VERSION ""

NS_ :

BS_:

BU_: EBOOST_CE TRCM_CE CGM_CE EPS_JR_CE MSB1_CE MSB2_CE ARS_CE SDM_CE EBCM_OBD_CE HCP_T_CE LCMS_CE APA_CE HCP_CE EOCM_F_CE MCP_C_CE MCP_B_CE MCP_A_CE FCM_CE ICCM_CE Dummy_CE TestTool_CE ACC_CE RDCM_CE EBCM_CE SADS_CE IMU_CE SAS_CE EPS_CE
VAL_TABLE_ vt_BooleanValues 1 "true" 0 "false" ;
VAL_TABLE_ RCMDSB_DTCStat 7 "Unused and Reserved3" 6 "Unused and Reserved2" 5 "Unused and Reserved1" 4 "Diagnostic Failed" 3 "Diagnostic Passed" 2 "No Status to Report" 1 "Critically Disabled" 0 "Not Supported " ;
VAL_TABLE_ RCMDSA_DTCStat 7 "Unused and Reserved3" 6 "Unused and Reserved2" 5 "Unused and Reserved1" 4 "Diagnostic Failed" 3 "Diagnostic Passed" 2 "No Status to Report" 1 "Critically Disabled" 0 "Not Supported " ;
VAL_TABLE_ RCMCII_DataIndx 31 "Unused and Reserved12" 30 "Unused and Reserved11" 29 "Unused and Reserved10" 28 "Unused and Reserved9" 27 "Unused and Reserved8" 26 "Unused and Reserved7" 25 "Unused and Reserved6" 24 "Unused and Reserved5" 23 "Unused and Reserved4" 22 "Unused and Reserved3" 21 "Unused and Reserved2" 20 "Unused and Reserved1" 19 "CVN Digit 4" 18 "CVN Digit 3" 17 "CVN Digit 2" 16 "CVN Digit 1" 15 "Calibration Identification Digit 16" 14 "Calibration Identification Digit 15" 13 "Calibration Identification Digit 14" 12 "Calibration Identification Digit 13" 11 "Calibration Identification Digit 12" 10 "Calibration Identification Digit 11" 9 "Calibration Identification Digit 10" 8 "Calibration Identification Digit 9" 7 "Calibration Identification Digit 8" 6 "Calibration Identification Digit 7" 5 "Calibration Identification Digit 6" 4 "Calibration Identification Digit 5" 3 "Calibration Identification Digit 4" 2 "Calibration Identification Digit 3" 1 "Calibration Identification Digit 2" 0 "Calibration Identification Digit 1" ;
VAL_TABLE_ RCMCII_DataStat 1 "Data Available" 0 "Data Not Available" ;
VAL_TABLE_ RMPS_RngMtrDfltStat 3 "Default Functionality" 2 "Degraded Functionality" 1 "Full Functionality" 0 "Status Unknown " ;
VAL_TABLE_ RMPS_RngMtrPstnM 1 "Use data" 0 "Do not use data" ;
VAL_TABLE_ RMPS_RngMtrPstn 15 "Unused and Reserved4" 14 "Unused and Reserved3" 13 "Unused and Reserved2" 12 "Unused and Reserved1" 11 "Beyond Drive Reset" 10 "Drive Reset" 9 "Between Drive and Drive Reset" 8 "Drive" 7 "Between Neutral and Drive" 6 "Neutral" 5 "Between Reverse and Neutral" 4 "Reverse" 3 "Between Park and Reverse" 2 "Park" 1 "Beyond Park" 0 "Motor Position Unavailable " ;
VAL_TABLE_ ElcShftActnRngCmd 7 "Unused and Reserved2" 6 "Unused and Reserved1" 5 "Drive Reset" 4 "Drive " 3 "Neutral" 2 "Reverse" 1 "Park" 0 "No Action " ;
VAL_TABLE_ EBrkAstToBrkSysDiagMd 3 "Diagnostic Mode 3" 2 "Diagnostic Mode 2" 1 "Diagnostic Mode 1" 0 "No Diagnostic Mode" ;
VAL_TABLE_ EBrkAstOtptRdPosStat 2 "Faulted" 1 "Not Initialized" 0 "Normal" ;
VAL_TABLE_ BrkSysToEBOOSTDiagMd 3 "Diagnostic Mode 3" 2 "Diagnostic Mode 2" 1 "Diagnostic Mode 1" 0 "No Diagnostic Mode" ;
VAL_TABLE_ APABR_AutBrkRmpRt 2 "Full" 1 "Light" 0 "None" ;
VAL_TABLE_ APABR_AutBrkRqTyp 8 "Object Detected/Confirmation" 7 "Reserved" 6 "Reserved" 5 "Hold" 4 "Apply Park Brake" 3 "Brake Per Requested Decel" 2 "Reserved" 1 "Prefill" 0 "None" ;
VAL_TABLE_ APABR_APA2Pstat 4 "Active" 3 "Enabled" 2 "Standby enabled" 1 "Disabled" 0 "Off" ;
VAL_TABLE_ BrkSyFrcBdgTgtRqActSt 2 "Active" 1 "Hold" 0 "Inactive" ;
VAL_TABLE_ SeatBltPerfMdRq 7 "Performance Mode 7" 6 "Performance Mode 6" 5 "Performance Mode 5" 4 "Performance Mode 4" 3 "Performance Mode 3" 2 "Performance Mode 2" 1 "Performance Mode 1" 0 "No Action" ;
VAL_TABLE_ ARSAnglCmdAct 3 "Active" 2 "Unused" 1 "Inactive with Energy Saving" 0 "Inactive" ;
VAL_TABLE_ EBrkAstStat 7 "Faulted" 6 "Temporarily Failed" 5 "Not Used" 4 "Not Used" 3 "Not Used" 2 "Normal" 1 "Initializing" 0 "Not Initialized" ;
VAL_TABLE_ StgSysPerfMdRq 7 "Performance Mode 7" 6 "Performance Mode 6" 5 "Performance Mode 5" 4 "Performance Mode 4" 3 "Performance Mode 3" 2 "Performance Mode 2" 1 "Performance Mode 1" 0 "No Action" ;
VAL_TABLE_ ChsSysTrnsShfBhvRq 7 "Upshift" 6 "Downshift" 5 "Minimum Inertia" 4 "Immediate Mode" 3 "Inhibit Shift" 2 "Inhibit Upshift" 1 "Inhibit Downshift" 0 "No Action" ;
VAL_TABLE_ RatDiagnAutoBrkReq 0 "True" 1 "False" ;
VAL_TABLE_ RatDiagnAutoBrkReqTyp 5 "Hold" 0 "None" 1 "Light" 2 "Virtual Bumper" 3 "Full" 4 "Integrated Brake Assist" ;
VAL_TABLE_ RrAxlSta 3 "Permanently Failed" 2 "Temporary Limited" 1 "Temporary Inhibit" 0 "Normal" ;
VAL_TABLE_ SecAxlStat 3 "Permanently Failed" 2 "Temporary Limited" 1 "Temporary Inhibit" 0 "Normal" ;
VAL_TABLE_ SecAxlCtrlMod 1 "External" 0 "Internal" ;
VAL_TABLE_ RrAxlOpeMod 3 "Unknown" 2 "Locked" 1 "Active" 0 "Open" ;
VAL_TABLE_ RrAxlCtrlMod 1 "External" 0 "Internal" ;
VAL_TABLE_ TransTUDMdStat 2 "Electronic Range Select Active" 1 "Driver Shift Control Active" 0 "No Activation" ;
VAL_TABLE_ TrnShftPtrnActStat 6 "PT Protection Pattern Active" 5 "PT Non-Protection Pattern Active" 4 "Shift Pattern 4 Active" 3 "Shift Pattern 3 Active" 2 "Shift Pattern 2 Active" 1 "Shift Pattern 1 Active" 0 "Default Shift Pattern Active" ;
VAL_TABLE_ NotEventSta 2 "Pretensioner Deployment Event" 1 "Near Deployment Event" 0 "No Event" 3 "Airbag Deployment Event" ;
VAL_TABLE_ SASCalRq 1 "Calibrate Sensor" 0 "No Action" ;
VAL_TABLE_ VDAvailability 1 "VirtualDeviceAvailable" 0 "VirtualDeviceUnavailable" ;
VAL_TABLE_ DistRollCntAvgDrvnM 1 "Use Data" 0 "Don't Use Data" ;
VAL_TABLE_ VhDynRRWhlSt 2 "Exiting Active" 1 "Active" 0 "Inactive" ;
VAL_TABLE_ VhDynRLWhlSt 2 "Exiting Active" 1 "Active" 0 "Inactive" ;
VAL_TABLE_ VhDynFRWhlSt 2 "Exiting Active" 1 "Active" 0 "Inactive" ;
VAL_TABLE_ VhDynFLWhlSt 2 "Exiting Active" 1 "Active" 0 "Inactive" ;
VAL_TABLE_ VehStabEnhmntMd 2 "Competitive" 1 "Normal" 0 "Off" ;
VAL_TABLE_ VehStabEnhmntStat 4 "Not Ready" 3 "Warming Up" 2 "Fault" 1 "Active" 0 "Inactive" ;
VAL_TABLE_ DTCI_DTCFaultType 3 "Type C" 2 "Type B" 1 "Type A" 0 "Not Supported" ;
VAL_TABLE_ DistRollCntAvgDrvnSrc 1 "Wheel Speed" 0 "Transmission Output Speed" ;
VAL_TABLE_ VehSpdAvgDrvnSrc 1 "Wheel Speed" 0 "Transmission Output Speed" ;
VAL_TABLE_ TrnsSftMdStat 3 "Automatic Grade Braking Mode" 2 "Lift-Foot Cornering Mode" 1 "Performance Mode" 0 "No Override Mode" ;
VAL_TABLE_ StrWhlAngSenCalStat 2 "Calibrated" 1 "Estimated" 0 "Unknown" ;
VAL_TABLE_ EngSpdStat 3 "Invalid" 1 "Degraded Operation" 0 "Normal Operation" ;
VAL_TABLE_ TrnsShftLvrPos 15 "Lever Position Unknown" 11 "Forward Range H" 10 "Forward Range G" 9 "Forward Range F" 8 "Forward Range E" 7 "Forward Range D" 6 "Forward Range C" 5 "Forward Range B" 4 "Forward Range A" 3 "Neutral Range" 2 "Reverse Range" 1 "Park Range" 0 "Between Ranges" ;
VAL_TABLE_ TransEstGear 15 "Park Gear" 14 "Reverse Gear" 13 "Neutral Gear" 12 "CVT Forward Gear" 11 "EVT Mode 2" 10 "EVT Mode 1" 8 "Eighth Gear" 7 "Seventh Gear" 6 "Sixth Gear" 5 "Fifth Gear" 4 "Fourth Gear" 3 "Third Gear" 2 "Second Gear" 1 "First Gear" 0 "Not Supported" ;
VAL_TABLE_ SysBkUpPwrMd 3 "Crank Request" 2 "Run" 1 "Accessory" 0 "Off" ;
VAL_TABLE_ SysPwrMd 3 "Crank Request" 2 "Run" 1 "Accessory" 0 "Off" ;
VAL_TABLE_ SprTireSt 2 "Spare Detected" 1 "No Spare Detected" 0 "Undetermined" ;
VAL_TABLE_ VhDynCntlSysSt 7 "Driver Disabled" 6 "Enhanced Operation" 5 "Calibrating" 4 "Warming Up" 3 "Permanently Failed" 2 "Temporarily Inhibited" 1 "Reduced Function" 0 "Normal Operation" ;
VAL_TABLE_ ValidityStates 1 "Invalid" 0 "Valid" ;

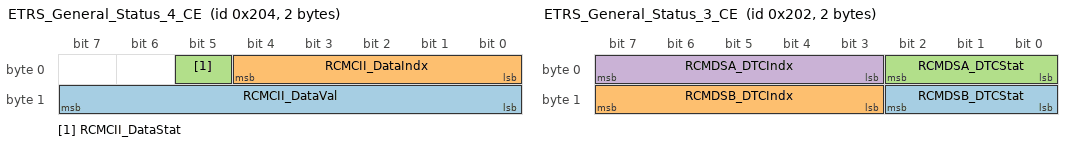
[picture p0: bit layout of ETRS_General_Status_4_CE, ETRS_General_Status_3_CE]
BO_ 516 ETRS_General_Status_4_CE: 2 TRCM_CE
 SG_ RCMCII_DataVal : 15|8@0+ (1,0) [0|255] ""  ICCM_CE
 SG_ RCMCII_DataIndx : 4|5@0+ (1,0) [0|31] ""  ICCM_CE
 SG_ RCMCII_DataStat : 5|1@0+ (1,0) [0|1] ""  ICCM_CE

BO_ 514 ETRS_General_Status_3_CE: 2 TRCM_CE
 SG_ RCMDSB_DTCStat : 10|3@0+ (1,0) [0|7] ""  ICCM_CE
 SG_ RCMDSB_DTCIndx : 15|5@0+ (1,0) [0|31] "N/A"  ICCM_CE
 SG_ RCMDSA_DTCStat : 2|3@0+ (1,0) [0|7] ""  ICCM_CE
 SG_ RCMDSA_DTCIndx : 7|5@0+ (1,0) [0|31] "N/A"  ICCM_CE

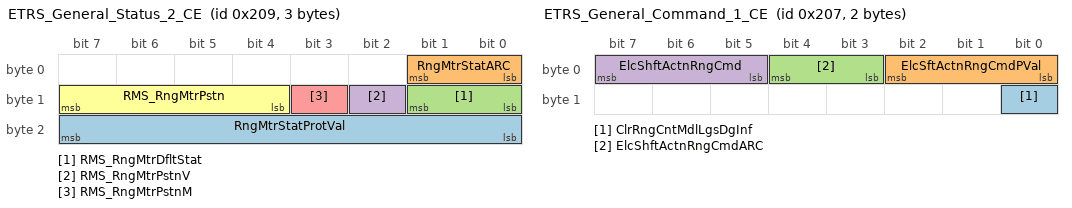
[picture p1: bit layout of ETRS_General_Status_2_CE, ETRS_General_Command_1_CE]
BO_ 521 ETRS_General_Status_2_CE: 3 TRCM_CE
 SG_ RngMtrStatProtVal : 23|8@0+ (1,0) [0|255] ""  ICCM_CE
 SG_ RngMtrStatARC : 1|2@0+ (1,0) [0|3] ""  ICCM_CE
 SG_ RMS_RngMtrDfltStat : 9|2@0+ (1,0) [0|3] ""  ICCM_CE
 SG_ RMS_RngMtrPstnV : 10|1@0+ (1,0) [0|1] ""  ICCM_CE
 SG_ RMS_RngMtrPstnM : 11|1@0+ (1,0) [0|1] ""  ICCM_CE
 SG_ RMS_RngMtrPstn : 15|4@0+ (1,0) [0|15] ""  ICCM_CE

BO_ 519 ETRS_General_Command_1_CE: 2 ICCM_CE
 SG_ ClrRngCntMdlLgsDgInf : 8|1@0+ (1,0) [0|1] ""  TRCM_CE
 SG_ ElcSftActnRngCmdPVal : 2|3@0+ (1,0) [0|7] ""  TRCM_CE
 SG_ ElcShftActnRngCmdARC : 4|2@0+ (1,0) [0|3] ""  TRCM_CE
 SG_ ElcShftActnRngCmd : 7|3@0+ (1,0) [0|7] ""  TRCM_CE

BO_ 543 Electric_Brake_System_Info_3_CE: 6 EBOOST_CE

BO_ 1931 DTC_Triggered_78B_CE: 7 SAS_CE
 SG_ DTCI_CodeSupported_78B : 40|1@0+ (1,0) [0|1] ""  TestTool_CE
 SG_ DTCI_CurrentStatus_78B : 41|1@0+ (1,0) [0|1] ""  TestTool_CE
 SG_ DTCI_DTCFailType_78B : 39|8@0+ (1,0) [0|255] ""  TestTool_CE
 SG_ DTCI_DTCFaultType_78B : 55|8@0+ (1,0) [0|255] ""  TestTool_CE
 SG_ DTCI_DTCNumber_78B : 23|16@0+ (1,0) [0|65535] ""  TestTool_CE
 SG_ DTCI_DTCSource_78B : 15|8@0+ (1,0) [0|255] ""  TestTool_CE
 SG_ DTCI_DTCTriggered_78B : 0|1@0+ (1,0) [0|1] ""  TestTool_CE
 SG_ DTCI_HistStat_78B : 44|1@0+ (1,0) [0|1] ""  TestTool_CE
 SG_ DTCI_TstFldCdClrdStat_78B : 43|1@0+ (1,0) [0|1] ""  TestTool_CE
 SG_ DTCI_TstFldPwrUpSt_78B : 46|1@0+ (1,0) [0|1] ""  TestTool_CE
 SG_ DTCI_TstNPsdCdClrdSt_78B : 42|1@0+ (1,0) [0|1] ""  TestTool_CE
 SG_ DTCI_TstNPsdPwrUpSt_78B : 45|1@0+ (1,0) [0|1] ""  TestTool_CE
 SG_ DTCIUnused1_78B : 7|1@0+ (1,0) [0|1] ""  TestTool_CE
 SG_ DTCIUnused2_78B : 6|1@0+ (1,0) [0|1] ""  TestTool_CE
 SG_ DTCIUnused3_78B : 5|1@0+ (1,0) [0|1] ""  TestTool_CE
 SG_ DTCIUnused4_78B : 4|1@0+ (1,0) [0|1] ""  TestTool_CE
 SG_ DTCIUnused5_78B : 3|1@0+ (1,0) [0|1] ""  TestTool_CE
 SG_ DTCIUnused6_78B : 2|1@0+ (1,0) [0|1] ""  TestTool_CE
 SG_ DTCIUnused7_78B : 1|1@0+ (1,0) [0|1] ""  TestTool_CE
 SG_ DTCI_WrnIndRqdSt_78B : 47|1@0+ (1,0) [0|1] ""  TestTool_CE

BO_ 1923 DTC_Triggered_783_CE: 7 MSB2_CE
 SG_ DTCI_WrnIndRqdSt_783 : 47|1@0+ (1,0) [0|1] ""  TestTool_CE
 SG_ DTCI_TstNPsdPwrUpSt_783 : 45|1@0+ (1,0) [0|1] ""  TestTool_CE
 SG_ DTCI_TstNPsdCdClrdSt_783 : 42|1@0+ (1,0) [0|1] ""  TestTool_CE
 SG_ DTCI_TstFldPwrUpSt_783 : 46|1@0+ (1,0) [0|1] ""  TestTool_CE
 SG_ DTCI_TstFldCdClrdStat_783 : 43|1@0+ (1,0) [0|1] ""  TestTool_CE
 SG_ DTCI_HistStat_783 : 44|1@0+ (1,0) [0|1] ""  TestTool_CE
 SG_ DTCI_DTCTriggered_783 : 0|1@0+ (1,0) [0|1] ""  TestTool_CE
 SG_ DTCI_DTCSource_783 : 15|8@0+ (1,0) [0|255] ""  TestTool_CE
 SG_ DTCI_DTCNumber_783 : 23|16@0+ (1,0) [0|65535] ""  TestTool_CE
 SG_ DTCI_DTCFaultType_783 : 55|8@0+ (1,0) [0|255] ""  TestTool_CE
 SG_ DTCI_DTCFailType_783 : 39|8@0+ (1,0) [0|255] ""  TestTool_CE
 SG_ DTCI_CurrentStatus_783 : 41|1@0+ (1,0) [0|1] ""  TestTool_CE
 SG_ DTCI_CodeSupported_783 : 40|1@0+ (1,0) [0|1] ""  TestTool_CE
 SG_ DTCIUnused7_783 : 1|1@0+ (1,0) [0|1] ""  TestTool_CE
 SG_ DTCIUnused6_783 : 2|1@0+ (1,0) [0|1] ""  TestTool_CE
 SG_ DTCIUnused5_783 : 3|1@0+ (1,0) [0|1] ""  TestTool_CE
 SG_ DTCIUnused4_783 : 4|1@0+ (1,0) [0|1] ""  TestTool_CE
 SG_ DTCIUnused3_783 : 5|1@0+ (1,0) [0|1] ""  TestTool_CE
 SG_ DTCIUnused2_783 : 6|1@0+ (1,0) [0|1] ""  TestTool_CE
 SG_ DTCIUnused1_783 : 7|1@0+ (1,0) [0|1] ""  TestTool_CE

BO_ 1922 DTC_Triggered_782_CE: 7 MSB1_CE
 SG_ DTCI_WrnIndRqdSt_782 : 47|1@0+ (1,0) [0|1] ""  TestTool_CE
 SG_ DTCIUnused7_782 : 1|1@0+ (1,0) [0|1] ""  TestTool_CE
 SG_ DTCIUnused6_782 : 2|1@0+ (1,0) [0|1] ""  TestTool_CE
 SG_ DTCIUnused5_782 : 3|1@0+ (1,0) [0|1] ""  TestTool_CE
 SG_ DTCIUnused4_782 : 4|1@0+ (1,0) [0|1] ""  TestTool_CE
 SG_ DTCIUnused3_782 : 5|1@0+ (1,0) [0|1] ""  TestTool_CE
 SG_ DTCIUnused2_782 : 6|1@0+ (1,0) [0|1] ""  TestTool_CE
 SG_ DTCIUnused1_782 : 7|1@0+ (1,0) [0|1] ""  TestTool_CE
 SG_ DTCI_TstNPsdPwrUpSt_782 : 45|1@0+ (1,0) [0|1] ""  TestTool_CE
 SG_ DTCI_TstNPsdCdClrdSt_782 : 42|1@0+ (1,0) [0|1] ""  TestTool_CE
 SG_ DTCI_TstFldPwrUpSt_782 : 46|1@0+ (1,0) [0|1] ""  TestTool_CE
 SG_ DTCI_TstFldCdClrdStat_782 : 43|1@0+ (1,0) [0|1] ""  TestTool_CE
 SG_ DTCI_HistStat_782 : 44|1@0+ (1,0) [0|1] ""  TestTool_CE
 SG_ DTCI_DTCTriggered_782 : 0|1@0+ (1,0) [0|1] ""  TestTool_CE
 SG_ DTCI_DTCSource_782 : 15|8@0+ (1,0) [0|255] ""  TestTool_CE
 SG_ DTCI_DTCNumber_782 : 23|16@0+ (1,0) [0|65535] ""  TestTool_CE
 SG_ DTCI_DTCFaultType_782 : 55|8@0+ (1,0) [0|255] ""  TestTool_CE
 SG_ DTCI_DTCFailType_782 : 39|8@0+ (1,0) [0|255] ""  TestTool_CE
 SG_ DTCI_CurrentStatus_782 : 41|1@0+ (1,0) [0|1] ""  TestTool_CE
 SG_ DTCI_CodeSupported_782 : 40|1@0+ (1,0) [0|1] ""  TestTool_CE

BO_ 1921 DTC_Triggered_781_CE: 7 IMU_CE
 SG_ DTCI_CurrentStatus_781 : 41|1@0+ (1,0) [0|1] ""  TestTool_CE
 SG_ DTCI_WrnIndRqdSt_781 : 47|1@0+ (1,0) [0|1] ""  TestTool_CE
 SG_ DTCIUnused7_781 : 1|1@0+ (1,0) [0|1] ""  TestTool_CE
 SG_ DTCIUnused6_781 : 2|1@0+ (1,0) [0|1] ""  TestTool_CE
 SG_ DTCIUnused5_781 : 3|1@0+ (1,0) [0|1] ""  TestTool_CE
 SG_ DTCIUnused4_781 : 4|1@0+ (1,0) [0|1] ""  TestTool_CE
 SG_ DTCIUnused3_781 : 5|1@0+ (1,0) [0|1] ""  TestTool_CE
 SG_ DTCIUnused2_781 : 6|1@0+ (1,0) [0|1] ""  TestTool_CE
 SG_ DTCIUnused1_781 : 7|1@0+ (1,0) [0|1] ""  TestTool_CE
 SG_ DTCI_TstNPsdPwrUpSt_781 : 45|1@0+ (1,0) [0|1] ""  TestTool_CE
 SG_ DTCI_TstNPsdCdClrdSt_781 : 42|1@0+ (1,0) [0|1] ""  TestTool_CE
 SG_ DTCI_TstFldPwrUpSt_781 : 46|1@0+ (1,0) [0|1] ""  TestTool_CE
 SG_ DTCI_TstFldCdClrdStat_781 : 43|1@0+ (1,0) [0|1] ""  TestTool_CE
 SG_ DTCI_HistStat_781 : 44|1@0+ (1,0) [0|1] ""  TestTool_CE
 SG_ DTCI_DTCTriggered_781 : 0|1@0+ (1,0) [0|1] ""  TestTool_CE
 SG_ DTCI_DTCSource_781 : 15|8@0+ (1,0) [0|255] ""  TestTool_CE
 SG_ DTCI_DTCNumber_781 : 23|16@0+ (1,0) [0|65535] ""  TestTool_CE
 SG_ DTCI_DTCFaultType_781 : 55|8@0+ (1,0) [0|255] ""  TestTool_CE
 SG_ DTCI_DTCFailType_781 : 39|8@0+ (1,0) [0|255] ""  TestTool_CE
 SG_ DTCI_CodeSupported_781 : 40|1@0+ (1,0) [0|1] ""  TestTool_CE

BO_ 2034 CCP_Data_Transmission_Object_CE: 8 Dummy_CE
 SG_ DgnInf : 7|64@0+ (1,0) [0|1.84467440737096E+019] ""  TestTool_CE

BO_ 2032 CCP_Command_Receive_Object_CE: 8 TestTool_CE
 SG_ DgnInf : 7|64@0+ (1,0) [0|1.84467440737096E+019] ""  Dummy_CE

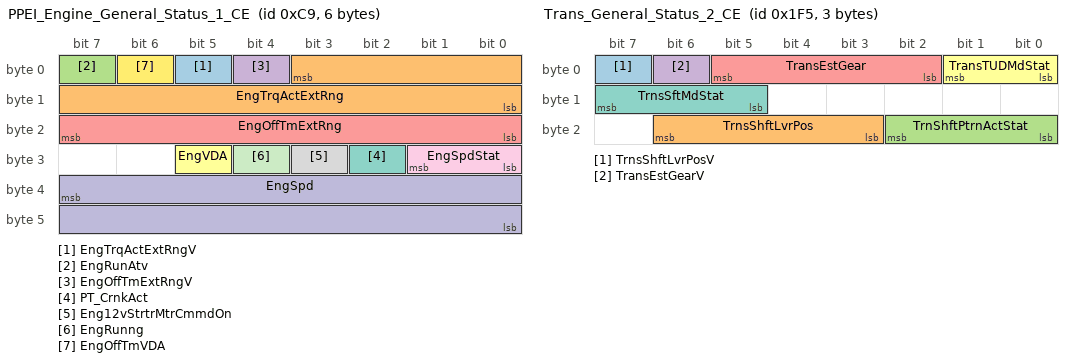
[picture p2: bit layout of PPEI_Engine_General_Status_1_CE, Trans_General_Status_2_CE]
BO_ 201 PPEI_Engine_General_Status_1_CE: 6 EBCM_CE
 SG_ EngTrqActExtRngV : 5|1@0+ (1,0) [0|1] ""  EPS_JR_CE
 SG_ EngTrqActExtRng : 3|12@0+ (0.5,-848) [-848|1199.5] "Nm"  EPS_JR_CE
 SG_ EngRunAtv : 7|1@0+ (1,0) [0|1] ""  SDM_CE,ARS_CE,EPS_JR_CE
 SG_ EngOffTmExtRngV : 4|1@0+ (1,0) [0|1] ""  RDCM_CE,EPS_JR_CE
 SG_ EngOffTmExtRng : 23|8@0+ (4,0) [0|1020] "min"  RDCM_CE,EPS_JR_CE
 SG_ EngVDA : 29|1@0+ (1,0) [0|1] ""  RDCM_CE
 SG_ PT_CrnkAct : 26|1@0+ (1,0) [0|1] ""  EPS_JR_CE
 SG_ Eng12vStrtrMtrCmmdOn : 27|1@0+ (1,0) [0|1] ""  EPS_JR_CE
 SG_ EngSpdStat : 25|2@0+ (1,0) [0|3] ""  EPS_JR_CE,ARS_CE
 SG_ EngSpd : 39|16@0+ (0.25,0) [0|16383.75] "rpm"  ARS_CE,EPS_JR_CE
 SG_ EngRunng : 28|1@0+ (1,0) [0|1] ""  RDCM_CE
 SG_ EngOffTmVDA : 6|1@0+ (1,0) [0|1] ""  EPS_JR_CE

BO_ 1300 PPEI_VIN_Digits_2_to_9_CE: 8 EBCM_CE
 SG_ VehIdNmDig2_9 : 7|64@0+ (1,0) [0|1] ""  EPS_JR_CE

BO_ 1249 PPEI_VIN_Digits_10_to_17_CE: 8 EBCM_CE
 SG_ VehIdNmDig10_17 : 7|64@0+ (1,0) [0|1] ""  EPS_JR_CE

BO_ 300 MSB2_Collision_Preparation_CE: 1 MSB2_CE
 SG_ MotStBlt2UnblIO : 0|1@0+ (1,0) [0|1] ""  MSB1_CE
 SG_ MotStBlt2FldIO : 1|1@0+ (1,0) [0|1] ""  MSB1_CE

BO_ 501 Trans_General_Status_2_CE: 3 EBCM_CE
 SG_ TrnsShftLvrPosV : 7|1@0+ (1,0) [0|1] ""  EPS_JR_CE,APA_CE
 SG_ TrnsShftLvrPos : 22|4@0+ (1,0) [0|15] ""  EPS_JR_CE,APA_CE
 SG_ TrnShftPtrnActStat : 18|3@0+ (1,0) [0|7] ""  EPS_JR_CE
 SG_ TransEstGearV : 6|1@0+ (1,0) [0|1] ""  MSB1_CE,MSB2_CE,FCM_CE,EPS_JR_CE
 SG_ TransEstGear : 5|4@0+ (1,0) [0|15] ""  MSB1_CE,MSB2_CE,FCM_CE,EPS_JR_CE
 SG_ TransTUDMdStat : 1|2@0+ (1,0) [0|3] ""  MSB1_CE,MSB2_CE
 SG_ TrnsSftMdStat : 15|3@0+ (1,0) [0|7] ""  MSB1_CE,MSB2_CE

BO_ 1920 DTC_Triggered_780_CE: 7 EPS_JR_CE
 SG_ DTCI_CurrentStatus_780 : 41|1@0+ (1,0) [0|1] ""  EBCM_OBD_CE,EBCM_CE
 SG_ DTCI_WrnIndRqdSt_780 : 47|1@0+ (1,0) [0|1] ""  EBCM_OBD_CE,EBCM_CE
 SG_ DTCIUnused7_780 : 1|1@0+ (1,0) [0|1] ""  EBCM_OBD_CE,EBCM_CE
 SG_ DTCIUnused6_780 : 2|1@0+ (1,0) [0|1] ""  EBCM_OBD_CE,EBCM_CE
 SG_ DTCIUnused5_780 : 3|1@0+ (1,0) [0|1] ""  EBCM_OBD_CE,EBCM_CE
 SG_ DTCIUnused4_780 : 4|1@0+ (1,0) [0|1] ""  EBCM_OBD_CE,EBCM_CE
 SG_ DTCIUnused3_780 : 5|1@0+ (1,0) [0|1] ""  EBCM_OBD_CE,EBCM_CE
 SG_ DTCIUnused2_780 : 6|1@0+ (1,0) [0|1] ""  EBCM_OBD_CE,EBCM_CE
 SG_ DTCIUnused1_780 : 7|1@0+ (1,0) [0|1] ""  EBCM_OBD_CE,EBCM_CE
 SG_ DTCI_TstNPsdPwrUpSt_780 : 45|1@0+ (1,0) [0|1] ""  EBCM_OBD_CE,EBCM_CE
 SG_ DTCI_TstNPsdCdClrdSt_780 : 42|1@0+ (1,0) [0|1] ""  EBCM_OBD_CE,EBCM_CE
 SG_ DTCI_TstFldPwrUpSt_780 : 46|1@0+ (1,0) [0|1] ""  EBCM_OBD_CE,EBCM_CE
 SG_ DTCI_TstFldCdClrdStat_780 : 43|1@0+ (1,0) [0|1] ""  EBCM_OBD_CE,EBCM_CE
 SG_ DTCI_HistStat_780 : 44|1@0+ (1,0) [0|1] ""  EBCM_OBD_CE,EBCM_CE
 SG_ DTCI_DTCTriggered_780 : 0|1@0+ (1,0) [0|1] ""  EBCM_OBD_CE,EBCM_CE
 SG_ DTCI_DTCSource_780 : 15|8@0+ (1,0) [0|255] ""  EBCM_OBD_CE,EBCM_CE
 SG_ DTCI_DTCNumber_780 : 23|16@0+ (1,0) [0|65535] ""  EBCM_OBD_CE,EBCM_CE
 SG_ DTCI_DTCFaultType_780 : 55|8@0+ (1,0) [0|255] ""  EBCM_OBD_CE,EBCM_CE
 SG_ DTCI_DTCFailType_780 : 39|8@0+ (1,0) [0|255] ""  EBCM_OBD_CE,EBCM_CE
 SG_ DTCI_CodeSupported_780 : 40|1@0+ (1,0) [0|1] ""  EBCM_OBD_CE,EBCM_CE

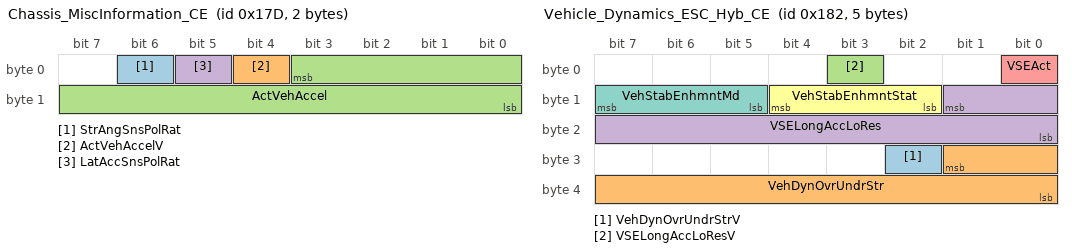
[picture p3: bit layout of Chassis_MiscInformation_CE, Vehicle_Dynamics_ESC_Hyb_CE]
BO_ 381 Chassis_MiscInformation_CE: 2 EBCM_CE
 SG_ StrAngSnsPolRat : 6|1@0+ (1,0) [0|1] ""  EPS_JR_CE,EPS_CE
 SG_ ActVehAccelV : 4|1@0+ (1,0) [0|1] ""  MSB1_CE,MSB2_CE
 SG_ ActVehAccel : 3|12@0- (0.01,0) [-20.48|20.47] "m/s^2"  MSB1_CE,MSB2_CE
 SG_ LatAccSnsPolRat : 5|1@0+ (1,0) [0|1] ""  EPS_JR_CE,EPS_CE

BO_ 386 Vehicle_Dynamics_ESC_Hyb_CE: 5 EBCM_CE
 SG_ VehDynOvrUndrStrV : 26|1@0+ (1,0) [0|1] ""  EPS_JR_CE,EPS_CE
 SG_ VehDynOvrUndrStr : 25|10@0- (0.5,0) [-256|255.5] "%"  EPS_JR_CE,EPS_CE
 SG_ VSELongAccLoResV : 3|1@0+ (1,0) [0|1] ""  EPS_CE,EPS_JR_CE
 SG_ VSELongAccLoRes : 9|10@0- (0.03,0) [-15.36|15.33] "m/s^2"  EPS_CE,EPS_JR_CE
 SG_ VSEAct : 0|1@0+ (1,0) [0|1] ""  RDCM_CE,EPS_JR_CE,MSB1_CE,MSB2_CE,EPS_CE
 SG_ VehStabEnhmntStat : 12|3@0+ (1,0) [0|7] ""  EPS_CE,MSB1_CE,MSB2_CE
 SG_ VehStabEnhmntMd : 15|3@0+ (1,0) [0|7] ""  MSB1_CE,MSB2_CE

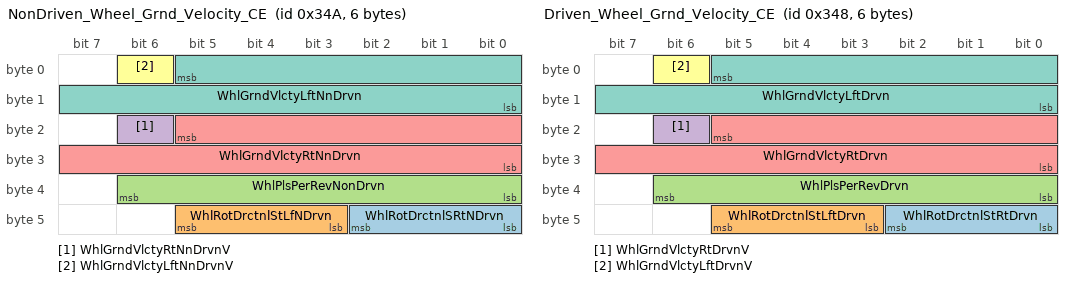
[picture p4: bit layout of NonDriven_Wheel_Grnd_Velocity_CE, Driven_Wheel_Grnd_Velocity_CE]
BO_ 842 NonDriven_Wheel_Grnd_Velocity_CE: 6 EBCM_CE
 SG_ WhlRotDrctnlSRtNDrvn : 42|3@0+ (1,0) [0|7] ""  ARS_CE,APA_CE
 SG_ WhlRotDrctnlStLfNDrvn : 45|3@0+ (1,0) [0|7] ""  ARS_CE,APA_CE
 SG_ WhlPlsPerRevNonDrvn : 38|7@0+ (1,0) [0|127] ""  ARS_CE,APA_CE,RDCM_CE,EPS_JR_CE,EPS_CE
 SG_ WhlGrndVlctyRtNnDrvnV : 22|1@0+ (1,0) [0|1] ""  ARS_CE,SDM_CE,APA_CE,EPS_JR_CE,MSB1_CE,MSB2_CE,EPS_CE
 SG_ WhlGrndVlctyRtNnDrvn : 21|14@0+ (0.03125,0) [0|511.96875] "km / h"  ARS_CE,SDM_CE,APA_CE,EPS_JR_CE,MSB1_CE,MSB2_CE,EPS_CE
 SG_ WhlGrndVlctyLftNnDrvnV : 6|1@0+ (1,0) [0|1] ""  ARS_CE,SDM_CE,EPS_JR_CE,MSB1_CE,MSB2_CE,EPS_CE,APA_CE
 SG_ WhlGrndVlctyLftNnDrvn : 5|14@0+ (0.03125,0) [0|511.96875] "km / h"  ARS_CE,SDM_CE,EPS_JR_CE,MSB1_CE,MSB2_CE,EPS_CE,APA_CE

BO_ 840 Driven_Wheel_Grnd_Velocity_CE: 6 EBCM_CE
 SG_ WhlRotDrctnlStRtDrvn : 42|3@0+ (1,0) [0|7] ""  ARS_CE,APA_CE
 SG_ WhlRotDrctnlStLftDrvn : 45|3@0+ (1,0) [0|7] ""  ARS_CE,APA_CE
 SG_ WhlPlsPerRevDrvn : 38|7@0+ (1,0) [0|127] ""  ARS_CE,APA_CE,RDCM_CE,EPS_JR_CE,EPS_CE
 SG_ WhlGrndVlctyRtDrvnV : 22|1@0+ (1,0) [0|1] ""  ARS_CE,SDM_CE,FCM_CE,EPS_JR_CE,APA_CE,MSB1_CE,MSB2_CE,EPS_CE
 SG_ WhlGrndVlctyRtDrvn : 21|14@0+ (0.03125,0) [0|511.96875] "km / h"  ARS_CE,SDM_CE,FCM_CE,EPS_JR_CE,APA_CE,MSB1_CE,MSB2_CE,EPS_CE
 SG_ WhlGrndVlctyLftDrvnV : 6|1@0+ (1,0) [0|1] ""  ARS_CE,SDM_CE,FCM_CE,EPS_JR_CE,MSB1_CE,MSB2_CE,EPS_CE,APA_CE
 SG_ WhlGrndVlctyLftDrvn : 5|14@0+ (0.03125,0) [0|511.96875] "km / h"  ARS_CE,SDM_CE,FCM_CE,EPS_JR_CE,MSB1_CE,MSB2_CE,EPS_CE,APA_CE

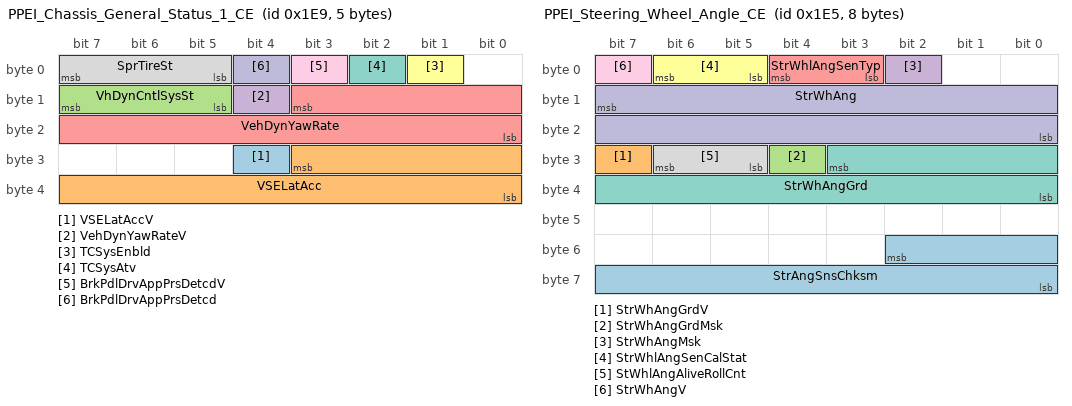
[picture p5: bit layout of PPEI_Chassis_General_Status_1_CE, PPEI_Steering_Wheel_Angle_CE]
BO_ 489 PPEI_Chassis_General_Status_1_CE: 5 EBCM_CE
 SG_ VSELatAccV : 28|1@0+ (1,0) [0|1] ""  MSB1_CE,MSB2_CE,EPS_JR_CE
 SG_ VSELatAcc : 27|12@0- (0.015625,0) [-32|31.984375] "m/s^2"  MSB1_CE,MSB2_CE,EPS_JR_CE
 SG_ VhDynCntlSysSt : 15|3@0+ (1,0) [0|7] ""  EPS_JR_CE
 SG_ VehDynYawRateV : 12|1@0+ (1,0) [0|1] ""  EPS_JR_CE,MSB1_CE,MSB2_CE
 SG_ VehDynYawRate : 11|12@0- (0.0625,0) [-128|127.9375] "deg/sec"  EPS_JR_CE,MSB1_CE,MSB2_CE
 SG_ TCSysEnbld : 1|1@0+ (1,0) [0|1] ""  EPS_JR_CE
 SG_ TCSysAtv : 2|1@0+ (1,0) [0|1] ""  EPS_JR_CE,RDCM_CE
 SG_ SprTireSt : 7|3@0+ (1,0) [0|7] ""  EPS_JR_CE
 SG_ BrkPdlDrvAppPrsDetcdV : 3|1@0+ (1,0) [0|1] ""  EPS_JR_CE
 SG_ BrkPdlDrvAppPrsDetcd : 4|1@0+ (1,0) [0|1] ""  EPS_JR_CE

BO_ 485 PPEI_Steering_Wheel_Angle_CE: 8 SAS_CE
 SG_ StrAngSnsChksm : 50|11@0+ (1,0) [0|2047] ""  ARS_CE,ACC_CE,APA_CE,FCM_CE,ICCM_CE,EPS_JR_CE,EPS_CE,EOCM_F_CE,EBCM_OBD_CE,EBCM_CE
 SG_ StrWhAngGrdV : 31|1@0+ (1,0) [0|1] ""  ARS_CE,FCM_CE,ICCM_CE,EPS_JR_CE,MSB1_CE,MSB2_CE,EPS_CE,SADS_CE,RDCM_CE,APA_CE,EOCM_F_CE,ACC_CE,SDM_CE,EBCM_OBD_CE,EBCM_CE
 SG_ StrWhAngGrdMsk : 28|1@0+ (1,0) [0|1] ""  ARS_CE,APA_CE,FCM_CE,ICCM_CE,EPS_JR_CE,EOCM_F_CE,EBCM_OBD_CE,EBCM_CE
 SG_ StrWhAngMsk : 2|1@0+ (1,0) [0|1] ""  ARS_CE,APA_CE,FCM_CE,ICCM_CE,EPS_JR_CE,EPS_CE,SADS_CE,EOCM_F_CE,SDM_CE,EBCM_OBD_CE,EBCM_CE
 SG_ StrWhlAngSenTyp : 4|2@0+ (1,0) [0|3] ""  ARS_CE,APA_CE,ACC_CE,FCM_CE,ICCM_CE,EBCM_OBD_CE,EBCM_CE,EPS_JR_CE,EPS_CE,EOCM_F_CE,SDM_CE
 SG_ StrWhlAngSenCalStat : 6|2@0+ (1,0) [0|3] ""  FCM_CE,ICCM_CE,EPS_JR_CE,ARS_CE,SADS_CE,RDCM_CE,APA_CE,EPS_CE,EOCM_F_CE,ACC_CE,SDM_CE,MSB1_CE,MSB2_CE,EBCM_OBD_CE,EBCM_CE
 SG_ StrWhAngGrd : 27|12@0- (1,0) [-2048|2047] "deg/sec"  ARS_CE,FCM_CE,ICCM_CE,EPS_JR_CE,MSB1_CE,MSB2_CE,SADS_CE,RDCM_CE,APA_CE,EPS_CE,EOCM_F_CE,ACC_CE,SDM_CE,EBCM_OBD_CE,EBCM_CE
 SG_ StWhlAngAliveRollCnt : 30|2@0+ (1,0) [0|3] ""  ARS_CE,ACC_CE,APA_CE,FCM_CE,ICCM_CE,EPS_JR_CE,EOCM_F_CE,SADS_CE,RDCM_CE,EPS_CE,SDM_CE,EBCM_OBD_CE,EBCM_CE
 SG_ StrWhAngV : 7|1@0+ (1,0) [0|1] ""  FCM_CE,ICCM_CE,EPS_JR_CE,ARS_CE,MSB1_CE,MSB2_CE,SADS_CE,RDCM_CE,APA_CE,EPS_CE,EOCM_F_CE,ACC_CE,SDM_CE,EBCM_OBD_CE,EBCM_CE
 SG_ StrWhAng : 15|16@0- (0.0625,0) [-2048|2047.9375] "deg"  ARS_CE,FCM_CE,ICCM_CE,EPS_JR_CE,MSB1_CE,MSB2_CE,SADS_CE,RDCM_CE,APA_CE,EPS_CE,EOCM_F_CE,ACC_CE,SDM_CE,EBCM_OBD_CE,EBCM_CE

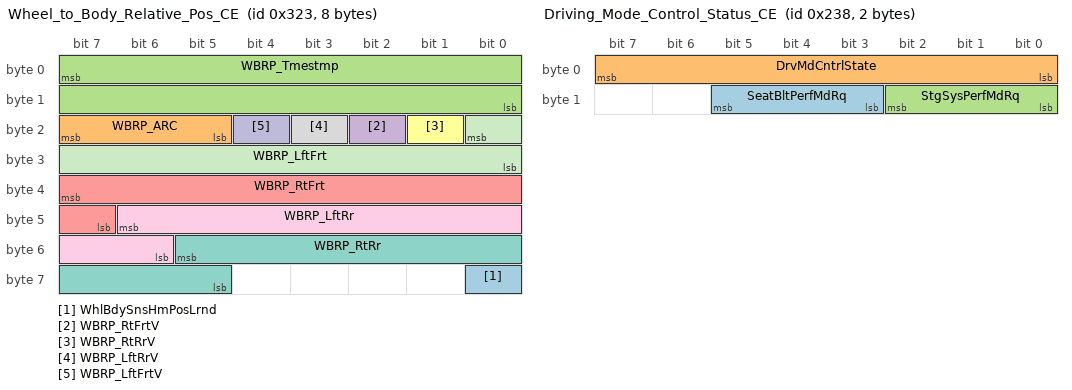
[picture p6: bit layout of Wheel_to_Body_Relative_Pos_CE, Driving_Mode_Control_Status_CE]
BO_ 803 Wheel_to_Body_Relative_Pos_CE: 8 SADS_CE
 SG_ WhlBdySnsHmPosLrnd : 56|1@0+ (1,0) [0|1] ""  EBCM_OBD_CE,EBCM_CE
 SG_ WBRP_ARC : 23|3@0+ (1,0) [0|7] "counts"  EBCM_OBD_CE,EBCM_CE
 SG_ WBRP_Tmestmp : 7|16@0+ (1,0) [0|65535] "micro sec"  EBCM_OBD_CE,EBCM_CE
 SG_ WBRP_RtFrtV : 18|1@0+ (1,0) [0|1] ""  EBCM_OBD_CE,EBCM_CE
 SG_ WBRP_RtFrt : 39|9@0- (1,0) [-256|255] "mm"  EBCM_OBD_CE,EBCM_CE
 SG_ WBRP_RtRrV : 17|1@0+ (1,0) [0|1] ""  EBCM_OBD_CE,EBCM_CE
 SG_ WBRP_RtRr : 53|9@0- (1,0) [-256|255] "mm"  EBCM_OBD_CE,EBCM_CE
 SG_ WBRP_LftRrV : 19|1@0+ (1,0) [0|1] ""  EBCM_OBD_CE,EBCM_CE
 SG_ WBRP_LftRr : 46|9@0- (1,0) [-256|255] "mm"  EBCM_OBD_CE,EBCM_CE
 SG_ WBRP_LftFrtV : 20|1@0+ (1,0) [0|1] ""  EBCM_OBD_CE,EBCM_CE
 SG_ WBRP_LftFrt : 16|9@0- (1,0) [-256|255] "mm"  EBCM_OBD_CE,EBCM_CE

BO_ 871 Chlng_From_FCM_Rsp_To_EBCM_CE: 4 FCM_CE
 SG_ FCMR_RptdChlng : 23|16@0+ (1,0) [0|65535] ""  EBCM_OBD_CE,EBCM_CE
 SG_ FCMR_Answr : 7|16@0+ (1,0) [0|65535] ""  EBCM_OBD_CE,EBCM_CE

BO_ 873 Chlng_From_EBCM_Rsp_To_FCM_CE: 2 EBCM_CE
 SG_ ElecBrkCntlMdlChlng : 7|16@0+ (1,0) [0|65535] ""  FCM_CE

BO_ 568 Driving_Mode_Control_Status_CE: 2 EBCM_CE
 SG_ SeatBltPerfMdRq : 13|3@0+ (1,0) [0|7] ""  MSB1_CE,MSB2_CE
 SG_ DrvMdCntrlState : 7|8@0+ (1,0) [0|255] ""  EPS_JR_CE
 SG_ StgSysPerfMdRq : 10|3@0+ (1,0) [0|7] ""  EPS_JR_CE

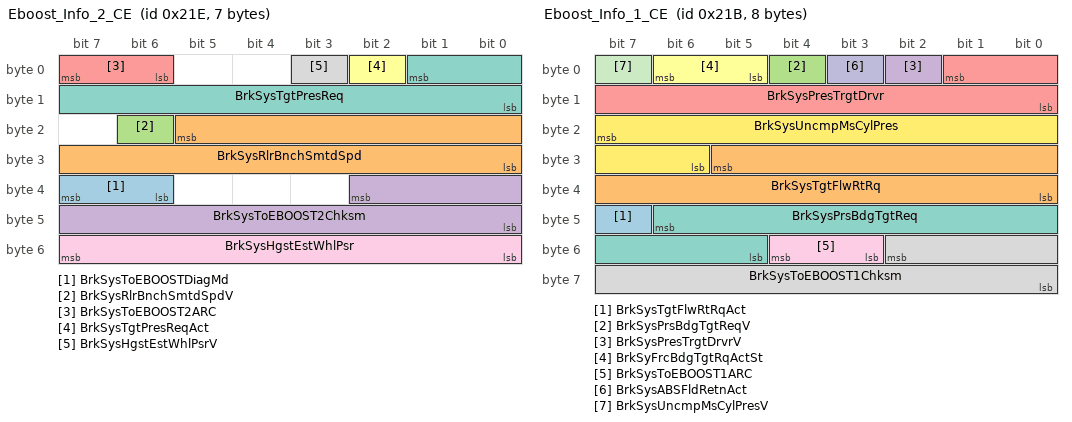
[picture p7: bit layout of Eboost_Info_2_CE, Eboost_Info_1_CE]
BO_ 542 Eboost_Info_2_CE: 7 EBCM_CE
 SG_ BrkSysToEBOOSTDiagMd : 39|2@0+ (1,0) [0|3] ""  EBOOST_CE
 SG_ BrkSysRlrBnchSmtdSpd : 21|14@0+ (0.04,0) [0|655.32] "km/h"  EBOOST_CE
 SG_ BrkSysRlrBnchSmtdSpdV : 22|1@0+ (1,0) [0|1] ""  EBOOST_CE
 SG_ BrkSysToEBOOST2Chksm : 34|11@0+ (1,0) [0|2047] ""  EBOOST_CE
 SG_ BrkSysToEBOOST2ARC : 7|2@0+ (1,0) [0|3] ""  EBOOST_CE
 SG_ BrkSysTgtPresReqAct : 2|1@0+ (1,0) [0|1] ""  EBOOST_CE
 SG_ BrkSysTgtPresReq : 1|10@0+ (0.2,0) [0|204.6] "bar"  EBOOST_CE
 SG_ BrkSysHgstEstWhlPsrV : 3|1@0+ (1,0) [0|1] ""  EBOOST_CE
 SG_ BrkSysHgstEstWhlPsr : 55|8@0+ (1,0) [0|255] "bar"  EBOOST_CE

BO_ 539 Eboost_Info_1_CE: 8 EBCM_CE
 SG_ BrkSysTgtFlwRtRqAct : 47|1@0+ (1,0) [0|1] "N/A"  EBOOST_CE
 SG_ BrkSysTgtFlwRtRq : 29|14@0- (0.0078125,0) [-64|63.9921875] "ml/s"  EBOOST_CE
 SG_ BrkSysPrsBdgTgtReqV : 4|1@0+ (1,0) [0|1] ""  EBOOST_CE
 SG_ BrkSysPresTrgtDrvrV : 2|1@0+ (1,0) [0|1] ""  EBOOST_CE
 SG_ BrkSysPresTrgtDrvr : 1|10@0+ (0.25,0) [0|255.75] "bar"  EBOOST_CE
 SG_ BrkSyFrcBdgTgtRqActSt : 6|2@0+ (1,0) [0|3] ""  EBOOST_CE
 SG_ BrkSysPrsBdgTgtReq : 46|10@0+ (0.25,0) [0|255.75] "bar"  EBOOST_CE
 SG_ BrkSysToEBOOST1Chksm : 50|11@0+ (1,0) [0|2047] ""  EBOOST_CE
 SG_ BrkSysToEBOOST1ARC : 52|2@0+ (1,0) [0|3] ""  EBOOST_CE
 SG_ BrkSysABSFldRetnAct : 3|1@0+ (1,0) [0|1] ""  EBOOST_CE
 SG_ BrkSysUncmpMsCylPresV : 7|1@0+ (1,0) [0|1] ""  EBOOST_CE
 SG_ BrkSysUncmpMsCylPres : 23|10@0+ (0.3,-30) [-30|276.9] "bar"  EBOOST_CE

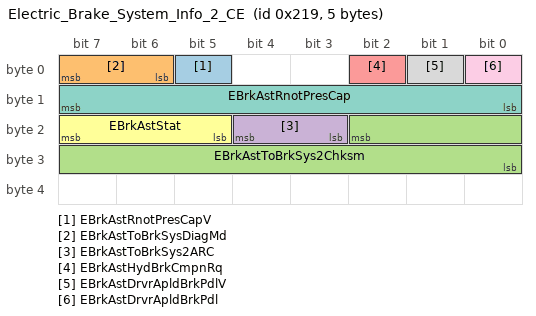
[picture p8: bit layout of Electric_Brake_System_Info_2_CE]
BO_ 537 Electric_Brake_System_Info_2_CE: 5 EBOOST_CE
 SG_ EBrkAstRnotPresCapV : 5|1@0+ (1,0) [0|1] ""  EBCM_OBD_CE,EBCM_CE
 SG_ EBrkAstToBrkSysDiagMd : 7|2@0+ (1,0) [0|3] ""  EBCM_OBD_CE,EBCM_CE
 SG_ EBrkAstToBrkSys2Chksm : 18|11@0+ (1,0) [0|2047] ""  EBCM_OBD_CE,EBCM_CE
 SG_ EBrkAstToBrkSys2ARC : 20|2@0+ (1,0) [0|3] ""  EBCM_OBD_CE,EBCM_CE
 SG_ EBrkAstHydBrkCmpnRq : 2|1@0+ (1,0) [0|1] ""  EBCM_OBD_CE,EBCM_CE
 SG_ EBrkAstStat : 23|3@0+ (1,0) [0|7] ""  EBCM_OBD_CE,EBCM_CE
 SG_ EBrkAstRnotPresCap : 15|8@0+ (1,0) [0|255] "bar"  EBCM_OBD_CE,EBCM_CE
 SG_ EBrkAstDrvrApldBrkPdlV : 1|1@0+ (1,0) [0|1] ""  EBCM_OBD_CE,EBCM_CE
 SG_ EBrkAstDrvrApldBrkPdl : 0|1@0+ (1,0) [0|1] ""  EBCM_OBD_CE,EBCM_CE

BO_TX_BU_ 201 : EBCM_OBD_CE,EBCM_CE;
BO_TX_BU_ 1300 : EBCM_OBD_CE,EBCM_CE;
BO_TX_BU_ 1249 : EBCM_OBD_CE,EBCM_CE;
BO_TX_BU_ 501 : EBCM_OBD_CE,EBCM_CE;
BO_TX_BU_ 381 : EBCM_OBD_CE,EBCM_CE;
BO_TX_BU_ 386 : EBCM_OBD_CE,EBCM_CE;
BO_TX_BU_ 842 : EBCM_OBD_CE,EBCM_CE;
BO_TX_BU_ 840 : EBCM_OBD_CE,EBCM_CE;
BO_TX_BU_ 489 : EBCM_OBD_CE,EBCM_CE;
BO_TX_BU_ 485 : EPS_CE,EBCM_OBD_CE,EBCM_CE,EPS_JR_CE,SAS_CE;
BO_TX_BU_ 873 : EBCM_OBD_CE,EBCM_CE;
BO_TX_BU_ 568 : EBCM_OBD_CE,EBCM_CE;
BO_TX_BU_ 542 : EBCM_OBD_CE,EBCM_CE;
BO_TX_BU_ 539 : EBCM_OBD_CE,EBCM_CE;

CM_ "Chassis Expansion (High Speed)
CE  bus is affected in Version 17.17.107  [Lakshmi Udaya,13 Sept 2013]";
CM_ BU_ EBOOST_CE "Electric Brake Booster";
CM_ BU_ TRCM_CE "Transmission Range Control Module";
CM_ BU_ CGM_CE "Communication Gateway";
CM_ BU_ EPS_JR_CE "Electronic Power Steering (For OPEL Jounior Program)";
CM_ BU_ MSB1_CE "Motorized Seat Belt";
CM_ BU_ MSB2_CE "Motorized Seat Belt 2";
CM_ BU_ ARS_CE "Active Rear Steering";
CM_ BU_ SDM_CE "Sensing & Diagnostic Module (Airbag)";
CM_ BU_ EBCM_OBD_CE "Electronic Brake Control Module";
CM_ BU_ HCP_T_CE "Hybrid Control Processor with up-integrated Trans and Motor Controls";
CM_ BU_ LCMS_CE "Low Speed Collision Mitigation System";
CM_ BU_ APA_CE "Advanced Parking Aid 
Mutually exklusive with EOCM_R_CE";
CM_ BU_ HCP_CE "Hybrid Control Processor";
CM_ BU_ EOCM_F_CE "External Object Control Module - Front";
CM_ BU_ MCP_C_CE "Motor Control Processor C
";
CM_ BU_ MCP_B_CE "Motor Control Processor B (part of TPIM-Traction Power Inverter Module)
";
CM_ BU_ MCP_A_CE "Motor Control Processor A(part of TPIM-Traction Powertrain Inverter Module)";
CM_ BU_ FCM_CE "Front Camera Module (on CE Bus for LCMS)";
CM_ BU_ ICCM_CE "Integrated Chassis Control Module";
CM_ BU_ Dummy_CE "This is for avoid signle ended signalling";
CM_ BU_ ACC_CE "Adaptive Cruise Control";
CM_ BU_ RDCM_CE "Rear Drive Control Module";
CM_ BU_ EBCM_CE "Electronic Brake Control Module";
CM_ BU_ SADS_CE "Semi Active Damping System";
CM_ BU_ IMU_CE "Inertia Measurement Unit";
CM_ BU_ SAS_CE "Steering Angle Sensor";
CM_ BU_ EPS_CE "Electronic Power Steering";
CM_ SG_ 1931 DTCI_DTCFailType_78B "Assigned per GMW3110, Appendix E";
CM_ SG_ 1931 DTCI_DTCFaultType_78B "Based on Powertrain definition.  Not expected to be supported by all devices.";
CM_ SG_ 1931 DTCI_DTCSource_78B "This shall be equal to the Diagnostic Address of the transmittting device.";
CM_ SG_ 1923 DTCI_DTCSource_783 "This shall be equal to the Diagnostic Address of the transmittting device.";
CM_ SG_ 1923 DTCI_DTCFaultType_783 "Based on Powertrain definition.  Not expected to be supported by all devices.";
CM_ SG_ 1923 DTCI_DTCFailType_783 "Assigned per GMW3110, Appendix E";
CM_ SG_ 1922 DTCI_DTCSource_782 "This shall be equal to the Diagnostic Address of the transmittting device.";
CM_ SG_ 1922 DTCI_DTCFaultType_782 "Based on Powertrain definition.  Not expected to be supported by all devices.";
CM_ SG_ 1922 DTCI_DTCFailType_782 "Assigned per GMW3110, Appendix E";
CM_ SG_ 1921 DTCI_DTCSource_781 "This shall be equal to the Diagnostic Address of the transmittting device.";
CM_ SG_ 1921 DTCI_DTCFaultType_781 "Based on Powertrain definition.  Not expected to be supported by all devices.";
CM_ SG_ 1921 DTCI_DTCFailType_781 "Assigned per GMW3110, Appendix E";
CM_ SG_ 201 EngRunAtv "Indication from powertrain that the engine is running (Has RPM > 0)";
CM_ SG_ 1300 VehIdNmDig2_9 "Desc: 8 ASCII Characters";
CM_ SG_ 1249 VehIdNmDig10_17 "Desc: 8 ASCII Characters";
CM_ SG_ 501 TrnShftPtrnActStat "(PT = Powertrain)";
CM_ SG_ 1920 DTCI_DTCSource_780 "This shall be equal to the Diagnostic Address of the transmittting device.";
CM_ SG_ 1920 DTCI_DTCFaultType_780 "Based on Powertrain definition.  Not expected to be supported by all devices.";
CM_ SG_ 1920 DTCI_DTCFailType_780 "Assigned per GMW3110, Appendix E";
CM_ BO_ 485 "6443-Power Steering Indication On in this frame not used by GlobalA /JD";
CM_ SG_ 803 WBRP_RtFrt "Negative values indicate Compression, Positive values indicate Extension.";
CM_ SG_ 803 WBRP_RtRr "Negative values indicate Compression, Positive values indicate Extension.";
CM_ SG_ 803 WBRP_LftRr "Negative values indicate Compression, Positive values indicate Extension.";
CM_ SG_ 803 WBRP_LftFrt "Negative values indicate Compression, Positive values indicate Extension.";
BA_DEF_  "BusType" STRING ;
BA_DEF_ SG_  "VNSigSLHS_VNReq" ENUM  "No","Yes";
BA_DEF_ SG_  "VNSigSLHSSharedDiagnostic" ENUM  "No","Yes";
BA_DEF_ SG_  "SignalType" STRING ;
BA_DEF_ SG_  "PacketOrder" INT 0 65535;
BA_DEF_ SG_  "SignalLongName" STRING ;
BA_DEF_ SG_  "GenSigStartValue" INT 0 65535;
BA_DEF_ SG_  "VNSigAllNodes" ENUM  "No","Yes";
BA_DEF_ SG_  "GenSigDeltaValue" INT 0 0;
BA_DEF_ SG_  "GenSigSendType" ENUM  "not used","not used","not used","not used","not used","not used","not used","NoSigSendType","not used","not used","OnAnyChange","OnChangeIfActive","OnDelta";
BA_DEF_ SG_  "GenSigSendOnInit" ENUM  "Not Initialized","Application","Handler";
BA_DEF_ BO_  "AppGenMsgCycleTime" INT 0 0;
BA_DEF_ BO_  "GenMsgILSupport" ENUM  "No","Yes";
BA_DEF_ BO_  "TpApplType" STRING ;
BA_DEF_ BO_  "Prio" INT 0 7;
BA_DEF_ BO_  "MessageSubnet" ENUM  "LS","MS","HS","CE","PE","HV","FO","S1","HE","LE","HE2";
BA_DEF_ BO_  "GenMsgMandatoryToSupervision" ENUM  "No","Yes";
BA_DEF_ BO_  "DiagState" ENUM  "No","Yes";
BA_DEF_ BO_  "GenMsgDelayTime" INT 0 100000;
BA_DEF_ BO_  "GenMsgCycleTime" INT 0 100000;
BA_DEF_ BO_  "GenMsgSendType" ENUM  "cyclicX","spontanX","cyclicIfActiveX","spontanWithDelay","cyclicAndSpontanX","cyclicAndSpontanWithDelay","spontanWithRepitition","cyclicIfActiveAndSpontanWD";
BA_DEF_ BO_  "DiagResponse" ENUM  "No","Yes";
BA_DEF_ BO_  "DiagRequest" ENUM  "No","Yes";
BA_DEF_ BO_  "NmMessage" ENUM  "No","Yes";
BA_DEF_ BU_  "MessageManagerUsed" ENUM  "No","Yes";
BA_DEF_ BU_  "NmNode" ENUM  "No","Yes";
BA_DEF_ BU_  "ILUsed" ENUM  "No","Yes";
BA_DEF_ BU_  "NodeLayerModules" STRING ;
BA_DEF_ BU_  "VNECUSLHS_VNReq" ENUM  "None","Activator","Remoted","Activator and Remoted","Shared Local";
BA_DEF_ BU_  "VNECUSLHSSharedDiagnostic" ENUM  "None","Activator","Remoted","Activator and Remoted","Shared Local";
BA_DEF_ BU_  "VNECUAllNodes" ENUM  "None","Activator","Remoted","Activator and Remoted","Shared Local";
BA_DEF_ BU_  "ECU_Id" HEX 0 255;
BA_DEF_ BU_  "SourceId" HEX 0 253;
BA_DEF_  "SyncJumpWidthMax" INT 0 255;
BA_DEF_  "SyncJumpWidthMin" INT 0 255;
BA_DEF_  "SamplePointMax" FLOAT 0 100;
BA_DEF_  "SamplePointMin" FLOAT 0 100;
BA_DEF_  "Baudrate" INT 0 1000000;
BA_DEF_  "VehicleArchitecture" STRING ;
BA_DEF_  "VNInitActSLHS_VNReq" ENUM  "No","Yes";
BA_DEF_  "VN_SLHS_VNReq" INT 0 255;
BA_DEF_  "VNInitActSLHSSharedDiagnostic" ENUM  "No","Yes";
BA_DEF_  "VN_SLHSSharedDiagnostic" INT 0 255;
BA_DEF_  "NmMessageCount" INT 0 32;
BA_DEF_  "NmBaseAddress" HEX 0 2032;
BA_DEF_  "NetworkType" STRING ;
BA_DEF_  "VNMFPeriodicInterval" INT 0 65535;
BA_DEF_  "BusWakeUpDelay" INT 0 65535;
BA_DEF_  "BusOffRecoveryTime" INT 0 65535;
BA_DEF_  "NodeStatusMsgID" HEX 0 536870911;
BA_DEF_  "NodeStatusMsgCycleTime" INT 0 65535;
BA_DEF_  "NodeStatusMsgTimeoutTime" INT 0 65535;
BA_DEF_  "UseGMParameterIDs" INT 0 1;
BA_DEF_  "VersionWeek" INT 0 255;
BA_DEF_  "VersionYear" INT 0 255;
BA_DEF_  "VN_AllNodes" INT 0 255;
BA_DEF_  "Manufacturer" ENUM  "DBAG","VAG","BMW","PAG","GM";
BA_DEF_  "NmType" STRING ;
BA_DEF_REL_ BU_SG_REL_  "GenSigSuprvRespComment" STRING ;
BA_DEF_REL_ BU_SG_REL_  "GenSigVBitResp" ENUM  "No","Yes";
BA_DEF_REL_ BU_SG_REL_  "GenSigVBitRespComment" STRING ;
BA_DEF_REL_ BU_SG_REL_  "GenSigVDAFailComment" STRING ;
BA_DEF_REL_ BU_SG_REL_  "GenSigVDAFailResp" ENUM  "No","Yes";
BA_DEF_REL_ BU_SG_REL_  "GenSigRxStartValue" STRING ;
BA_DEF_REL_ BU_SG_REL_  "GenSigSuprvResp" ENUM  "None","Notify App","Substitute Default";
BA_DEF_REL_ BU_SG_REL_  "GenSigTimeoutMsg" HEX -2147483648 268435455;
BA_DEF_REL_ BU_SG_REL_  "GenSigTimeoutTime" INT 0 15000;
BA_DEF_DEF_  "BusType" "";
BA_DEF_DEF_  "VNSigSLHS_VNReq" "No";
BA_DEF_DEF_  "VNSigSLHSSharedDiagnostic" "No";
BA_DEF_DEF_  "SignalType" "";
BA_DEF_DEF_  "PacketOrder" 0;
BA_DEF_DEF_  "SignalLongName" "";
BA_DEF_DEF_  "GenSigStartValue" 0;
BA_DEF_DEF_  "VNSigAllNodes" "No";
BA_DEF_DEF_  "GenSigDeltaValue" 0;
BA_DEF_DEF_  "GenSigSendType" "NoSigSendType";
BA_DEF_DEF_  "GenSigSendOnInit" "Not Initialized";
BA_DEF_DEF_  "AppGenMsgCycleTime" 0;
BA_DEF_DEF_  "GenMsgILSupport" "Yes";
BA_DEF_DEF_  "TpApplType" "";
BA_DEF_DEF_  "Prio" 4;
BA_DEF_DEF_  "MessageSubnet" "FO";
BA_DEF_DEF_  "GenMsgMandatoryToSupervision" "No";
BA_DEF_DEF_  "DiagState" "No";
BA_DEF_DEF_  "GenMsgDelayTime" 0;
BA_DEF_DEF_  "GenMsgCycleTime" 0;
BA_DEF_DEF_  "GenMsgSendType" "spontanX";
BA_DEF_DEF_  "DiagResponse" "No";
BA_DEF_DEF_  "DiagRequest" "No";
BA_DEF_DEF_  "NmMessage" "No";
BA_DEF_DEF_  "MessageManagerUsed" "Yes";
BA_DEF_DEF_  "NmNode" "Yes";
BA_DEF_DEF_  "ILUsed" "Yes";
BA_DEF_DEF_  "NodeLayerModules" "gmlan02.dll";
BA_DEF_DEF_  "VNECUSLHS_VNReq" "None";
BA_DEF_DEF_  "VNECUSLHSSharedDiagnostic" "None";
BA_DEF_DEF_  "VNECUAllNodes" "None";
BA_DEF_DEF_  "ECU_Id" 0;
BA_DEF_DEF_  "SourceId" 0;
BA_DEF_DEF_  "SyncJumpWidthMax" 0;
BA_DEF_DEF_  "SyncJumpWidthMin" 0;
BA_DEF_DEF_  "SamplePointMax" 0;
BA_DEF_DEF_  "SamplePointMin" 0;
BA_DEF_DEF_  "Baudrate" 0;
BA_DEF_DEF_  "VehicleArchitecture" "";
BA_DEF_DEF_  "VNInitActSLHS_VNReq" "No";
BA_DEF_DEF_  "VN_SLHS_VNReq" 2;
BA_DEF_DEF_  "VNInitActSLHSSharedDiagnostic" "No";
BA_DEF_DEF_  "VN_SLHSSharedDiagnostic" 0;
BA_DEF_DEF_  "NmMessageCount" 32;
BA_DEF_DEF_  "NmBaseAddress" 1568;
BA_DEF_DEF_  "NetworkType" "";
BA_DEF_DEF_  "VNMFPeriodicInterval" 3000;
BA_DEF_DEF_  "BusWakeUpDelay" 100;
BA_DEF_DEF_  "BusOffRecoveryTime" 0;
BA_DEF_DEF_  "NodeStatusMsgID" 268427264;
BA_DEF_DEF_  "NodeStatusMsgCycleTime" 1200;
BA_DEF_DEF_  "NodeStatusMsgTimeoutTime" 0;
BA_DEF_DEF_  "UseGMParameterIDs" 1;
BA_DEF_DEF_  "VersionWeek" 0;
BA_DEF_DEF_  "VersionYear" 0;
BA_DEF_DEF_  "VN_AllNodes" 1;
BA_DEF_DEF_  "Manufacturer" "GM";
BA_DEF_DEF_  "NmType" "GMLAN";
BA_DEF_DEF_REL_ "GenSigSuprvRespComment" "";
BA_DEF_DEF_REL_ "GenSigVBitResp" "No";
BA_DEF_DEF_REL_ "GenSigVBitRespComment" "";
BA_DEF_DEF_REL_ "GenSigVDAFailComment" "";
BA_DEF_DEF_REL_ "GenSigVDAFailResp" "No";
BA_DEF_DEF_REL_ "GenSigRxStartValue" "";
BA_DEF_DEF_REL_ "GenSigSuprvResp" "None";
BA_DEF_DEF_REL_ "GenSigTimeoutMsg" 0;
BA_DEF_DEF_REL_ "GenSigTimeoutTime" 0;
BA_ "SyncJumpWidthMax" 4;
BA_ "SyncJumpWidthMin" 3;
BA_ "SamplePointMax" 81.25;
BA_ "SamplePointMin" 80;
BA_ "Baudrate" 500000;
BA_ "VehicleArchitecture" "Global A";
BA_ "VNInitActSLHS_VNReq" 1;
BA_ "VNInitActSLHSSharedDiagnostic" 1;
BA_ "NmMessageCount" 16;
BA_ "NmBaseAddress" 1536;
BA_ "NetworkType" "Powertrain";
BA_ "BusOffRecoveryTime" 160;
BA_ "NodeStatusMsgID" 0;
BA_ "UseGMParameterIDs" 0;
BA_ "VersionWeek" 107;
BA_ "VersionYear" 17;
BA_ "BusType" "CAN";
BA_ "VNECUSLHS_VNReq" BU_ EBOOST_CE 4;
BA_ "VNECUSLHSSharedDiagnostic" BU_ EBOOST_CE 4;
BA_ "VNECUAllNodes" BU_ EBOOST_CE 4;
BA_ "ECU_Id" BU_ EBOOST_CE 20;
BA_ "SourceId" BU_ EBOOST_CE 43;
BA_ "VNECUSLHS_VNReq" BU_ TRCM_CE 4;
BA_ "VNECUSLHSSharedDiagnostic" BU_ TRCM_CE 4;
BA_ "VNECUAllNodes" BU_ TRCM_CE 4;
BA_ "ECU_Id" BU_ TRCM_CE 21;
BA_ "SourceId" BU_ TRCM_CE 28;
BA_ "VNECUSLHS_VNReq" BU_ CGM_CE 4;
BA_ "VNECUSLHSSharedDiagnostic" BU_ CGM_CE 4;
BA_ "VNECUAllNodes" BU_ CGM_CE 4;
BA_ "ECU_Id" BU_ CGM_CE 51;
BA_ "SourceId" BU_ CGM_CE 69;
BA_ "VNECUSLHS_VNReq" BU_ EPS_JR_CE 4;
BA_ "VNECUSLHSSharedDiagnostic" BU_ EPS_JR_CE 4;
BA_ "VNECUAllNodes" BU_ EPS_JR_CE 4;
BA_ "ECU_Id" BU_ EPS_JR_CE 2;
BA_ "SourceId" BU_ EPS_JR_CE 49;
BA_ "VNECUSLHS_VNReq" BU_ MSB1_CE 4;
BA_ "VNECUSLHSSharedDiagnostic" BU_ MSB1_CE 4;
BA_ "VNECUAllNodes" BU_ MSB1_CE 4;
BA_ "ECU_Id" BU_ MSB1_CE 8;
BA_ "SourceId" BU_ MSB1_CE 92;
BA_ "VNECUSLHS_VNReq" BU_ MSB2_CE 4;
BA_ "VNECUSLHSSharedDiagnostic" BU_ MSB2_CE 4;
BA_ "VNECUAllNodes" BU_ MSB2_CE 4;
BA_ "ECU_Id" BU_ MSB2_CE 9;
BA_ "SourceId" BU_ MSB2_CE 94;
BA_ "VNECUSLHS_VNReq" BU_ ARS_CE 4;
BA_ "VNECUSLHSSharedDiagnostic" BU_ ARS_CE 4;
BA_ "VNECUAllNodes" BU_ ARS_CE 4;
BA_ "ECU_Id" BU_ ARS_CE 29;
BA_ "SourceId" BU_ ARS_CE 50;
BA_ "VNECUSLHS_VNReq" BU_ SDM_CE 4;
BA_ "VNECUSLHSSharedDiagnostic" BU_ SDM_CE 4;
BA_ "VNECUAllNodes" BU_ SDM_CE 4;
BA_ "ECU_Id" BU_ SDM_CE 7;
BA_ "SourceId" BU_ SDM_CE 88;
BA_ "VNECUSLHS_VNReq" BU_ EBCM_OBD_CE 4;
BA_ "VNECUSLHSSharedDiagnostic" BU_ EBCM_OBD_CE 4;
BA_ "VNECUAllNodes" BU_ EBCM_OBD_CE 4;
BA_ "ECU_Id" BU_ EBCM_OBD_CE 3;
BA_ "SourceId" BU_ EBCM_OBD_CE 40;
BA_ "VNECUSLHS_VNReq" BU_ HCP_T_CE 4;
BA_ "VNECUSLHSSharedDiagnostic" BU_ HCP_T_CE 4;
BA_ "VNECUAllNodes" BU_ HCP_T_CE 4;
BA_ "ECU_Id" BU_ HCP_T_CE 225;
BA_ "SourceId" BU_ HCP_T_CE 23;
BA_ "VNECUSLHS_VNReq" BU_ LCMS_CE 4;
BA_ "VNECUSLHSSharedDiagnostic" BU_ LCMS_CE 4;
BA_ "VNECUAllNodes" BU_ LCMS_CE 4;
BA_ "ECU_Id" BU_ LCMS_CE 11;
BA_ "SourceId" BU_ LCMS_CE 46;
BA_ "VNECUSLHS_VNReq" BU_ APA_CE 4;
BA_ "VNECUSLHSSharedDiagnostic" BU_ APA_CE 4;
BA_ "VNECUAllNodes" BU_ APA_CE 4;
BA_ "ECU_Id" BU_ APA_CE 89;
BA_ "SourceId" BU_ APA_CE 187;
BA_ "VNECUSLHS_VNReq" BU_ HCP_CE 4;
BA_ "VNECUSLHSSharedDiagnostic" BU_ HCP_CE 4;
BA_ "VNECUAllNodes" BU_ HCP_CE 4;
BA_ "ECU_Id" BU_ HCP_CE 225;
BA_ "SourceId" BU_ HCP_CE 23;
BA_ "VNECUSLHS_VNReq" BU_ EOCM_F_CE 4;
BA_ "VNECUSLHSSharedDiagnostic" BU_ EOCM_F_CE 4;
BA_ "VNECUAllNodes" BU_ EOCM_F_CE 4;
BA_ "ECU_Id" BU_ EOCM_F_CE 75;
BA_ "SourceId" BU_ EOCM_F_CE 108;
BA_ "VNECUSLHS_VNReq" BU_ MCP_C_CE 4;
BA_ "VNECUSLHSSharedDiagnostic" BU_ MCP_C_CE 4;
BA_ "VNECUAllNodes" BU_ MCP_C_CE 4;
BA_ "ECU_Id" BU_ MCP_C_CE 26;
BA_ "SourceId" BU_ MCP_C_CE 31;
BA_ "VNECUSLHS_VNReq" BU_ MCP_B_CE 4;
BA_ "VNECUSLHSSharedDiagnostic" BU_ MCP_B_CE 4;
BA_ "VNECUAllNodes" BU_ MCP_B_CE 4;
BA_ "ECU_Id" BU_ MCP_B_CE 24;
BA_ "SourceId" BU_ MCP_B_CE 30;
BA_ "VNECUSLHS_VNReq" BU_ MCP_A_CE 4;
BA_ "VNECUSLHSSharedDiagnostic" BU_ MCP_A_CE 4;
BA_ "VNECUAllNodes" BU_ MCP_A_CE 4;
BA_ "ECU_Id" BU_ MCP_A_CE 23;
BA_ "SourceId" BU_ MCP_A_CE 29;
BA_ "VNECUSLHS_VNReq" BU_ FCM_CE 4;
BA_ "VNECUSLHSSharedDiagnostic" BU_ FCM_CE 4;
BA_ "VNECUAllNodes" BU_ FCM_CE 4;
BA_ "ECU_Id" BU_ FCM_CE 11;
BA_ "SourceId" BU_ FCM_CE 188;
BA_ "VNECUSLHS_VNReq" BU_ ICCM_CE 4;
BA_ "VNECUSLHSSharedDiagnostic" BU_ ICCM_CE 4;
BA_ "VNECUAllNodes" BU_ ICCM_CE 4;
BA_ "ECU_Id" BU_ ICCM_CE 28;
BA_ "SourceId" BU_ ICCM_CE 34;
BA_ "VNECUAllNodes" BU_ Dummy_CE 4;
BA_ "VNECUSLHS_VNReq" BU_ TestTool_CE 4;
BA_ "VNECUSLHSSharedDiagnostic" BU_ TestTool_CE 4;
BA_ "VNECUAllNodes" BU_ TestTool_CE 4;
BA_ "SourceId" BU_ TestTool_CE 253;
BA_ "VNECUSLHS_VNReq" BU_ ACC_CE 4;
BA_ "VNECUSLHSSharedDiagnostic" BU_ ACC_CE 4;
BA_ "VNECUAllNodes" BU_ ACC_CE 4;
BA_ "ECU_Id" BU_ ACC_CE 27;
BA_ "SourceId" BU_ ACC_CE 33;
BA_ "VNECUSLHS_VNReq" BU_ RDCM_CE 4;
BA_ "VNECUSLHSSharedDiagnostic" BU_ RDCM_CE 4;
BA_ "VNECUAllNodes" BU_ RDCM_CE 4;
BA_ "ECU_Id" BU_ RDCM_CE 15;
BA_ "SourceId" BU_ RDCM_CE 27;
BA_ "VNECUSLHS_VNReq" BU_ EBCM_CE 4;
BA_ "VNECUSLHSSharedDiagnostic" BU_ EBCM_CE 4;
BA_ "VNECUAllNodes" BU_ EBCM_CE 4;
BA_ "ECU_Id" BU_ EBCM_CE 3;
BA_ "SourceId" BU_ EBCM_CE 40;
BA_ "VNECUSLHS_VNReq" BU_ SADS_CE 4;
BA_ "VNECUSLHSSharedDiagnostic" BU_ SADS_CE 4;
BA_ "VNECUAllNodes" BU_ SADS_CE 4;
BA_ "ECU_Id" BU_ SADS_CE 14;
BA_ "SourceId" BU_ SADS_CE 56;
BA_ "VNECUSLHS_VNReq" BU_ IMU_CE 4;
BA_ "VNECUSLHSSharedDiagnostic" BU_ IMU_CE 4;
BA_ "VNECUAllNodes" BU_ IMU_CE 4;
BA_ "ECU_Id" BU_ IMU_CE 10;
BA_ "SourceId" BU_ IMU_CE 44;
BA_ "VNECUSLHS_VNReq" BU_ SAS_CE 4;
BA_ "VNECUSLHSSharedDiagnostic" BU_ SAS_CE 4;
BA_ "VNECUAllNodes" BU_ SAS_CE 4;
BA_ "ECU_Id" BU_ SAS_CE 23;
BA_ "SourceId" BU_ SAS_CE 52;
BA_ "VNECUSLHS_VNReq" BU_ EPS_CE 4;
BA_ "VNECUSLHSSharedDiagnostic" BU_ EPS_CE 4;
BA_ "VNECUAllNodes" BU_ EPS_CE 4;
BA_ "ECU_Id" BU_ EPS_CE 2;
BA_ "SourceId" BU_ EPS_CE 49;
BA_ "Prio" BO_ 516 0;
BA_ "MessageSubnet" BO_ 516 3;
BA_ "GenMsgCycleTime" BO_ 516 1000;
BA_ "GenMsgSendType" BO_ 516 0;
BA_ "Prio" BO_ 514 0;
BA_ "MessageSubnet" BO_ 514 3;
BA_ "GenMsgCycleTime" BO_ 514 100;
BA_ "GenMsgSendType" BO_ 514 0;
BA_ "Prio" BO_ 521 0;
BA_ "MessageSubnet" BO_ 521 3;
BA_ "GenMsgCycleTime" BO_ 521 25;
BA_ "GenMsgSendType" BO_ 521 0;
BA_ "Prio" BO_ 519 0;
BA_ "MessageSubnet" BO_ 519 3;
BA_ "GenMsgCycleTime" BO_ 519 25;
BA_ "GenMsgSendType" BO_ 519 0;
BA_ "Prio" BO_ 543 0;
BA_ "MessageSubnet" BO_ 543 3;
BA_ "GenMsgCycleTime" BO_ 543 100;
BA_ "GenMsgSendType" BO_ 543 0;
BA_ "Prio" BO_ 1931 0;
BA_ "MessageSubnet" BO_ 1931 3;
BA_ "GenMsgCycleTime" BO_ 1931 1000;
BA_ "GenMsgSendType" BO_ 1931 0;
BA_ "Prio" BO_ 1923 0;
BA_ "MessageSubnet" BO_ 1923 3;
BA_ "GenMsgCycleTime" BO_ 1923 1000;
BA_ "GenMsgSendType" BO_ 1923 0;
BA_ "Prio" BO_ 1922 0;
BA_ "MessageSubnet" BO_ 1922 3;
BA_ "GenMsgCycleTime" BO_ 1922 1000;
BA_ "GenMsgSendType" BO_ 1922 0;
BA_ "Prio" BO_ 1921 0;
BA_ "MessageSubnet" BO_ 1921 3;
BA_ "GenMsgCycleTime" BO_ 1921 1000;
BA_ "GenMsgSendType" BO_ 1921 0;
BA_ "Prio" BO_ 2034 0;
BA_ "MessageSubnet" BO_ 2034 3;
BA_ "DiagResponse" BO_ 2034 1;
BA_ "Prio" BO_ 2032 0;
BA_ "MessageSubnet" BO_ 2032 3;
BA_ "DiagRequest" BO_ 2032 1;
BA_ "Prio" BO_ 201 0;
BA_ "MessageSubnet" BO_ 201 3;
BA_ "GenMsgCycleTime" BO_ 201 12;
BA_ "GenMsgSendType" BO_ 201 0;
BA_ "Prio" BO_ 1300 0;
BA_ "MessageSubnet" BO_ 1300 3;
BA_ "GenMsgCycleTime" BO_ 1300 1000;
BA_ "GenMsgSendType" BO_ 1300 0;
BA_ "Prio" BO_ 1249 0;
BA_ "MessageSubnet" BO_ 1249 3;
BA_ "GenMsgCycleTime" BO_ 1249 1000;
BA_ "GenMsgSendType" BO_ 1249 0;
BA_ "Prio" BO_ 300 0;
BA_ "MessageSubnet" BO_ 300 3;
BA_ "GenMsgCycleTime" BO_ 300 100;
BA_ "GenMsgSendType" BO_ 300 0;
BA_ "Prio" BO_ 501 0;
BA_ "MessageSubnet" BO_ 501 3;
BA_ "GenMsgCycleTime" BO_ 501 100;
BA_ "GenMsgSendType" BO_ 501 0;
BA_ "Prio" BO_ 1920 0;
BA_ "MessageSubnet" BO_ 1920 3;
BA_ "GenMsgCycleTime" BO_ 1920 1000;
BA_ "GenMsgSendType" BO_ 1920 0;
BA_ "Prio" BO_ 381 0;
BA_ "MessageSubnet" BO_ 381 3;
BA_ "GenMsgCycleTime" BO_ 381 100;
BA_ "GenMsgSendType" BO_ 381 0;
BA_ "Prio" BO_ 386 0;
BA_ "MessageSubnet" BO_ 386 3;
BA_ "GenMsgCycleTime" BO_ 386 100;
BA_ "GenMsgSendType" BO_ 386 0;
BA_ "Prio" BO_ 842 0;
BA_ "MessageSubnet" BO_ 842 3;
BA_ "GenMsgCycleTime" BO_ 842 50;
BA_ "GenMsgSendType" BO_ 842 0;
BA_ "Prio" BO_ 840 0;
BA_ "MessageSubnet" BO_ 840 3;
BA_ "GenMsgCycleTime" BO_ 840 50;
BA_ "GenMsgSendType" BO_ 840 0;
BA_ "Prio" BO_ 489 0;
BA_ "MessageSubnet" BO_ 489 3;
BA_ "GenMsgCycleTime" BO_ 489 20;
BA_ "GenMsgSendType" BO_ 489 0;
BA_ "Prio" BO_ 485 0;
BA_ "MessageSubnet" BO_ 485 3;
BA_ "GenMsgCycleTime" BO_ 485 10;
BA_ "GenMsgSendType" BO_ 485 0;
BA_ "Prio" BO_ 803 0;
BA_ "MessageSubnet" BO_ 803 3;
BA_ "GenMsgCycleTime" BO_ 803 10;
BA_ "GenMsgSendType" BO_ 803 0;
BA_ "Prio" BO_ 871 0;
BA_ "MessageSubnet" BO_ 871 3;
BA_ "GenMsgCycleTime" BO_ 871 100;
BA_ "GenMsgSendType" BO_ 871 0;
BA_ "Prio" BO_ 873 0;
BA_ "MessageSubnet" BO_ 873 3;
BA_ "GenMsgCycleTime" BO_ 873 100;
BA_ "GenMsgSendType" BO_ 873 0;
BA_ "Prio" BO_ 568 0;
BA_ "MessageSubnet" BO_ 568 3;
BA_ "GenMsgCycleTime" BO_ 568 100;
BA_ "GenMsgSendType" BO_ 568 0;
BA_ "Prio" BO_ 542 0;
BA_ "MessageSubnet" BO_ 542 3;
BA_ "GenMsgCycleTime" BO_ 542 20;
BA_ "GenMsgSendType" BO_ 542 0;
BA_ "Prio" BO_ 539 0;
BA_ "MessageSubnet" BO_ 539 3;
BA_ "GenMsgCycleTime" BO_ 539 10;
BA_ "GenMsgSendType" BO_ 539 0;
BA_ "Prio" BO_ 537 0;
BA_ "MessageSubnet" BO_ 537 3;
BA_ "GenMsgCycleTime" BO_ 537 20;
BA_ "GenMsgSendType" BO_ 537 0;
BA_ "PacketOrder" SG_ 516 RCMCII_DataVal 3;
BA_ "SignalType" SG_ 516 RCMCII_DataVal "UNM";
BA_ "SignalLongName" SG_ 516 RCMCII_DataVal "Range Control Module Calibration Identification Information : Data Value";
BA_ "VNSigAllNodes" SG_ 516 RCMCII_DataVal 1;
BA_ "PacketOrder" SG_ 516 RCMCII_DataIndx 2;
BA_ "SignalType" SG_ 516 RCMCII_DataIndx "ENM";
BA_ "SignalLongName" SG_ 516 RCMCII_DataIndx "Range Control Module Calibration Identification Information : Data Index";
BA_ "VNSigAllNodes" SG_ 516 RCMCII_DataIndx 1;
BA_ "PacketOrder" SG_ 516 RCMCII_DataStat 1;
BA_ "SignalType" SG_ 516 RCMCII_DataStat "ENM";
BA_ "SignalLongName" SG_ 516 RCMCII_DataStat "Range Control Module Calibration Identification Information : Data Status";
BA_ "VNSigAllNodes" SG_ 516 RCMCII_DataStat 1;
BA_ "PacketOrder" SG_ 514 RCMDSB_DTCStat 2;
BA_ "SignalType" SG_ 514 RCMDSB_DTCStat "ENM";
BA_ "SignalLongName" SG_ 514 RCMDSB_DTCStat "Range Control Module Diagnostic Status B : Diagnostic Trouble Code Status";
BA_ "VNSigAllNodes" SG_ 514 RCMDSB_DTCStat 1;
BA_ "PacketOrder" SG_ 514 RCMDSB_DTCIndx 1;
BA_ "SignalType" SG_ 514 RCMDSB_DTCIndx "UNM";
BA_ "SignalLongName" SG_ 514 RCMDSB_DTCIndx "Range Control Module Diagnostic Status B : Diagnostic Trouble Code Index";
BA_ "VNSigAllNodes" SG_ 514 RCMDSB_DTCIndx 1;
BA_ "PacketOrder" SG_ 514 RCMDSA_DTCStat 2;
BA_ "SignalType" SG_ 514 RCMDSA_DTCStat "ENM";
BA_ "SignalLongName" SG_ 514 RCMDSA_DTCStat "Range Control Module Diagnostic Status A : Diagnostic Trouble Code Status";
BA_ "VNSigAllNodes" SG_ 514 RCMDSA_DTCStat 1;
BA_ "PacketOrder" SG_ 514 RCMDSA_DTCIndx 1;
BA_ "SignalType" SG_ 514 RCMDSA_DTCIndx "UNM";
BA_ "SignalLongName" SG_ 514 RCMDSA_DTCIndx "Range Control Module Diagnostic Status A : Diagnostic Trouble Code Index";
BA_ "VNSigAllNodes" SG_ 514 RCMDSA_DTCIndx 1;
BA_ "SignalType" SG_ 521 RngMtrStatProtVal "UNM";
BA_ "SignalLongName" SG_ 521 RngMtrStatProtVal "Range Motor Status Protection Value";
BA_ "VNSigAllNodes" SG_ 521 RngMtrStatProtVal 1;
BA_ "SignalType" SG_ 521 RngMtrStatARC "UNM";
BA_ "SignalLongName" SG_ 521 RngMtrStatARC "Range Motor Status Alive Rolling Count";
BA_ "VNSigAllNodes" SG_ 521 RngMtrStatARC 1;
BA_ "PacketOrder" SG_ 521 RMS_RngMtrDfltStat 4;
BA_ "SignalType" SG_ 521 RMS_RngMtrDfltStat "ENM";
BA_ "SignalLongName" SG_ 521 RMS_RngMtrDfltStat "Range Motor Status : Range Motor Default Status";
BA_ "VNSigAllNodes" SG_ 521 RMS_RngMtrDfltStat 1;
BA_ "PacketOrder" SG_ 521 RMS_RngMtrPstnV 3;
BA_ "SignalType" SG_ 521 RMS_RngMtrPstnV "ENM";
BA_ "SignalLongName" SG_ 521 RMS_RngMtrPstnV "Range Motor Status : Range Motor Position Validity";
BA_ "VNSigAllNodes" SG_ 521 RMS_RngMtrPstnV 1;
BA_ "PacketOrder" SG_ 521 RMS_RngMtrPstnM 2;
BA_ "SignalType" SG_ 521 RMS_RngMtrPstnM "ENM";
BA_ "SignalLongName" SG_ 521 RMS_RngMtrPstnM "Range Motor Status : Range Motor Position Mask";
BA_ "VNSigAllNodes" SG_ 521 RMS_RngMtrPstnM 1;
BA_ "PacketOrder" SG_ 521 RMS_RngMtrPstn 1;
BA_ "SignalType" SG_ 521 RMS_RngMtrPstn "ENM";
BA_ "SignalLongName" SG_ 521 RMS_RngMtrPstn "Range Motor Status : Range Motor Position";
BA_ "VNSigAllNodes" SG_ 521 RMS_RngMtrPstn 1;
BA_ "SignalType" SG_ 519 ClrRngCntMdlLgsDgInf "BLN";
BA_ "SignalLongName" SG_ 519 ClrRngCntMdlLgsDgInf "Clear Range Control Module Legislated Diagnostic Information";
BA_ "VNSigAllNodes" SG_ 519 ClrRngCntMdlLgsDgInf 1;
BA_ "SignalType" SG_ 519 ElcSftActnRngCmdPVal "UNM";
BA_ "SignalLongName" SG_ 519 ElcSftActnRngCmdPVal "Electronic Shift Actuation Range Command Protection Value";
BA_ "VNSigAllNodes" SG_ 519 ElcSftActnRngCmdPVal 1;
BA_ "SignalType" SG_ 519 ElcShftActnRngCmdARC "UNM";
BA_ "SignalLongName" SG_ 519 ElcShftActnRngCmdARC "Electronic Shift Actuation Range Command Alive Rolling Count";
BA_ "VNSigAllNodes" SG_ 519 ElcShftActnRngCmdARC 1;
BA_ "SignalType" SG_ 519 ElcShftActnRngCmd "ENM";
BA_ "SignalLongName" SG_ 519 ElcShftActnRngCmd "Electronic Shift Actuation Range Command";
BA_ "VNSigAllNodes" SG_ 519 ElcShftActnRngCmd 1;
BA_ "SignalType" SG_ 1931 DTCI_CodeSupported_78B "BLN";
BA_ "PacketOrder" SG_ 1931 DTCI_CodeSupported_78B 19;
BA_ "SignalLongName" SG_ 1931 DTCI_CodeSupported_78B "Diagnostic Trouble Code Information Extended 78B : Code Supported";
BA_ "VNSigAllNodes" SG_ 1931 DTCI_CodeSupported_78B 1;
BA_ "SignalType" SG_ 1931 DTCI_CurrentStatus_78B "BLN";
BA_ "PacketOrder" SG_ 1931 DTCI_CurrentStatus_78B 18;
BA_ "SignalLongName" SG_ 1931 DTCI_CurrentStatus_78B "Diagnostic Trouble Code Information Extended 78B : Current Status";
BA_ "VNSigAllNodes" SG_ 1931 DTCI_CurrentStatus_78B 1;
BA_ "SignalType" SG_ 1931 DTCI_DTCFailType_78B "UNM";
BA_ "PacketOrder" SG_ 1931 DTCI_DTCFailType_78B 11;
BA_ "SignalLongName" SG_ 1931 DTCI_DTCFailType_78B "Diagnostic Trouble Code Information Extended 78B : Diagnostic Trouble Code Failure Type";
BA_ "VNSigAllNodes" SG_ 1931 DTCI_DTCFailType_78B 1;
BA_ "SignalType" SG_ 1931 DTCI_DTCFaultType_78B "ENM";
BA_ "PacketOrder" SG_ 1931 DTCI_DTCFaultType_78B 20;
BA_ "SignalLongName" SG_ 1931 DTCI_DTCFaultType_78B "Diagnostic Trouble Code Information Extended 78B : Diagnostic Trouble Code Fault Type";
BA_ "VNSigAllNodes" SG_ 1931 DTCI_DTCFaultType_78B 1;
BA_ "SignalType" SG_ 1931 DTCI_DTCNumber_78B "UNM";
BA_ "PacketOrder" SG_ 1931 DTCI_DTCNumber_78B 10;
BA_ "SignalLongName" SG_ 1931 DTCI_DTCNumber_78B "Diagnostic Trouble Code Information Extended 78B : Diagnostic Trouble Code Number";
BA_ "VNSigAllNodes" SG_ 1931 DTCI_DTCNumber_78B 1;
BA_ "SignalType" SG_ 1931 DTCI_DTCSource_78B "UNM";
BA_ "PacketOrder" SG_ 1931 DTCI_DTCSource_78B 9;
BA_ "SignalLongName" SG_ 1931 DTCI_DTCSource_78B "Diagnostic Trouble Code Information Extended 78B : Diagnostic Trouble Code Source";
BA_ "VNSigAllNodes" SG_ 1931 DTCI_DTCSource_78B 1;
BA_ "SignalType" SG_ 1931 DTCI_DTCTriggered_78B "BLN";
BA_ "PacketOrder" SG_ 1931 DTCI_DTCTriggered_78B 8;
BA_ "SignalLongName" SG_ 1931 DTCI_DTCTriggered_78B "Diagnostic Trouble Code Information Extended 78B : Diagnostic Trouble Code Triggered";
BA_ "VNSigAllNodes" SG_ 1931 DTCI_DTCTriggered_78B 1;
BA_ "SignalType" SG_ 1931 DTCI_HistStat_78B "BLN";
BA_ "PacketOrder" SG_ 1931 DTCI_HistStat_78B 15;
BA_ "SignalLongName" SG_ 1931 DTCI_HistStat_78B "Diagnostic Trouble Code Information Extended 78B : History Status";
BA_ "VNSigAllNodes" SG_ 1931 DTCI_HistStat_78B 1;
BA_ "SignalType" SG_ 1931 DTCI_TstFldCdClrdStat_78B "BLN";
BA_ "PacketOrder" SG_ 1931 DTCI_TstFldCdClrdStat_78B 16;
BA_ "SignalLongName" SG_ 1931 DTCI_TstFldCdClrdStat_78B "Diagnostic Trouble Code Information Extended 78B : Test Failed Since Code Cleared Status";
BA_ "VNSigAllNodes" SG_ 1931 DTCI_TstFldCdClrdStat_78B 1;
BA_ "SignalType" SG_ 1931 DTCI_TstFldPwrUpSt_78B "BLN";
BA_ "PacketOrder" SG_ 1931 DTCI_TstFldPwrUpSt_78B 13;
BA_ "SignalLongName" SG_ 1931 DTCI_TstFldPwrUpSt_78B "Diagnostic Trouble Code Information Extended 78B : Test Failed Since Power Up Status";
BA_ "VNSigAllNodes" SG_ 1931 DTCI_TstFldPwrUpSt_78B 1;
BA_ "SignalType" SG_ 1931 DTCI_TstNPsdCdClrdSt_78B "BLN";
BA_ "PacketOrder" SG_ 1931 DTCI_TstNPsdCdClrdSt_78B 17;
BA_ "SignalLongName" SG_ 1931 DTCI_TstNPsdCdClrdSt_78B "Diagnostic Trouble Code Information Extended 78B : Test Not Passed Since Code Cleared Status";
BA_ "VNSigAllNodes" SG_ 1931 DTCI_TstNPsdCdClrdSt_78B 1;
BA_ "SignalType" SG_ 1931 DTCI_TstNPsdPwrUpSt_78B "BLN";
BA_ "PacketOrder" SG_ 1931 DTCI_TstNPsdPwrUpSt_78B 14;
BA_ "SignalLongName" SG_ 1931 DTCI_TstNPsdPwrUpSt_78B "Diagnostic Trouble Code Information Extended 78B : Test Not Passed Since Power Up Status";
BA_ "VNSigAllNodes" SG_ 1931 DTCI_TstNPsdPwrUpSt_78B 1;
BA_ "SignalType" SG_ 1931 DTCIUnused1_78B "BLN";
BA_ "PacketOrder" SG_ 1931 DTCIUnused1_78B 1;
BA_ "SignalLongName" SG_ 1931 DTCIUnused1_78B "Diagnostic Trouble Code Information Extended 78B : Unused 1";
BA_ "VNSigAllNodes" SG_ 1931 DTCIUnused1_78B 1;
BA_ "SignalType" SG_ 1931 DTCIUnused2_78B "BLN";
BA_ "PacketOrder" SG_ 1931 DTCIUnused2_78B 2;
BA_ "SignalLongName" SG_ 1931 DTCIUnused2_78B "Diagnostic Trouble Code Information Extended 78B : Unused 2";
BA_ "VNSigAllNodes" SG_ 1931 DTCIUnused2_78B 1;
BA_ "SignalType" SG_ 1931 DTCIUnused3_78B "BLN";
BA_ "PacketOrder" SG_ 1931 DTCIUnused3_78B 3;
BA_ "SignalLongName" SG_ 1931 DTCIUnused3_78B "Diagnostic Trouble Code Information Extended 78B : Unused 3";
BA_ "VNSigAllNodes" SG_ 1931 DTCIUnused3_78B 1;
BA_ "SignalType" SG_ 1931 DTCIUnused4_78B "BLN";
BA_ "PacketOrder" SG_ 1931 DTCIUnused4_78B 4;
BA_ "SignalLongName" SG_ 1931 DTCIUnused4_78B "Diagnostic Trouble Code Information Extended 78B : Unused 4";
BA_ "VNSigAllNodes" SG_ 1931 DTCIUnused4_78B 1;
BA_ "SignalType" SG_ 1931 DTCIUnused5_78B "BLN";
BA_ "PacketOrder" SG_ 1931 DTCIUnused5_78B 5;
BA_ "SignalLongName" SG_ 1931 DTCIUnused5_78B "Diagnostic Trouble Code Information Extended 78B : Unused 5";
BA_ "VNSigAllNodes" SG_ 1931 DTCIUnused5_78B 1;
BA_ "SignalType" SG_ 1931 DTCIUnused6_78B "BLN";
BA_ "PacketOrder" SG_ 1931 DTCIUnused6_78B 6;
BA_ "SignalLongName" SG_ 1931 DTCIUnused6_78B "Diagnostic Trouble Code Information Extended 78B : Unused 6";
BA_ "VNSigAllNodes" SG_ 1931 DTCIUnused6_78B 1;
BA_ "SignalType" SG_ 1931 DTCIUnused7_78B "BLN";
BA_ "PacketOrder" SG_ 1931 DTCIUnused7_78B 7;
BA_ "SignalLongName" SG_ 1931 DTCIUnused7_78B "Diagnostic Trouble Code Information Extended 78B : Unused 7";
BA_ "VNSigAllNodes" SG_ 1931 DTCIUnused7_78B 1;
BA_ "SignalType" SG_ 1931 DTCI_WrnIndRqdSt_78B "BLN";
BA_ "PacketOrder" SG_ 1931 DTCI_WrnIndRqdSt_78B 12;
BA_ "SignalLongName" SG_ 1931 DTCI_WrnIndRqdSt_78B "Diagnostic Trouble Code Information Extended 78B : Warning Indicator Requested Status";
BA_ "VNSigAllNodes" SG_ 1931 DTCI_WrnIndRqdSt_78B 1;
BA_ "SignalType" SG_ 1923 DTCI_WrnIndRqdSt_783 "BLN";
BA_ "PacketOrder" SG_ 1923 DTCI_WrnIndRqdSt_783 12;
BA_ "SignalLongName" SG_ 1923 DTCI_WrnIndRqdSt_783 "Diagnostic Trouble Code Information Extended 783 : Warning Indicator Requested Status";
BA_ "VNSigAllNodes" SG_ 1923 DTCI_WrnIndRqdSt_783 1;
BA_ "SignalType" SG_ 1923 DTCI_TstNPsdPwrUpSt_783 "BLN";
BA_ "PacketOrder" SG_ 1923 DTCI_TstNPsdPwrUpSt_783 14;
BA_ "SignalLongName" SG_ 1923 DTCI_TstNPsdPwrUpSt_783 "Diagnostic Trouble Code Information Extended 783 : Test Not Passed Since Power Up Status";
BA_ "VNSigAllNodes" SG_ 1923 DTCI_TstNPsdPwrUpSt_783 1;
BA_ "SignalType" SG_ 1923 DTCI_TstNPsdCdClrdSt_783 "BLN";
BA_ "PacketOrder" SG_ 1923 DTCI_TstNPsdCdClrdSt_783 17;
BA_ "SignalLongName" SG_ 1923 DTCI_TstNPsdCdClrdSt_783 "Diagnostic Trouble Code Information Extended 783 : Test Not Passed Since Code Cleared Status";
BA_ "VNSigAllNodes" SG_ 1923 DTCI_TstNPsdCdClrdSt_783 1;
BA_ "SignalType" SG_ 1923 DTCI_TstFldPwrUpSt_783 "BLN";
BA_ "PacketOrder" SG_ 1923 DTCI_TstFldPwrUpSt_783 13;
BA_ "SignalLongName" SG_ 1923 DTCI_TstFldPwrUpSt_783 "Diagnostic Trouble Code Information Extended 783 : Test Failed Since Power Up Status";
BA_ "VNSigAllNodes" SG_ 1923 DTCI_TstFldPwrUpSt_783 1;
BA_ "SignalType" SG_ 1923 DTCI_TstFldCdClrdStat_783 "BLN";
BA_ "PacketOrder" SG_ 1923 DTCI_TstFldCdClrdStat_783 16;
BA_ "SignalLongName" SG_ 1923 DTCI_TstFldCdClrdStat_783 "Diagnostic Trouble Code Information Extended 783 : Test Failed Since Code Cleared Status";
BA_ "VNSigAllNodes" SG_ 1923 DTCI_TstFldCdClrdStat_783 1;
BA_ "SignalType" SG_ 1923 DTCI_HistStat_783 "BLN";
BA_ "PacketOrder" SG_ 1923 DTCI_HistStat_783 15;
BA_ "SignalLongName" SG_ 1923 DTCI_HistStat_783 "Diagnostic Trouble Code Information Extended 783 : History Status";
BA_ "VNSigAllNodes" SG_ 1923 DTCI_HistStat_783 1;
BA_ "SignalType" SG_ 1923 DTCI_DTCTriggered_783 "BLN";
BA_ "PacketOrder" SG_ 1923 DTCI_DTCTriggered_783 8;
BA_ "SignalLongName" SG_ 1923 DTCI_DTCTriggered_783 "Diagnostic Trouble Code Information Extended 783 : Diagnostic Trouble Code Triggered";
BA_ "VNSigAllNodes" SG_ 1923 DTCI_DTCTriggered_783 1;
BA_ "SignalType" SG_ 1923 DTCI_DTCSource_783 "UNM";
BA_ "PacketOrder" SG_ 1923 DTCI_DTCSource_783 9;
BA_ "SignalLongName" SG_ 1923 DTCI_DTCSource_783 "Diagnostic Trouble Code Information Extended 783 : Diagnostic Trouble Code Source";
BA_ "VNSigAllNodes" SG_ 1923 DTCI_DTCSource_783 1;
BA_ "SignalType" SG_ 1923 DTCI_DTCNumber_783 "UNM";
BA_ "PacketOrder" SG_ 1923 DTCI_DTCNumber_783 10;
BA_ "SignalLongName" SG_ 1923 DTCI_DTCNumber_783 "Diagnostic Trouble Code Information Extended 783 : Diagnostic Trouble Code Number";
BA_ "VNSigAllNodes" SG_ 1923 DTCI_DTCNumber_783 1;
BA_ "SignalType" SG_ 1923 DTCI_DTCFaultType_783 "ENM";
BA_ "PacketOrder" SG_ 1923 DTCI_DTCFaultType_783 20;
BA_ "SignalLongName" SG_ 1923 DTCI_DTCFaultType_783 "Diagnostic Trouble Code Information Extended 783 : Diagnostic Trouble Code Fault Type";
BA_ "VNSigAllNodes" SG_ 1923 DTCI_DTCFaultType_783 1;
BA_ "SignalType" SG_ 1923 DTCI_DTCFailType_783 "UNM";
BA_ "PacketOrder" SG_ 1923 DTCI_DTCFailType_783 11;
BA_ "SignalLongName" SG_ 1923 DTCI_DTCFailType_783 "Diagnostic Trouble Code Information Extended 783 : Diagnostic Trouble Code Failure Type";
BA_ "VNSigAllNodes" SG_ 1923 DTCI_DTCFailType_783 1;
BA_ "SignalType" SG_ 1923 DTCI_CurrentStatus_783 "BLN";
BA_ "PacketOrder" SG_ 1923 DTCI_CurrentStatus_783 18;
BA_ "SignalLongName" SG_ 1923 DTCI_CurrentStatus_783 "Diagnostic Trouble Code Information Extended 783 : Current Status";
BA_ "VNSigAllNodes" SG_ 1923 DTCI_CurrentStatus_783 1;
BA_ "SignalType" SG_ 1923 DTCI_CodeSupported_783 "BLN";
BA_ "PacketOrder" SG_ 1923 DTCI_CodeSupported_783 19;
BA_ "SignalLongName" SG_ 1923 DTCI_CodeSupported_783 "Diagnostic Trouble Code Information Extended 783 : Code Supported";
BA_ "VNSigAllNodes" SG_ 1923 DTCI_CodeSupported_783 1;
BA_ "SignalType" SG_ 1923 DTCIUnused7_783 "BLN";
BA_ "PacketOrder" SG_ 1923 DTCIUnused7_783 7;
BA_ "SignalLongName" SG_ 1923 DTCIUnused7_783 "Diagnostic Trouble Code Information Extended 783 : Unused 7";
BA_ "VNSigAllNodes" SG_ 1923 DTCIUnused7_783 1;
BA_ "SignalType" SG_ 1923 DTCIUnused6_783 "BLN";
BA_ "PacketOrder" SG_ 1923 DTCIUnused6_783 6;
BA_ "SignalLongName" SG_ 1923 DTCIUnused6_783 "Diagnostic Trouble Code Information Extended 783 : Unused 6";
BA_ "VNSigAllNodes" SG_ 1923 DTCIUnused6_783 1;
BA_ "SignalType" SG_ 1923 DTCIUnused5_783 "BLN";
BA_ "PacketOrder" SG_ 1923 DTCIUnused5_783 5;
BA_ "SignalLongName" SG_ 1923 DTCIUnused5_783 "Diagnostic Trouble Code Information Extended 783 : Unused 5";
BA_ "VNSigAllNodes" SG_ 1923 DTCIUnused5_783 1;
BA_ "SignalType" SG_ 1923 DTCIUnused4_783 "BLN";
BA_ "PacketOrder" SG_ 1923 DTCIUnused4_783 4;
BA_ "SignalLongName" SG_ 1923 DTCIUnused4_783 "Diagnostic Trouble Code Information Extended 783 : Unused 4";
BA_ "VNSigAllNodes" SG_ 1923 DTCIUnused4_783 1;
BA_ "SignalType" SG_ 1923 DTCIUnused3_783 "BLN";
BA_ "PacketOrder" SG_ 1923 DTCIUnused3_783 3;
BA_ "SignalLongName" SG_ 1923 DTCIUnused3_783 "Diagnostic Trouble Code Information Extended 783 : Unused 3";
BA_ "VNSigAllNodes" SG_ 1923 DTCIUnused3_783 1;
BA_ "SignalType" SG_ 1923 DTCIUnused2_783 "BLN";
BA_ "PacketOrder" SG_ 1923 DTCIUnused2_783 2;
BA_ "SignalLongName" SG_ 1923 DTCIUnused2_783 "Diagnostic Trouble Code Information Extended 783 : Unused 2";
BA_ "VNSigAllNodes" SG_ 1923 DTCIUnused2_783 1;
BA_ "SignalType" SG_ 1923 DTCIUnused1_783 "BLN";
BA_ "PacketOrder" SG_ 1923 DTCIUnused1_783 1;
BA_ "SignalLongName" SG_ 1923 DTCIUnused1_783 "Diagnostic Trouble Code Information Extended 783 : Unused 1";
BA_ "VNSigAllNodes" SG_ 1923 DTCIUnused1_783 1;
BA_ "SignalType" SG_ 1922 DTCI_WrnIndRqdSt_782 "BLN";
BA_ "PacketOrder" SG_ 1922 DTCI_WrnIndRqdSt_782 12;
BA_ "SignalLongName" SG_ 1922 DTCI_WrnIndRqdSt_782 "Diagnostic Trouble Code Information Extended 782 : Warning Indicator Requested Status";
BA_ "VNSigAllNodes" SG_ 1922 DTCI_WrnIndRqdSt_782 1;
BA_ "SignalType" SG_ 1922 DTCIUnused7_782 "BLN";
BA_ "PacketOrder" SG_ 1922 DTCIUnused7_782 7;
BA_ "SignalLongName" SG_ 1922 DTCIUnused7_782 "Diagnostic Trouble Code Information Extended 782 : Unused 7";
BA_ "VNSigAllNodes" SG_ 1922 DTCIUnused7_782 1;
BA_ "SignalType" SG_ 1922 DTCIUnused6_782 "BLN";
BA_ "PacketOrder" SG_ 1922 DTCIUnused6_782 6;
BA_ "SignalLongName" SG_ 1922 DTCIUnused6_782 "Diagnostic Trouble Code Information Extended 782 : Unused 6";
BA_ "VNSigAllNodes" SG_ 1922 DTCIUnused6_782 1;
BA_ "SignalType" SG_ 1922 DTCIUnused5_782 "BLN";
BA_ "PacketOrder" SG_ 1922 DTCIUnused5_782 5;
BA_ "SignalLongName" SG_ 1922 DTCIUnused5_782 "Diagnostic Trouble Code Information Extended 782 : Unused 5";
BA_ "VNSigAllNodes" SG_ 1922 DTCIUnused5_782 1;
BA_ "SignalType" SG_ 1922 DTCIUnused4_782 "BLN";
BA_ "PacketOrder" SG_ 1922 DTCIUnused4_782 4;
BA_ "SignalLongName" SG_ 1922 DTCIUnused4_782 "Diagnostic Trouble Code Information Extended 782 : Unused 4";
BA_ "VNSigAllNodes" SG_ 1922 DTCIUnused4_782 1;
BA_ "SignalType" SG_ 1922 DTCIUnused3_782 "BLN";
BA_ "PacketOrder" SG_ 1922 DTCIUnused3_782 3;
BA_ "SignalLongName" SG_ 1922 DTCIUnused3_782 "Diagnostic Trouble Code Information Extended 782 : Unused 3";
BA_ "VNSigAllNodes" SG_ 1922 DTCIUnused3_782 1;
BA_ "SignalType" SG_ 1922 DTCIUnused2_782 "BLN";
BA_ "PacketOrder" SG_ 1922 DTCIUnused2_782 2;
BA_ "SignalLongName" SG_ 1922 DTCIUnused2_782 "Diagnostic Trouble Code Information Extended 782 : Unused 2";
BA_ "VNSigAllNodes" SG_ 1922 DTCIUnused2_782 1;
BA_ "SignalType" SG_ 1922 DTCIUnused1_782 "BLN";
BA_ "PacketOrder" SG_ 1922 DTCIUnused1_782 1;
BA_ "SignalLongName" SG_ 1922 DTCIUnused1_782 "Diagnostic Trouble Code Information Extended 782 : Unused 1";
BA_ "VNSigAllNodes" SG_ 1922 DTCIUnused1_782 1;
BA_ "SignalType" SG_ 1922 DTCI_TstNPsdPwrUpSt_782 "BLN";
BA_ "PacketOrder" SG_ 1922 DTCI_TstNPsdPwrUpSt_782 14;
BA_ "SignalLongName" SG_ 1922 DTCI_TstNPsdPwrUpSt_782 "Diagnostic Trouble Code Information Extended 782 : Test Not Passed Since Power Up Status";
BA_ "VNSigAllNodes" SG_ 1922 DTCI_TstNPsdPwrUpSt_782 1;
BA_ "SignalType" SG_ 1922 DTCI_TstNPsdCdClrdSt_782 "BLN";
BA_ "PacketOrder" SG_ 1922 DTCI_TstNPsdCdClrdSt_782 17;
BA_ "SignalLongName" SG_ 1922 DTCI_TstNPsdCdClrdSt_782 "Diagnostic Trouble Code Information Extended 782 : Test Not Passed Since Code Cleared Status";
BA_ "VNSigAllNodes" SG_ 1922 DTCI_TstNPsdCdClrdSt_782 1;
BA_ "SignalType" SG_ 1922 DTCI_TstFldPwrUpSt_782 "BLN";
BA_ "PacketOrder" SG_ 1922 DTCI_TstFldPwrUpSt_782 13;
BA_ "SignalLongName" SG_ 1922 DTCI_TstFldPwrUpSt_782 "Diagnostic Trouble Code Information Extended 782 : Test Failed Since Power Up Status";
BA_ "VNSigAllNodes" SG_ 1922 DTCI_TstFldPwrUpSt_782 1;
BA_ "SignalType" SG_ 1922 DTCI_TstFldCdClrdStat_782 "BLN";
BA_ "PacketOrder" SG_ 1922 DTCI_TstFldCdClrdStat_782 16;
BA_ "SignalLongName" SG_ 1922 DTCI_TstFldCdClrdStat_782 "Diagnostic Trouble Code Information Extended 782 : Test Failed Since Code Cleared Status";
BA_ "VNSigAllNodes" SG_ 1922 DTCI_TstFldCdClrdStat_782 1;
BA_ "SignalType" SG_ 1922 DTCI_HistStat_782 "BLN";
BA_ "PacketOrder" SG_ 1922 DTCI_HistStat_782 15;
BA_ "SignalLongName" SG_ 1922 DTCI_HistStat_782 "Diagnostic Trouble Code Information Extended 782 : History Status";
BA_ "VNSigAllNodes" SG_ 1922 DTCI_HistStat_782 1;
BA_ "SignalType" SG_ 1922 DTCI_DTCTriggered_782 "BLN";
BA_ "PacketOrder" SG_ 1922 DTCI_DTCTriggered_782 8;
BA_ "SignalLongName" SG_ 1922 DTCI_DTCTriggered_782 "Diagnostic Trouble Code Information Extended 782 : Diagnostic Trouble Code Triggered";
BA_ "VNSigAllNodes" SG_ 1922 DTCI_DTCTriggered_782 1;
BA_ "SignalType" SG_ 1922 DTCI_DTCSource_782 "UNM";
BA_ "PacketOrder" SG_ 1922 DTCI_DTCSource_782 9;
BA_ "SignalLongName" SG_ 1922 DTCI_DTCSource_782 "Diagnostic Trouble Code Information Extended 782 : Diagnostic Trouble Code Source";
BA_ "VNSigAllNodes" SG_ 1922 DTCI_DTCSource_782 1;
BA_ "SignalType" SG_ 1922 DTCI_DTCNumber_782 "UNM";
BA_ "PacketOrder" SG_ 1922 DTCI_DTCNumber_782 10;
BA_ "SignalLongName" SG_ 1922 DTCI_DTCNumber_782 "Diagnostic Trouble Code Information Extended 782 : Diagnostic Trouble Code Number";
BA_ "VNSigAllNodes" SG_ 1922 DTCI_DTCNumber_782 1;
BA_ "SignalType" SG_ 1922 DTCI_DTCFaultType_782 "ENM";
BA_ "PacketOrder" SG_ 1922 DTCI_DTCFaultType_782 20;
BA_ "SignalLongName" SG_ 1922 DTCI_DTCFaultType_782 "Diagnostic Trouble Code Information Extended 782 : Diagnostic Trouble Code Fault Type";
BA_ "VNSigAllNodes" SG_ 1922 DTCI_DTCFaultType_782 1;
BA_ "SignalType" SG_ 1922 DTCI_DTCFailType_782 "UNM";
BA_ "PacketOrder" SG_ 1922 DTCI_DTCFailType_782 11;
BA_ "SignalLongName" SG_ 1922 DTCI_DTCFailType_782 "Diagnostic Trouble Code Information Extended 782 : Diagnostic Trouble Code Failure Type";
BA_ "VNSigAllNodes" SG_ 1922 DTCI_DTCFailType_782 1;
BA_ "SignalType" SG_ 1922 DTCI_CurrentStatus_782 "BLN";
BA_ "PacketOrder" SG_ 1922 DTCI_CurrentStatus_782 18;
BA_ "SignalLongName" SG_ 1922 DTCI_CurrentStatus_782 "Diagnostic Trouble Code Information Extended 782 : Current Status";
BA_ "VNSigAllNodes" SG_ 1922 DTCI_CurrentStatus_782 1;
BA_ "SignalType" SG_ 1922 DTCI_CodeSupported_782 "BLN";
BA_ "PacketOrder" SG_ 1922 DTCI_CodeSupported_782 19;
BA_ "SignalLongName" SG_ 1922 DTCI_CodeSupported_782 "Diagnostic Trouble Code Information Extended 782 : Code Supported";
BA_ "VNSigAllNodes" SG_ 1922 DTCI_CodeSupported_782 1;
BA_ "SignalType" SG_ 1921 DTCI_CurrentStatus_781 "BLN";
BA_ "PacketOrder" SG_ 1921 DTCI_CurrentStatus_781 18;
BA_ "SignalLongName" SG_ 1921 DTCI_CurrentStatus_781 "Diagnostic Trouble Code Information Extended 781: Current Status";
BA_ "VNSigAllNodes" SG_ 1921 DTCI_CurrentStatus_781 1;
BA_ "SignalType" SG_ 1921 DTCI_WrnIndRqdSt_781 "BLN";
BA_ "PacketOrder" SG_ 1921 DTCI_WrnIndRqdSt_781 12;
BA_ "SignalLongName" SG_ 1921 DTCI_WrnIndRqdSt_781 "Diagnostic Trouble Code Information Extended 781 : Warning Indicator Requested Status";
BA_ "VNSigAllNodes" SG_ 1921 DTCI_WrnIndRqdSt_781 1;
BA_ "SignalType" SG_ 1921 DTCIUnused7_781 "BLN";
BA_ "PacketOrder" SG_ 1921 DTCIUnused7_781 7;
BA_ "SignalLongName" SG_ 1921 DTCIUnused7_781 "Diagnostic Trouble Code Information Extended 781 : Unused 7";
BA_ "VNSigAllNodes" SG_ 1921 DTCIUnused7_781 1;
BA_ "SignalType" SG_ 1921 DTCIUnused6_781 "BLN";
BA_ "PacketOrder" SG_ 1921 DTCIUnused6_781 6;
BA_ "SignalLongName" SG_ 1921 DTCIUnused6_781 "Diagnostic Trouble Code Information Extended 781 : Unused 6";
BA_ "VNSigAllNodes" SG_ 1921 DTCIUnused6_781 1;
BA_ "SignalType" SG_ 1921 DTCIUnused5_781 "BLN";
BA_ "PacketOrder" SG_ 1921 DTCIUnused5_781 5;
BA_ "SignalLongName" SG_ 1921 DTCIUnused5_781 "Diagnostic Trouble Code Information Extended 781 : Unused 5";
BA_ "VNSigAllNodes" SG_ 1921 DTCIUnused5_781 1;
BA_ "SignalType" SG_ 1921 DTCIUnused4_781 "BLN";
BA_ "PacketOrder" SG_ 1921 DTCIUnused4_781 4;
BA_ "SignalLongName" SG_ 1921 DTCIUnused4_781 "Diagnostic Trouble Code Information Extended 781 : Unused 4";
BA_ "VNSigAllNodes" SG_ 1921 DTCIUnused4_781 1;
BA_ "SignalType" SG_ 1921 DTCIUnused3_781 "BLN";
BA_ "PacketOrder" SG_ 1921 DTCIUnused3_781 3;
BA_ "SignalLongName" SG_ 1921 DTCIUnused3_781 "Diagnostic Trouble Code Information Extended 781 : Unused 3";
BA_ "VNSigAllNodes" SG_ 1921 DTCIUnused3_781 1;
BA_ "SignalType" SG_ 1921 DTCIUnused2_781 "BLN";
BA_ "PacketOrder" SG_ 1921 DTCIUnused2_781 2;
BA_ "SignalLongName" SG_ 1921 DTCIUnused2_781 "Diagnostic Trouble Code Information Extended 781 : Unused 2";
BA_ "VNSigAllNodes" SG_ 1921 DTCIUnused2_781 1;
BA_ "SignalType" SG_ 1921 DTCIUnused1_781 "BLN";
BA_ "PacketOrder" SG_ 1921 DTCIUnused1_781 1;
BA_ "SignalLongName" SG_ 1921 DTCIUnused1_781 "Diagnostic Trouble Code Information Extended 781 : Unused 1";
BA_ "VNSigAllNodes" SG_ 1921 DTCIUnused1_781 1;
BA_ "SignalType" SG_ 1921 DTCI_TstNPsdPwrUpSt_781 "BLN";
BA_ "PacketOrder" SG_ 1921 DTCI_TstNPsdPwrUpSt_781 14;
BA_ "SignalLongName" SG_ 1921 DTCI_TstNPsdPwrUpSt_781 "Diagnostic Trouble Code Information Extended 781 : Test Not Passed Since Power Up Status";
BA_ "VNSigAllNodes" SG_ 1921 DTCI_TstNPsdPwrUpSt_781 1;
BA_ "SignalType" SG_ 1921 DTCI_TstNPsdCdClrdSt_781 "BLN";
BA_ "PacketOrder" SG_ 1921 DTCI_TstNPsdCdClrdSt_781 17;
BA_ "SignalLongName" SG_ 1921 DTCI_TstNPsdCdClrdSt_781 "Diagnostic Trouble Code Information Extended 781 : Test Not Passed Since Code Cleared Status";
BA_ "VNSigAllNodes" SG_ 1921 DTCI_TstNPsdCdClrdSt_781 1;
BA_ "SignalType" SG_ 1921 DTCI_TstFldPwrUpSt_781 "BLN";
BA_ "PacketOrder" SG_ 1921 DTCI_TstFldPwrUpSt_781 13;
BA_ "SignalLongName" SG_ 1921 DTCI_TstFldPwrUpSt_781 "Diagnostic Trouble Code Information Extended 781 : Test Failed Since Power Up Status";
BA_ "VNSigAllNodes" SG_ 1921 DTCI_TstFldPwrUpSt_781 1;
BA_ "SignalType" SG_ 1921 DTCI_TstFldCdClrdStat_781 "BLN";
BA_ "PacketOrder" SG_ 1921 DTCI_TstFldCdClrdStat_781 16;
BA_ "SignalLongName" SG_ 1921 DTCI_TstFldCdClrdStat_781 "Diagnostic Trouble Code Information Extended 781 : Test Failed Since Code Cleared Status";
BA_ "VNSigAllNodes" SG_ 1921 DTCI_TstFldCdClrdStat_781 1;
BA_ "SignalType" SG_ 1921 DTCI_HistStat_781 "BLN";
BA_ "PacketOrder" SG_ 1921 DTCI_HistStat_781 15;
BA_ "SignalLongName" SG_ 1921 DTCI_HistStat_781 "Diagnostic Trouble Code Information Extended 781 : History Status";
BA_ "VNSigAllNodes" SG_ 1921 DTCI_HistStat_781 1;
BA_ "SignalType" SG_ 1921 DTCI_DTCTriggered_781 "BLN";
BA_ "PacketOrder" SG_ 1921 DTCI_DTCTriggered_781 8;
BA_ "SignalLongName" SG_ 1921 DTCI_DTCTriggered_781 "Diagnostic Trouble Code Information Extended 781 : Diagnostic Trouble Code Triggered";
BA_ "VNSigAllNodes" SG_ 1921 DTCI_DTCTriggered_781 1;
BA_ "SignalType" SG_ 1921 DTCI_DTCSource_781 "UNM";
BA_ "PacketOrder" SG_ 1921 DTCI_DTCSource_781 9;
BA_ "SignalLongName" SG_ 1921 DTCI_DTCSource_781 "Diagnostic Trouble Code Information Extended 781 : Diagnostic Trouble Code Source";
BA_ "VNSigAllNodes" SG_ 1921 DTCI_DTCSource_781 1;
BA_ "SignalType" SG_ 1921 DTCI_DTCNumber_781 "UNM";
BA_ "PacketOrder" SG_ 1921 DTCI_DTCNumber_781 10;
BA_ "SignalLongName" SG_ 1921 DTCI_DTCNumber_781 "Diagnostic Trouble Code Information Extended 781 : Diagnostic Trouble Code Number";
BA_ "VNSigAllNodes" SG_ 1921 DTCI_DTCNumber_781 1;
BA_ "SignalType" SG_ 1921 DTCI_DTCFaultType_781 "ENM";
BA_ "PacketOrder" SG_ 1921 DTCI_DTCFaultType_781 20;
BA_ "SignalLongName" SG_ 1921 DTCI_DTCFaultType_781 "Diagnostic Trouble Code Information Extended 781 : Diagnostic Trouble Code Fault Type";
BA_ "VNSigAllNodes" SG_ 1921 DTCI_DTCFaultType_781 1;
BA_ "SignalType" SG_ 1921 DTCI_DTCFailType_781 "UNM";
BA_ "PacketOrder" SG_ 1921 DTCI_DTCFailType_781 11;
BA_ "SignalLongName" SG_ 1921 DTCI_DTCFailType_781 "Diagnostic Trouble Code Information Extended 781 : Diagnostic Trouble Code Failure Type";
BA_ "VNSigAllNodes" SG_ 1921 DTCI_DTCFailType_781 1;
BA_ "SignalType" SG_ 1921 DTCI_CodeSupported_781 "BLN";
BA_ "PacketOrder" SG_ 1921 DTCI_CodeSupported_781 19;
BA_ "SignalLongName" SG_ 1921 DTCI_CodeSupported_781 "Diagnostic Trouble Code Information Extended 781 : Code Supported";
BA_ "VNSigAllNodes" SG_ 1921 DTCI_CodeSupported_781 1;
BA_ "VNSigSLHSSharedDiagnostic" SG_ 2034 DgnInf 1;
BA_ "SignalType" SG_ 2034 DgnInf "UNM";
BA_ "SignalLongName" SG_ 2034 DgnInf "Diagnostic Information";
BA_ "VNSigAllNodes" SG_ 2034 DgnInf 1;
BA_ "VNSigSLHSSharedDiagnostic" SG_ 2032 DgnInf 1;
BA_ "SignalType" SG_ 2032 DgnInf "UNM";
BA_ "SignalLongName" SG_ 2032 DgnInf "Diagnostic Information";
BA_ "VNSigAllNodes" SG_ 2032 DgnInf 1;
BA_ "SignalType" SG_ 201 EngTrqActExtRngV "ENM";
BA_ "SignalLongName" SG_ 201 EngTrqActExtRngV "Engine Torque Actual Extended Range Validity";
BA_ "VNSigAllNodes" SG_ 201 EngTrqActExtRngV 1;
BA_ "SignalType" SG_ 201 EngTrqActExtRng "UNM";
BA_ "SignalLongName" SG_ 201 EngTrqActExtRng "Engine Torque Actual Extended Range";
BA_ "GenSigStartValue" SG_ 201 EngTrqActExtRng 1696;
BA_ "VNSigAllNodes" SG_ 201 EngTrqActExtRng 1;
BA_ "SignalType" SG_ 201 EngRunAtv "BLN";
BA_ "SignalLongName" SG_ 201 EngRunAtv "Engine Run Active";
BA_ "VNSigAllNodes" SG_ 201 EngRunAtv 1;
BA_ "SignalType" SG_ 201 EngOffTmExtRngV "ENM";
BA_ "SignalLongName" SG_ 201 EngOffTmExtRngV "Engine Off Time Extended Range Validity";
BA_ "VNSigAllNodes" SG_ 201 EngOffTmExtRngV 1;
BA_ "SignalType" SG_ 201 EngOffTmExtRng "UNM";
BA_ "SignalLongName" SG_ 201 EngOffTmExtRng "Engine Off Time Extended Range";
BA_ "VNSigAllNodes" SG_ 201 EngOffTmExtRng 1;
BA_ "SignalType" SG_ 201 EngVDA "ENM";
BA_ "SignalLongName" SG_ 201 EngVDA "Engine Virtual Device Availability";
BA_ "GenSigStartValue" SG_ 201 EngVDA 1;
BA_ "VNSigAllNodes" SG_ 201 EngVDA 1;
BA_ "SignalType" SG_ 201 PT_CrnkAct "BLN";
BA_ "SignalLongName" SG_ 201 PT_CrnkAct "Powertrain Crank Active";
BA_ "VNSigAllNodes" SG_ 201 PT_CrnkAct 1;
BA_ "SignalType" SG_ 201 Eng12vStrtrMtrCmmdOn "BLN";
BA_ "SignalLongName" SG_ 201 Eng12vStrtrMtrCmmdOn "Engine 12 Volt Starter Motor Commanded On";
BA_ "VNSigAllNodes" SG_ 201 Eng12vStrtrMtrCmmdOn 1;
BA_ "SignalType" SG_ 201 EngSpdStat "ENM";
BA_ "SignalLongName" SG_ 201 EngSpdStat "Engine Speed Status";
BA_ "VNSigAllNodes" SG_ 201 EngSpdStat 1;
BA_ "SignalType" SG_ 201 EngSpd "UNM";
BA_ "SignalLongName" SG_ 201 EngSpd "Engine Speed";
BA_ "VNSigAllNodes" SG_ 201 EngSpd 1;
BA_ "SignalType" SG_ 201 EngRunng "BLN";
BA_ "SignalLongName" SG_ 201 EngRunng "Engine Running";
BA_ "VNSigAllNodes" SG_ 201 EngRunng 1;
BA_ "SignalType" SG_ 201 EngOffTmVDA "ENM";
BA_ "SignalLongName" SG_ 201 EngOffTmVDA "Engine Off Time Virtual Device Availability";
BA_ "GenSigStartValue" SG_ 201 EngOffTmVDA 1;
BA_ "VNSigAllNodes" SG_ 201 EngOffTmVDA 1;
BA_ "SignalType" SG_ 1300 VehIdNmDig2_9 "ASC";
BA_ "SignalLongName" SG_ 1300 VehIdNmDig2_9 "Vehicle Identification Number Digits 2-9";
BA_ "VNSigAllNodes" SG_ 1300 VehIdNmDig2_9 1;
BA_ "SignalType" SG_ 1249 VehIdNmDig10_17 "ASC";
BA_ "SignalLongName" SG_ 1249 VehIdNmDig10_17 "Vehicle Identification Number Digits 10-17";
BA_ "VNSigAllNodes" SG_ 1249 VehIdNmDig10_17 1;
BA_ "SignalType" SG_ 300 MotStBlt2UnblIO "BLN";
BA_ "SignalLongName" SG_ 300 MotStBlt2UnblIO "Motorized Seat Belt 2 Unavailable Indication On";
BA_ "VNSigAllNodes" SG_ 300 MotStBlt2UnblIO 1;
BA_ "SignalType" SG_ 300 MotStBlt2FldIO "BLN";
BA_ "SignalLongName" SG_ 300 MotStBlt2FldIO "Motorized Seat Belt 2 Failed Indication On";
BA_ "VNSigAllNodes" SG_ 300 MotStBlt2FldIO 1;
BA_ "SignalType" SG_ 501 TrnsShftLvrPosV "ENM";
BA_ "SignalLongName" SG_ 501 TrnsShftLvrPosV "Transmission Shift Lever Position Validity";
BA_ "VNSigAllNodes" SG_ 501 TrnsShftLvrPosV 1;
BA_ "SignalType" SG_ 501 TrnsShftLvrPos "ENM";
BA_ "SignalLongName" SG_ 501 TrnsShftLvrPos "Transmission Shift Lever Position";
BA_ "VNSigAllNodes" SG_ 501 TrnsShftLvrPos 1;
BA_ "SignalType" SG_ 501 TrnShftPtrnActStat "ENM";
BA_ "SignalLongName" SG_ 501 TrnShftPtrnActStat "Transmission Shift Pattern Active Status";
BA_ "VNSigAllNodes" SG_ 501 TrnShftPtrnActStat 1;
BA_ "SignalType" SG_ 501 TransEstGearV "ENM";
BA_ "SignalLongName" SG_ 501 TransEstGearV "Transmission Estimated Gear Validity";
BA_ "VNSigAllNodes" SG_ 501 TransEstGearV 1;
BA_ "SignalType" SG_ 501 TransEstGear "ENM";
BA_ "SignalLongName" SG_ 501 TransEstGear "Transmission Estimated Gear";
BA_ "GenSigStartValue" SG_ 501 TransEstGear 15;
BA_ "VNSigAllNodes" SG_ 501 TransEstGear 1;
BA_ "SignalType" SG_ 501 TransTUDMdStat "ENM";
BA_ "SignalLongName" SG_ 501 TransTUDMdStat "Transmission Tap Up/Tap Down Mode Status";
BA_ "VNSigAllNodes" SG_ 501 TransTUDMdStat 1;
BA_ "SignalType" SG_ 501 TrnsSftMdStat "ENM";
BA_ "SignalLongName" SG_ 501 TrnsSftMdStat "Transmission Shift Mode Status";
BA_ "VNSigAllNodes" SG_ 501 TrnsSftMdStat 1;
BA_ "SignalType" SG_ 1920 DTCI_CurrentStatus_780 "BLN";
BA_ "PacketOrder" SG_ 1920 DTCI_CurrentStatus_780 18;
BA_ "SignalLongName" SG_ 1920 DTCI_CurrentStatus_780 "Diagnostic Trouble Code Information Extended 780 : Current Status";
BA_ "VNSigAllNodes" SG_ 1920 DTCI_CurrentStatus_780 1;
BA_ "SignalType" SG_ 1920 DTCI_WrnIndRqdSt_780 "BLN";
BA_ "PacketOrder" SG_ 1920 DTCI_WrnIndRqdSt_780 12;
BA_ "SignalLongName" SG_ 1920 DTCI_WrnIndRqdSt_780 "Diagnostic Trouble Code Information Extended 780 : Warning Indicator Requested Status";
BA_ "VNSigAllNodes" SG_ 1920 DTCI_WrnIndRqdSt_780 1;
BA_ "SignalType" SG_ 1920 DTCIUnused7_780 "BLN";
BA_ "PacketOrder" SG_ 1920 DTCIUnused7_780 7;
BA_ "SignalLongName" SG_ 1920 DTCIUnused7_780 "Diagnostic Trouble Code Information Extended 780 : Unused 7";
BA_ "VNSigAllNodes" SG_ 1920 DTCIUnused7_780 1;
BA_ "SignalType" SG_ 1920 DTCIUnused6_780 "BLN";
BA_ "PacketOrder" SG_ 1920 DTCIUnused6_780 6;
BA_ "SignalLongName" SG_ 1920 DTCIUnused6_780 "Diagnostic Trouble Code Information Extended 780 : Unused 6";
BA_ "VNSigAllNodes" SG_ 1920 DTCIUnused6_780 1;
BA_ "SignalType" SG_ 1920 DTCIUnused5_780 "BLN";
BA_ "PacketOrder" SG_ 1920 DTCIUnused5_780 5;
BA_ "SignalLongName" SG_ 1920 DTCIUnused5_780 "Diagnostic Trouble Code Information Extended 780 : Unused 5";
BA_ "VNSigAllNodes" SG_ 1920 DTCIUnused5_780 1;
BA_ "SignalType" SG_ 1920 DTCIUnused4_780 "BLN";
BA_ "PacketOrder" SG_ 1920 DTCIUnused4_780 4;
BA_ "SignalLongName" SG_ 1920 DTCIUnused4_780 "Diagnostic Trouble Code Information Extended 780 : Unused 4";
BA_ "VNSigAllNodes" SG_ 1920 DTCIUnused4_780 1;
BA_ "SignalType" SG_ 1920 DTCIUnused3_780 "BLN";
BA_ "PacketOrder" SG_ 1920 DTCIUnused3_780 3;
BA_ "SignalLongName" SG_ 1920 DTCIUnused3_780 "Diagnostic Trouble Code Information Extended 780 : Unused 3";
BA_ "VNSigAllNodes" SG_ 1920 DTCIUnused3_780 1;
BA_ "SignalType" SG_ 1920 DTCIUnused2_780 "BLN";
BA_ "PacketOrder" SG_ 1920 DTCIUnused2_780 2;
BA_ "SignalLongName" SG_ 1920 DTCIUnused2_780 "Diagnostic Trouble Code Information Extended 780 : Unused 2";
BA_ "VNSigAllNodes" SG_ 1920 DTCIUnused2_780 1;
BA_ "SignalType" SG_ 1920 DTCIUnused1_780 "BLN";
BA_ "PacketOrder" SG_ 1920 DTCIUnused1_780 1;
BA_ "SignalLongName" SG_ 1920 DTCIUnused1_780 "Diagnostic Trouble Code Information Extended 780 : Unused 1";
BA_ "VNSigAllNodes" SG_ 1920 DTCIUnused1_780 1;
BA_ "SignalType" SG_ 1920 DTCI_TstNPsdPwrUpSt_780 "BLN";
BA_ "PacketOrder" SG_ 1920 DTCI_TstNPsdPwrUpSt_780 14;
BA_ "SignalLongName" SG_ 1920 DTCI_TstNPsdPwrUpSt_780 "Diagnostic Trouble Code Information Extended 780 : Test Not Passed Since Power Up Status";
BA_ "VNSigAllNodes" SG_ 1920 DTCI_TstNPsdPwrUpSt_780 1;
BA_ "SignalType" SG_ 1920 DTCI_TstNPsdCdClrdSt_780 "BLN";
BA_ "PacketOrder" SG_ 1920 DTCI_TstNPsdCdClrdSt_780 17;
BA_ "SignalLongName" SG_ 1920 DTCI_TstNPsdCdClrdSt_780 "Diagnostic Trouble Code Information Extended 780 : Test Not Passed Since Code Cleared Status";
BA_ "VNSigAllNodes" SG_ 1920 DTCI_TstNPsdCdClrdSt_780 1;
BA_ "SignalType" SG_ 1920 DTCI_TstFldPwrUpSt_780 "BLN";
BA_ "PacketOrder" SG_ 1920 DTCI_TstFldPwrUpSt_780 13;
BA_ "SignalLongName" SG_ 1920 DTCI_TstFldPwrUpSt_780 "Diagnostic Trouble Code Information Extended 780 : Test Failed Since Power Up Status";
BA_ "VNSigAllNodes" SG_ 1920 DTCI_TstFldPwrUpSt_780 1;
BA_ "SignalType" SG_ 1920 DTCI_TstFldCdClrdStat_780 "BLN";
BA_ "PacketOrder" SG_ 1920 DTCI_TstFldCdClrdStat_780 16;
BA_ "SignalLongName" SG_ 1920 DTCI_TstFldCdClrdStat_780 "Diagnostic Trouble Code Information Extended 780 : Test Failed Since Code Cleared Status";
BA_ "VNSigAllNodes" SG_ 1920 DTCI_TstFldCdClrdStat_780 1;
BA_ "SignalType" SG_ 1920 DTCI_HistStat_780 "BLN";
BA_ "PacketOrder" SG_ 1920 DTCI_HistStat_780 15;
BA_ "SignalLongName" SG_ 1920 DTCI_HistStat_780 "Diagnostic Trouble Code Information Extended 780 : History Status";
BA_ "VNSigAllNodes" SG_ 1920 DTCI_HistStat_780 1;
BA_ "SignalType" SG_ 1920 DTCI_DTCTriggered_780 "BLN";
BA_ "PacketOrder" SG_ 1920 DTCI_DTCTriggered_780 8;
BA_ "SignalLongName" SG_ 1920 DTCI_DTCTriggered_780 "Diagnostic Trouble Code Information Extended 780 : Diagnostic Trouble Code Triggered";
BA_ "VNSigAllNodes" SG_ 1920 DTCI_DTCTriggered_780 1;
BA_ "SignalType" SG_ 1920 DTCI_DTCSource_780 "UNM";
BA_ "PacketOrder" SG_ 1920 DTCI_DTCSource_780 9;
BA_ "SignalLongName" SG_ 1920 DTCI_DTCSource_780 "Diagnostic Trouble Code Information Extended 780 : Diagnostic Trouble Code Source";
BA_ "VNSigAllNodes" SG_ 1920 DTCI_DTCSource_780 1;
BA_ "SignalType" SG_ 1920 DTCI_DTCNumber_780 "UNM";
BA_ "PacketOrder" SG_ 1920 DTCI_DTCNumber_780 10;
BA_ "SignalLongName" SG_ 1920 DTCI_DTCNumber_780 "Diagnostic Trouble Code Information Extended 780 : Diagnostic Trouble Code Number";
BA_ "VNSigAllNodes" SG_ 1920 DTCI_DTCNumber_780 1;
BA_ "SignalType" SG_ 1920 DTCI_DTCFaultType_780 "ENM";
BA_ "PacketOrder" SG_ 1920 DTCI_DTCFaultType_780 20;
BA_ "SignalLongName" SG_ 1920 DTCI_DTCFaultType_780 "Diagnostic Trouble Code Information Extended 780 : Diagnostic Trouble Code Fault Type";
BA_ "VNSigAllNodes" SG_ 1920 DTCI_DTCFaultType_780 1;
BA_ "SignalType" SG_ 1920 DTCI_DTCFailType_780 "UNM";
BA_ "PacketOrder" SG_ 1920 DTCI_DTCFailType_780 11;
BA_ "SignalLongName" SG_ 1920 DTCI_DTCFailType_780 "Diagnostic Trouble Code Information Extended 780 : Diagnostic Trouble Code Failure Type";
BA_ "VNSigAllNodes" SG_ 1920 DTCI_DTCFailType_780 1;
BA_ "SignalType" SG_ 1920 DTCI_CodeSupported_780 "BLN";
BA_ "PacketOrder" SG_ 1920 DTCI_CodeSupported_780 19;
BA_ "SignalLongName" SG_ 1920 DTCI_CodeSupported_780 "Diagnostic Trouble Code Information Extended 780 : Code Supported";
BA_ "VNSigAllNodes" SG_ 1920 DTCI_CodeSupported_780 1;
BA_ "SignalType" SG_ 381 StrAngSnsPolRat "ENM";
BA_ "SignalLongName" SG_ 381 StrAngSnsPolRat "Steering Angle Sensor Polarity Rationality";
BA_ "VNSigAllNodes" SG_ 381 StrAngSnsPolRat 1;
BA_ "SignalType" SG_ 381 ActVehAccelV "ENM";
BA_ "SignalLongName" SG_ 381 ActVehAccelV "Actual Vehicle Acceleration Validity";
BA_ "VNSigAllNodes" SG_ 381 ActVehAccelV 1;
BA_ "SignalType" SG_ 381 ActVehAccel "SNM";
BA_ "SignalLongName" SG_ 381 ActVehAccel "Actual Vehicle Acceleration";
BA_ "VNSigAllNodes" SG_ 381 ActVehAccel 1;
BA_ "SignalType" SG_ 381 LatAccSnsPolRat "ENM";
BA_ "SignalLongName" SG_ 381 LatAccSnsPolRat "Lateral Acceleration Sensor Polarity Rationality";
BA_ "VNSigAllNodes" SG_ 381 LatAccSnsPolRat 1;
BA_ "SignalType" SG_ 386 VehDynOvrUndrStrV "ENM";
BA_ "SignalLongName" SG_ 386 VehDynOvrUndrStrV "Vehicle Dynamics Over Under Steer Validity";
BA_ "VNSigAllNodes" SG_ 386 VehDynOvrUndrStrV 1;
BA_ "SignalType" SG_ 386 VehDynOvrUndrStr "SNM";
BA_ "SignalLongName" SG_ 386 VehDynOvrUndrStr "Vehicle Dynamics Over Under Steer";
BA_ "VNSigAllNodes" SG_ 386 VehDynOvrUndrStr 1;
BA_ "SignalType" SG_ 386 VSELongAccLoResV "ENM";
BA_ "SignalLongName" SG_ 386 VSELongAccLoResV "Vehicle Stability Enhancement Longitudinal Acceleration Low Resolution Validity";
BA_ "VNSigAllNodes" SG_ 386 VSELongAccLoResV 1;
BA_ "SignalType" SG_ 386 VSELongAccLoRes "SNM";
BA_ "SignalLongName" SG_ 386 VSELongAccLoRes "Vehicle Stability Enhancement Longitudinal Acceleration Low Resolution";
BA_ "VNSigAllNodes" SG_ 386 VSELongAccLoRes 1;
BA_ "SignalType" SG_ 386 VSEAct "BLN";
BA_ "SignalLongName" SG_ 386 VSEAct "Vehicle Stability Enhancement System Active";
BA_ "VNSigAllNodes" SG_ 386 VSEAct 1;
BA_ "SignalType" SG_ 386 VehStabEnhmntStat "ENM";
BA_ "SignalLongName" SG_ 386 VehStabEnhmntStat "Vehicle Stability Enhancement Status";
BA_ "VNSigAllNodes" SG_ 386 VehStabEnhmntStat 1;
BA_ "SignalType" SG_ 386 VehStabEnhmntMd "ENM";
BA_ "SignalLongName" SG_ 386 VehStabEnhmntMd "Vehicle Stability Enhancement Mode";
BA_ "VNSigAllNodes" SG_ 386 VehStabEnhmntMd 1;
BA_ "SignalType" SG_ 842 WhlRotDrctnlSRtNDrvn "ENM";
BA_ "SignalLongName" SG_ 842 WhlRotDrctnlSRtNDrvn "Wheel Rotational Directional Status Right Non Driven";
BA_ "VNSigAllNodes" SG_ 842 WhlRotDrctnlSRtNDrvn 1;
BA_ "SignalType" SG_ 842 WhlRotDrctnlStLfNDrvn "ENM";
BA_ "SignalLongName" SG_ 842 WhlRotDrctnlStLfNDrvn "Wheel Rotational Directional Status Left Non Driven";
BA_ "VNSigAllNodes" SG_ 842 WhlRotDrctnlStLfNDrvn 1;
BA_ "SignalType" SG_ 842 WhlPlsPerRevNonDrvn "UNM";
BA_ "SignalLongName" SG_ 842 WhlPlsPerRevNonDrvn "Wheel Pulses Per Revolution Non Driven";
BA_ "VNSigAllNodes" SG_ 842 WhlPlsPerRevNonDrvn 1;
BA_ "SignalType" SG_ 842 WhlGrndVlctyRtNnDrvnV "ENM";
BA_ "SignalLongName" SG_ 842 WhlGrndVlctyRtNnDrvnV "Wheel Ground Velocity Right Non Driven Validity";
BA_ "VNSigAllNodes" SG_ 842 WhlGrndVlctyRtNnDrvnV 1;
BA_ "SignalType" SG_ 842 WhlGrndVlctyRtNnDrvn "UNM";
BA_ "SignalLongName" SG_ 842 WhlGrndVlctyRtNnDrvn "Wheel Ground Velocity Right Non Driven";
BA_ "VNSigAllNodes" SG_ 842 WhlGrndVlctyRtNnDrvn 1;
BA_ "SignalType" SG_ 842 WhlGrndVlctyLftNnDrvnV "ENM";
BA_ "SignalLongName" SG_ 842 WhlGrndVlctyLftNnDrvnV "Wheel Ground Velocity Left Non Driven Validity";
BA_ "VNSigAllNodes" SG_ 842 WhlGrndVlctyLftNnDrvnV 1;
BA_ "SignalType" SG_ 842 WhlGrndVlctyLftNnDrvn "UNM";
BA_ "SignalLongName" SG_ 842 WhlGrndVlctyLftNnDrvn "Wheel Ground Velocity Left Non Driven";
BA_ "VNSigAllNodes" SG_ 842 WhlGrndVlctyLftNnDrvn 1;
BA_ "SignalType" SG_ 840 WhlRotDrctnlStRtDrvn "ENM";
BA_ "SignalLongName" SG_ 840 WhlRotDrctnlStRtDrvn "Wheel Rotational Directional Status Right Driven";
BA_ "VNSigAllNodes" SG_ 840 WhlRotDrctnlStRtDrvn 1;
BA_ "SignalType" SG_ 840 WhlRotDrctnlStLftDrvn "ENM";
BA_ "SignalLongName" SG_ 840 WhlRotDrctnlStLftDrvn "Wheel Rotational Directional Status Left Driven";
BA_ "VNSigAllNodes" SG_ 840 WhlRotDrctnlStLftDrvn 1;
BA_ "SignalType" SG_ 840 WhlPlsPerRevDrvn "UNM";
BA_ "SignalLongName" SG_ 840 WhlPlsPerRevDrvn "Wheel Pulses Per Revolution Driven";
BA_ "VNSigAllNodes" SG_ 840 WhlPlsPerRevDrvn 1;
BA_ "SignalType" SG_ 840 WhlGrndVlctyRtDrvnV "ENM";
BA_ "SignalLongName" SG_ 840 WhlGrndVlctyRtDrvnV "Wheel Ground Velocity Right Driven Validity";
BA_ "VNSigAllNodes" SG_ 840 WhlGrndVlctyRtDrvnV 1;
BA_ "SignalType" SG_ 840 WhlGrndVlctyRtDrvn "UNM";
BA_ "SignalLongName" SG_ 840 WhlGrndVlctyRtDrvn "Wheel Ground Velocity Right Driven";
BA_ "VNSigAllNodes" SG_ 840 WhlGrndVlctyRtDrvn 1;
BA_ "SignalType" SG_ 840 WhlGrndVlctyLftDrvnV "ENM";
BA_ "SignalLongName" SG_ 840 WhlGrndVlctyLftDrvnV "Wheel Ground Velocity Left Driven Validity";
BA_ "VNSigAllNodes" SG_ 840 WhlGrndVlctyLftDrvnV 1;
BA_ "SignalType" SG_ 840 WhlGrndVlctyLftDrvn "UNM";
BA_ "SignalLongName" SG_ 840 WhlGrndVlctyLftDrvn "Wheel Ground Velocity Left Driven";
BA_ "VNSigAllNodes" SG_ 840 WhlGrndVlctyLftDrvn 1;
BA_ "SignalType" SG_ 489 VSELatAccV "ENM";
BA_ "SignalLongName" SG_ 489 VSELatAccV "Vehicle Stability Enhancement Lateral Acceleration Validity";
BA_ "VNSigAllNodes" SG_ 489 VSELatAccV 1;
BA_ "SignalType" SG_ 489 VSELatAcc "SNM";
BA_ "SignalLongName" SG_ 489 VSELatAcc "Vehicle Stability Enhancement Lateral Acceleration";
BA_ "VNSigAllNodes" SG_ 489 VSELatAcc 1;
BA_ "SignalType" SG_ 489 VhDynCntlSysSt "ENM";
BA_ "SignalLongName" SG_ 489 VhDynCntlSysSt "Vehicle Dynamics Control System Status";
BA_ "VNSigAllNodes" SG_ 489 VhDynCntlSysSt 1;
BA_ "SignalType" SG_ 489 VehDynYawRateV "ENM";
BA_ "SignalLongName" SG_ 489 VehDynYawRateV "Vehicle Dynamics Yaw Rate Validity";
BA_ "VNSigAllNodes" SG_ 489 VehDynYawRateV 1;
BA_ "SignalType" SG_ 489 VehDynYawRate "SNM";
BA_ "SignalLongName" SG_ 489 VehDynYawRate "Vehicle Dynamics Yaw Rate";
BA_ "VNSigAllNodes" SG_ 489 VehDynYawRate 1;
BA_ "SignalType" SG_ 489 TCSysEnbld "BLN";
BA_ "SignalLongName" SG_ 489 TCSysEnbld "Traction Control System Enabled";
BA_ "VNSigAllNodes" SG_ 489 TCSysEnbld 1;
BA_ "SignalType" SG_ 489 TCSysAtv "BLN";
BA_ "SignalLongName" SG_ 489 TCSysAtv "Traction Control System Active";
BA_ "VNSigAllNodes" SG_ 489 TCSysAtv 1;
BA_ "SignalType" SG_ 489 SprTireSt "ENM";
BA_ "SignalLongName" SG_ 489 SprTireSt "Spare Tire Status";
BA_ "VNSigAllNodes" SG_ 489 SprTireSt 1;
BA_ "SignalType" SG_ 489 BrkPdlDrvAppPrsDetcdV "ENM";
BA_ "SignalLongName" SG_ 489 BrkPdlDrvAppPrsDetcdV "Brake Pedal Driver Applied Pressure Detected Validity";
BA_ "VNSigAllNodes" SG_ 489 BrkPdlDrvAppPrsDetcdV 1;
BA_ "SignalType" SG_ 489 BrkPdlDrvAppPrsDetcd "BLN";
BA_ "SignalLongName" SG_ 489 BrkPdlDrvAppPrsDetcd "Brake Pedal Driver Applied Pressure Detected";
BA_ "GenSigStartValue" SG_ 489 BrkPdlDrvAppPrsDetcd 1;
BA_ "VNSigAllNodes" SG_ 489 BrkPdlDrvAppPrsDetcd 1;
BA_ "SignalType" SG_ 485 StrAngSnsChksm "UNM";
BA_ "SignalLongName" SG_ 485 StrAngSnsChksm "Steering Angle Sensor Checksum";
BA_ "VNSigAllNodes" SG_ 485 StrAngSnsChksm 1;
BA_ "SignalType" SG_ 485 StrWhAngGrdV "ENM";
BA_ "SignalLongName" SG_ 485 StrWhAngGrdV "Steering Wheel Angle Gradient Validity";
BA_ "VNSigAllNodes" SG_ 485 StrWhAngGrdV 1;
BA_ "SignalType" SG_ 485 StrWhAngGrdMsk "ENM";
BA_ "SignalLongName" SG_ 485 StrWhAngGrdMsk "Steering Wheel Angle Gradient Mask";
BA_ "VNSigAllNodes" SG_ 485 StrWhAngGrdMsk 1;
BA_ "SignalType" SG_ 485 StrWhAngMsk "ENM";
BA_ "SignalLongName" SG_ 485 StrWhAngMsk "Steering Wheel Angle Mask";
BA_ "VNSigAllNodes" SG_ 485 StrWhAngMsk 1;
BA_ "SignalType" SG_ 485 StrWhlAngSenTyp "ENM";
BA_ "SignalLongName" SG_ 485 StrWhlAngSenTyp "Steering Wheel Angle Sensor Type";
BA_ "VNSigAllNodes" SG_ 485 StrWhlAngSenTyp 1;
BA_ "SignalType" SG_ 485 StrWhlAngSenCalStat "ENM";
BA_ "SignalLongName" SG_ 485 StrWhlAngSenCalStat "Steering Wheel Angle Sensor Calibration Status";
BA_ "VNSigAllNodes" SG_ 485 StrWhlAngSenCalStat 1;
BA_ "SignalType" SG_ 485 StrWhAngGrd "SNM";
BA_ "SignalLongName" SG_ 485 StrWhAngGrd "Steering Wheel Angle Gradient";
BA_ "VNSigAllNodes" SG_ 485 StrWhAngGrd 1;
BA_ "SignalType" SG_ 485 StWhlAngAliveRollCnt "UNM";
BA_ "SignalLongName" SG_ 485 StWhlAngAliveRollCnt "Steering Wheel Angle Alive Rolling Count";
BA_ "VNSigAllNodes" SG_ 485 StWhlAngAliveRollCnt 1;
BA_ "SignalType" SG_ 485 StrWhAngV "ENM";
BA_ "SignalLongName" SG_ 485 StrWhAngV "Steering Wheel Angle Validity";
BA_ "VNSigAllNodes" SG_ 485 StrWhAngV 1;
BA_ "SignalType" SG_ 485 StrWhAng "SNM";
BA_ "SignalLongName" SG_ 485 StrWhAng "Steering Wheel Angle";
BA_ "VNSigAllNodes" SG_ 485 StrWhAng 1;
BA_ "SignalType" SG_ 803 WhlBdySnsHmPosLrnd "BLN";
BA_ "SignalLongName" SG_ 803 WhlBdySnsHmPosLrnd "Wheel to Body Sensors Home Position Learned";
BA_ "VNSigAllNodes" SG_ 803 WhlBdySnsHmPosLrnd 1;
BA_ "SignalType" SG_ 803 WBRP_ARC "UNM";
BA_ "PacketOrder" SG_ 803 WBRP_ARC 2;
BA_ "SignalLongName" SG_ 803 WBRP_ARC "Wheel to Body Relative Position : Alive Rolling Count";
BA_ "VNSigAllNodes" SG_ 803 WBRP_ARC 1;
BA_ "SignalType" SG_ 803 WBRP_Tmestmp "UNM";
BA_ "PacketOrder" SG_ 803 WBRP_Tmestmp 1;
BA_ "SignalLongName" SG_ 803 WBRP_Tmestmp "Wheel to Body Relative Position : Timestamp";
BA_ "VNSigAllNodes" SG_ 803 WBRP_Tmestmp 1;
BA_ "SignalType" SG_ 803 WBRP_RtFrtV "ENM";
BA_ "PacketOrder" SG_ 803 WBRP_RtFrtV 5;
BA_ "SignalLongName" SG_ 803 WBRP_RtFrtV "Wheel to Body Relative Position : Right Front Validity";
BA_ "VNSigAllNodes" SG_ 803 WBRP_RtFrtV 1;
BA_ "SignalType" SG_ 803 WBRP_RtFrt "SNM";
BA_ "PacketOrder" SG_ 803 WBRP_RtFrt 8;
BA_ "SignalLongName" SG_ 803 WBRP_RtFrt "Wheel to Body Relative Position : Right Front";
BA_ "VNSigAllNodes" SG_ 803 WBRP_RtFrt 1;
BA_ "SignalType" SG_ 803 WBRP_RtRrV "ENM";
BA_ "PacketOrder" SG_ 803 WBRP_RtRrV 6;
BA_ "SignalLongName" SG_ 803 WBRP_RtRrV "Wheel to Body Relative Position : Right Rear Validity";
BA_ "VNSigAllNodes" SG_ 803 WBRP_RtRrV 1;
BA_ "SignalType" SG_ 803 WBRP_RtRr "SNM";
BA_ "PacketOrder" SG_ 803 WBRP_RtRr 10;
BA_ "SignalLongName" SG_ 803 WBRP_RtRr "Wheel to Body Relative Position : Right Rear";
BA_ "VNSigAllNodes" SG_ 803 WBRP_RtRr 1;
BA_ "SignalType" SG_ 803 WBRP_LftRrV "ENM";
BA_ "PacketOrder" SG_ 803 WBRP_LftRrV 4;
BA_ "SignalLongName" SG_ 803 WBRP_LftRrV "Wheel to Body Relative Position : Left Rear Validity";
BA_ "VNSigAllNodes" SG_ 803 WBRP_LftRrV 1;
BA_ "SignalType" SG_ 803 WBRP_LftRr "SNM";
BA_ "PacketOrder" SG_ 803 WBRP_LftRr 9;
BA_ "SignalLongName" SG_ 803 WBRP_LftRr "Wheel to Body Relative Position : Left Rear";
BA_ "VNSigAllNodes" SG_ 803 WBRP_LftRr 1;
BA_ "SignalType" SG_ 803 WBRP_LftFrtV "ENM";
BA_ "PacketOrder" SG_ 803 WBRP_LftFrtV 3;
BA_ "SignalLongName" SG_ 803 WBRP_LftFrtV "Wheel to Body Relative Position : Left Front Validity";
BA_ "VNSigAllNodes" SG_ 803 WBRP_LftFrtV 1;
BA_ "SignalType" SG_ 803 WBRP_LftFrt "SNM";
BA_ "PacketOrder" SG_ 803 WBRP_LftFrt 7;
BA_ "SignalLongName" SG_ 803 WBRP_LftFrt "Wheel to Body Relative Position : Left Front";
BA_ "VNSigAllNodes" SG_ 803 WBRP_LftFrt 1;
BA_ "SignalType" SG_ 871 FCMR_RptdChlng "UNM";
BA_ "PacketOrder" SG_ 871 FCMR_RptdChlng 2;
BA_ "SignalLongName" SG_ 871 FCMR_RptdChlng "Front Camera Module Response : Repeated Challenge";
BA_ "VNSigAllNodes" SG_ 871 FCMR_RptdChlng 1;
BA_ "SignalType" SG_ 871 FCMR_Answr "UNM";
BA_ "PacketOrder" SG_ 871 FCMR_Answr 1;
BA_ "SignalLongName" SG_ 871 FCMR_Answr "Front Camera Module Response : Answer";
BA_ "VNSigAllNodes" SG_ 871 FCMR_Answr 1;
BA_ "SignalType" SG_ 873 ElecBrkCntlMdlChlng "UNM";
BA_ "SignalLongName" SG_ 873 ElecBrkCntlMdlChlng "Electronic Brake Control Module Challenge";
BA_ "VNSigAllNodes" SG_ 873 ElecBrkCntlMdlChlng 1;
BA_ "SignalType" SG_ 568 SeatBltPerfMdRq "ENM";
BA_ "SignalLongName" SG_ 568 SeatBltPerfMdRq "Seat Belts Performance Mode Request";
BA_ "VNSigAllNodes" SG_ 568 SeatBltPerfMdRq 1;
BA_ "SignalType" SG_ 568 DrvMdCntrlState "UNM";
BA_ "SignalLongName" SG_ 568 DrvMdCntrlState "Driving Mode Control State";
BA_ "VNSigAllNodes" SG_ 568 DrvMdCntrlState 1;
BA_ "SignalType" SG_ 568 StgSysPerfMdRq "ENM";
BA_ "SignalLongName" SG_ 568 StgSysPerfMdRq "Steering System Performance Mode Request";
BA_ "VNSigAllNodes" SG_ 568 StgSysPerfMdRq 1;
BA_ "SignalType" SG_ 542 BrkSysToEBOOSTDiagMd "ENM";
BA_ "SignalLongName" SG_ 542 BrkSysToEBOOSTDiagMd "Brake System To EBOOST Diagnostic Mode";
BA_ "VNSigAllNodes" SG_ 542 BrkSysToEBOOSTDiagMd 1;
BA_ "SignalType" SG_ 542 BrkSysRlrBnchSmtdSpd "UNM";
BA_ "SignalLongName" SG_ 542 BrkSysRlrBnchSmtdSpd "Brake System Roller Bench Simulated Speed";
BA_ "VNSigAllNodes" SG_ 542 BrkSysRlrBnchSmtdSpd 1;
BA_ "SignalType" SG_ 542 BrkSysRlrBnchSmtdSpdV "ENM";
BA_ "SignalLongName" SG_ 542 BrkSysRlrBnchSmtdSpdV "Brake System Roller Bench Simulated Speed Validity";
BA_ "VNSigAllNodes" SG_ 542 BrkSysRlrBnchSmtdSpdV 1;
BA_ "SignalType" SG_ 542 BrkSysToEBOOST2Chksm "UNM";
BA_ "SignalLongName" SG_ 542 BrkSysToEBOOST2Chksm "Brake System To EBOOST 2 Checksum";
BA_ "VNSigAllNodes" SG_ 542 BrkSysToEBOOST2Chksm 1;
BA_ "SignalType" SG_ 542 BrkSysToEBOOST2ARC "UNM";
BA_ "SignalLongName" SG_ 542 BrkSysToEBOOST2ARC "Brake System To EBOOST 2 Alive Rolling Count";
BA_ "VNSigAllNodes" SG_ 542 BrkSysToEBOOST2ARC 1;
BA_ "SignalType" SG_ 542 BrkSysTgtPresReqAct "BLN";
BA_ "SignalLongName" SG_ 542 BrkSysTgtPresReqAct "Brake System Target Pressure Request Active";
BA_ "VNSigAllNodes" SG_ 542 BrkSysTgtPresReqAct 1;
BA_ "SignalType" SG_ 542 BrkSysTgtPresReq "UNM";
BA_ "SignalLongName" SG_ 542 BrkSysTgtPresReq "Brake System Target Pressure Request";
BA_ "VNSigAllNodes" SG_ 542 BrkSysTgtPresReq 1;
BA_ "SignalType" SG_ 542 BrkSysHgstEstWhlPsrV "ENM";
BA_ "SignalLongName" SG_ 542 BrkSysHgstEstWhlPsrV "Brake System Highest Estimated Wheel Pressure Validity";
BA_ "VNSigAllNodes" SG_ 542 BrkSysHgstEstWhlPsrV 1;
BA_ "SignalType" SG_ 542 BrkSysHgstEstWhlPsr "UNM";
BA_ "SignalLongName" SG_ 542 BrkSysHgstEstWhlPsr "Brake System Highest Estimated Wheel Pressure";
BA_ "VNSigAllNodes" SG_ 542 BrkSysHgstEstWhlPsr 1;
BA_ "SignalType" SG_ 539 BrkSysTgtFlwRtRqAct "BLN";
BA_ "SignalLongName" SG_ 539 BrkSysTgtFlwRtRqAct "Brake System Target Flow Rate Request Active";
BA_ "VNSigAllNodes" SG_ 539 BrkSysTgtFlwRtRqAct 1;
BA_ "SignalType" SG_ 539 BrkSysTgtFlwRtRq "SNM";
BA_ "SignalLongName" SG_ 539 BrkSysTgtFlwRtRq "Brake System Target Flow Rate Request";
BA_ "VNSigAllNodes" SG_ 539 BrkSysTgtFlwRtRq 1;
BA_ "SignalType" SG_ 539 BrkSysPrsBdgTgtReqV "ENM";
BA_ "SignalLongName" SG_ 539 BrkSysPrsBdgTgtReqV "Brake System Pressure Blending Target Request Validity";
BA_ "VNSigAllNodes" SG_ 539 BrkSysPrsBdgTgtReqV 1;
BA_ "SignalType" SG_ 539 BrkSysPresTrgtDrvrV "ENM";
BA_ "SignalLongName" SG_ 539 BrkSysPresTrgtDrvrV "Brake System Pressure Target Driver Validity";
BA_ "VNSigAllNodes" SG_ 539 BrkSysPresTrgtDrvrV 1;
BA_ "SignalType" SG_ 539 BrkSysPresTrgtDrvr "UNM";
BA_ "SignalLongName" SG_ 539 BrkSysPresTrgtDrvr "Brake System Pressure Target Driver";
BA_ "VNSigAllNodes" SG_ 539 BrkSysPresTrgtDrvr 1;
BA_ "SignalType" SG_ 539 BrkSyFrcBdgTgtRqActSt "ENM";
BA_ "SignalLongName" SG_ 539 BrkSyFrcBdgTgtRqActSt "Brake System Force Blending Target Request Active Status";
BA_ "VNSigAllNodes" SG_ 539 BrkSyFrcBdgTgtRqActSt 1;
BA_ "SignalType" SG_ 539 BrkSysPrsBdgTgtReq "UNM";
BA_ "SignalLongName" SG_ 539 BrkSysPrsBdgTgtReq "Brake System Pressure Blending Target Request";
BA_ "VNSigAllNodes" SG_ 539 BrkSysPrsBdgTgtReq 1;
BA_ "SignalType" SG_ 539 BrkSysToEBOOST1Chksm "UNM";
BA_ "SignalLongName" SG_ 539 BrkSysToEBOOST1Chksm "Brake System To EBOOST 1 Checksum";
BA_ "VNSigAllNodes" SG_ 539 BrkSysToEBOOST1Chksm 1;
BA_ "SignalType" SG_ 539 BrkSysToEBOOST1ARC "UNM";
BA_ "SignalLongName" SG_ 539 BrkSysToEBOOST1ARC "Brake System To EBOOST 1 Alive Rolling Count";
BA_ "VNSigAllNodes" SG_ 539 BrkSysToEBOOST1ARC 1;
BA_ "SignalType" SG_ 539 BrkSysABSFldRetnAct "BLN";
BA_ "SignalLongName" SG_ 539 BrkSysABSFldRetnAct "Brake System ABS Fluid Return Active";
BA_ "VNSigAllNodes" SG_ 539 BrkSysABSFldRetnAct 1;
BA_ "SignalType" SG_ 539 BrkSysUncmpMsCylPresV "ENM";
BA_ "SignalLongName" SG_ 539 BrkSysUncmpMsCylPresV "Brake System Uncompensated Master Cylinder Pressure Validity";
BA_ "VNSigAllNodes" SG_ 539 BrkSysUncmpMsCylPresV 1;
BA_ "SignalType" SG_ 539 BrkSysUncmpMsCylPres "UNM";
BA_ "SignalLongName" SG_ 539 BrkSysUncmpMsCylPres "Brake System Uncompensated Master Cylinder Pressure";
BA_ "VNSigAllNodes" SG_ 539 BrkSysUncmpMsCylPres 1;
BA_ "SignalType" SG_ 537 EBrkAstRnotPresCapV "ENM";
BA_ "SignalLongName" SG_ 537 EBrkAstRnotPresCapV "EBrakeAssist Runout Pressure Capacity Validity";
BA_ "VNSigAllNodes" SG_ 537 EBrkAstRnotPresCapV 1;
BA_ "SignalType" SG_ 537 EBrkAstToBrkSysDiagMd "ENM";
BA_ "SignalLongName" SG_ 537 EBrkAstToBrkSysDiagMd "EBrakeAssist to Brake System Diagnostic Mode";
BA_ "VNSigAllNodes" SG_ 537 EBrkAstToBrkSysDiagMd 1;
BA_ "SignalType" SG_ 537 EBrkAstToBrkSys2Chksm "UNM";
BA_ "SignalLongName" SG_ 537 EBrkAstToBrkSys2Chksm "EBrakeAssist to Brake System 2 Checksum";
BA_ "VNSigAllNodes" SG_ 537 EBrkAstToBrkSys2Chksm 1;
BA_ "SignalType" SG_ 537 EBrkAstToBrkSys2ARC "UNM";
BA_ "SignalLongName" SG_ 537 EBrkAstToBrkSys2ARC "EBrakeAssist to Brake System 2 Alive Rolling Count";
BA_ "VNSigAllNodes" SG_ 537 EBrkAstToBrkSys2ARC 1;
BA_ "SignalType" SG_ 537 EBrkAstHydBrkCmpnRq "BLN";
BA_ "SignalLongName" SG_ 537 EBrkAstHydBrkCmpnRq "EBrakeAssist Hydraulic Brake Compensation request";
BA_ "VNSigAllNodes" SG_ 537 EBrkAstHydBrkCmpnRq 1;
BA_ "SignalType" SG_ 537 EBrkAstStat "ENM";
BA_ "SignalLongName" SG_ 537 EBrkAstStat "EBrakeAssist Status";
BA_ "VNSigAllNodes" SG_ 537 EBrkAstStat 1;
BA_ "SignalType" SG_ 537 EBrkAstRnotPresCap "UNM";
BA_ "SignalLongName" SG_ 537 EBrkAstRnotPresCap "EBrakeAssist Runout Pressure Capacity";
BA_ "VNSigAllNodes" SG_ 537 EBrkAstRnotPresCap 1;
BA_ "SignalType" SG_ 537 EBrkAstDrvrApldBrkPdlV "ENM";
BA_ "SignalLongName" SG_ 537 EBrkAstDrvrApldBrkPdlV "EBrakeAssist Driver Applied Brake Pedal Validity";
BA_ "VNSigAllNodes" SG_ 537 EBrkAstDrvrApldBrkPdlV 1;
BA_ "SignalType" SG_ 537 EBrkAstDrvrApldBrkPdl "BLN";
BA_ "SignalLongName" SG_ 537 EBrkAstDrvrApldBrkPdl "EBrakeAssist Driver Applied Brake Pedal";
BA_ "VNSigAllNodes" SG_ 537 EBrkAstDrvrApldBrkPdl 1;
BA_REL_ "GenSigSuprvResp" BU_SG_REL_ ICCM_CE SG_ 516 RCMCII_DataVal 1;
BA_REL_ "GenSigTimeoutMsg" BU_SG_REL_ ICCM_CE SG_ 516 RCMCII_DataVal 516;
BA_REL_ "GenSigTimeoutTime" BU_SG_REL_ ICCM_CE SG_ 516 RCMCII_DataVal 2500;
BA_REL_ "GenSigSuprvResp" BU_SG_REL_ ICCM_CE SG_ 516 RCMCII_DataIndx 1;
BA_REL_ "GenSigTimeoutMsg" BU_SG_REL_ ICCM_CE SG_ 516 RCMCII_DataIndx 516;
BA_REL_ "GenSigTimeoutTime" BU_SG_REL_ ICCM_CE SG_ 516 RCMCII_DataIndx 2500;
BA_REL_ "GenSigSuprvResp" BU_SG_REL_ ICCM_CE SG_ 516 RCMCII_DataStat 1;
BA_REL_ "GenSigTimeoutMsg" BU_SG_REL_ ICCM_CE SG_ 516 RCMCII_DataStat 516;
BA_REL_ "GenSigTimeoutTime" BU_SG_REL_ ICCM_CE SG_ 516 RCMCII_DataStat 2500;
BA_REL_ "GenSigSuprvResp" BU_SG_REL_ ICCM_CE SG_ 514 RCMDSB_DTCStat 1;
BA_REL_ "GenSigTimeoutMsg" BU_SG_REL_ ICCM_CE SG_ 514 RCMDSB_DTCStat 514;
BA_REL_ "GenSigTimeoutTime" BU_SG_REL_ ICCM_CE SG_ 514 RCMDSB_DTCStat 250;
BA_REL_ "GenSigSuprvResp" BU_SG_REL_ ICCM_CE SG_ 514 RCMDSB_DTCIndx 1;
BA_REL_ "GenSigTimeoutMsg" BU_SG_REL_ ICCM_CE SG_ 514 RCMDSB_DTCIndx 514;
BA_REL_ "GenSigTimeoutTime" BU_SG_REL_ ICCM_CE SG_ 514 RCMDSB_DTCIndx 250;
BA_REL_ "GenSigSuprvResp" BU_SG_REL_ ICCM_CE SG_ 514 RCMDSA_DTCStat 1;
BA_REL_ "GenSigTimeoutMsg" BU_SG_REL_ ICCM_CE SG_ 514 RCMDSA_DTCStat 514;
BA_REL_ "GenSigTimeoutTime" BU_SG_REL_ ICCM_CE SG_ 514 RCMDSA_DTCStat 250;
BA_REL_ "GenSigSuprvResp" BU_SG_REL_ ICCM_CE SG_ 514 RCMDSA_DTCIndx 1;
BA_REL_ "GenSigTimeoutMsg" BU_SG_REL_ ICCM_CE SG_ 514 RCMDSA_DTCIndx 514;
BA_REL_ "GenSigTimeoutTime" BU_SG_REL_ ICCM_CE SG_ 514 RCMDSA_DTCIndx 250;
BA_REL_ "GenSigSuprvResp" BU_SG_REL_ ICCM_CE SG_ 521 RMS_RngMtrDfltStat 1;
BA_REL_ "GenSigTimeoutMsg" BU_SG_REL_ ICCM_CE SG_ 521 RMS_RngMtrDfltStat 521;
BA_REL_ "GenSigTimeoutTime" BU_SG_REL_ ICCM_CE SG_ 521 RMS_RngMtrDfltStat 250;
BA_REL_ "GenSigSuprvResp" BU_SG_REL_ ICCM_CE SG_ 521 RMS_RngMtrPstnV 1;
BA_REL_ "GenSigTimeoutMsg" BU_SG_REL_ ICCM_CE SG_ 521 RMS_RngMtrPstnV 521;
BA_REL_ "GenSigTimeoutTime" BU_SG_REL_ ICCM_CE SG_ 521 RMS_RngMtrPstnV 250;
BA_REL_ "GenSigSuprvResp" BU_SG_REL_ ICCM_CE SG_ 521 RMS_RngMtrPstnM 1;
BA_REL_ "GenSigTimeoutMsg" BU_SG_REL_ ICCM_CE SG_ 521 RMS_RngMtrPstnM 521;
BA_REL_ "GenSigTimeoutTime" BU_SG_REL_ ICCM_CE SG_ 521 RMS_RngMtrPstnM 250;
BA_REL_ "GenSigSuprvResp" BU_SG_REL_ ICCM_CE SG_ 521 RMS_RngMtrPstn 1;
BA_REL_ "GenSigTimeoutMsg" BU_SG_REL_ ICCM_CE SG_ 521 RMS_RngMtrPstn 521;
BA_REL_ "GenSigTimeoutTime" BU_SG_REL_ ICCM_CE SG_ 521 RMS_RngMtrPstn 250;
BA_REL_ "GenSigSuprvResp" BU_SG_REL_ TRCM_CE SG_ 519 ClrRngCntMdlLgsDgInf 1;
BA_REL_ "GenSigTimeoutMsg" BU_SG_REL_ TRCM_CE SG_ 519 ClrRngCntMdlLgsDgInf 519;
BA_REL_ "GenSigTimeoutTime" BU_SG_REL_ TRCM_CE SG_ 519 ClrRngCntMdlLgsDgInf 250;
BA_REL_ "GenSigSuprvResp" BU_SG_REL_ TRCM_CE SG_ 519 ElcShftActnRngCmd 1;
BA_REL_ "GenSigTimeoutMsg" BU_SG_REL_ TRCM_CE SG_ 519 ElcShftActnRngCmd 519;
BA_REL_ "GenSigTimeoutTime" BU_SG_REL_ TRCM_CE SG_ 519 ElcShftActnRngCmd 250;
BA_REL_ "GenSigSuprvResp" BU_SG_REL_ SDM_CE SG_ 201 EngRunAtv 1;
BA_REL_ "GenSigTimeoutMsg" BU_SG_REL_ SDM_CE SG_ 201 EngRunAtv 201;
BA_REL_ "GenSigTimeoutTime" BU_SG_REL_ SDM_CE SG_ 201 EngRunAtv 250;
BA_REL_ "GenSigSuprvResp" BU_SG_REL_ ARS_CE SG_ 201 EngRunAtv 1;
BA_REL_ "GenSigTimeoutMsg" BU_SG_REL_ ARS_CE SG_ 201 EngRunAtv 201;
BA_REL_ "GenSigTimeoutTime" BU_SG_REL_ ARS_CE SG_ 201 EngRunAtv 250;
BA_REL_ "GenSigSuprvResp" BU_SG_REL_ ARS_CE SG_ 201 EngSpdStat 1;
BA_REL_ "GenSigTimeoutMsg" BU_SG_REL_ ARS_CE SG_ 201 EngSpdStat 201;
BA_REL_ "GenSigTimeoutTime" BU_SG_REL_ ARS_CE SG_ 201 EngSpdStat 250;
BA_REL_ "GenSigSuprvResp" BU_SG_REL_ ARS_CE SG_ 201 EngSpd 1;
BA_REL_ "GenSigTimeoutMsg" BU_SG_REL_ ARS_CE SG_ 201 EngSpd 201;
BA_REL_ "GenSigTimeoutTime" BU_SG_REL_ ARS_CE SG_ 201 EngSpd 250;
BA_REL_ "GenSigSuprvResp" BU_SG_REL_ RDCM_CE SG_ 201 EngRunng 1;
BA_REL_ "GenSigTimeoutMsg" BU_SG_REL_ RDCM_CE SG_ 201 EngRunng 201;
BA_REL_ "GenSigTimeoutTime" BU_SG_REL_ RDCM_CE SG_ 201 EngRunng 250;
BA_REL_ "GenSigSuprvResp" BU_SG_REL_ EPS_JR_CE SG_ 201 EngOffTmVDA 1;
BA_REL_ "GenSigTimeoutMsg" BU_SG_REL_ EPS_JR_CE SG_ 201 EngOffTmVDA 201;
BA_REL_ "GenSigTimeoutTime" BU_SG_REL_ EPS_JR_CE SG_ 201 EngOffTmVDA 250;
BA_REL_ "GenSigSuprvResp" BU_SG_REL_ MSB1_CE SG_ 300 MotStBlt2UnblIO 1;
BA_REL_ "GenSigTimeoutMsg" BU_SG_REL_ MSB1_CE SG_ 300 MotStBlt2UnblIO 300;
BA_REL_ "GenSigTimeoutTime" BU_SG_REL_ MSB1_CE SG_ 300 MotStBlt2UnblIO 250;
BA_REL_ "GenSigSuprvResp" BU_SG_REL_ MSB1_CE SG_ 300 MotStBlt2FldIO 1;
BA_REL_ "GenSigTimeoutMsg" BU_SG_REL_ MSB1_CE SG_ 300 MotStBlt2FldIO 300;
BA_REL_ "GenSigTimeoutTime" BU_SG_REL_ MSB1_CE SG_ 300 MotStBlt2FldIO 250;
BA_REL_ "GenSigSuprvResp" BU_SG_REL_ EPS_JR_CE SG_ 501 TrnsShftLvrPos 1;
BA_REL_ "GenSigTimeoutMsg" BU_SG_REL_ EPS_JR_CE SG_ 501 TrnsShftLvrPos 501;
BA_REL_ "GenSigTimeoutTime" BU_SG_REL_ EPS_JR_CE SG_ 501 TrnsShftLvrPos 250;
BA_REL_ "GenSigSuprvResp" BU_SG_REL_ APA_CE SG_ 501 TrnsShftLvrPos 1;
BA_REL_ "GenSigTimeoutMsg" BU_SG_REL_ APA_CE SG_ 501 TrnsShftLvrPos 501;
BA_REL_ "GenSigTimeoutTime" BU_SG_REL_ APA_CE SG_ 501 TrnsShftLvrPos 250;
BA_REL_ "GenSigSuprvResp" BU_SG_REL_ MSB1_CE SG_ 501 TransEstGear 1;
BA_REL_ "GenSigTimeoutMsg" BU_SG_REL_ MSB1_CE SG_ 501 TransEstGear 501;
BA_REL_ "GenSigTimeoutTime" BU_SG_REL_ MSB1_CE SG_ 501 TransEstGear 250;
BA_REL_ "GenSigSuprvResp" BU_SG_REL_ MSB2_CE SG_ 501 TransEstGear 1;
BA_REL_ "GenSigTimeoutMsg" BU_SG_REL_ MSB2_CE SG_ 501 TransEstGear 501;
BA_REL_ "GenSigTimeoutTime" BU_SG_REL_ MSB2_CE SG_ 501 TransEstGear 250;
BA_REL_ "GenSigSuprvResp" BU_SG_REL_ FCM_CE SG_ 501 TransEstGear 1;
BA_REL_ "GenSigTimeoutMsg" BU_SG_REL_ FCM_CE SG_ 501 TransEstGear 501;
BA_REL_ "GenSigTimeoutTime" BU_SG_REL_ FCM_CE SG_ 501 TransEstGear 250;
BA_REL_ "GenSigSuprvResp" BU_SG_REL_ EPS_JR_CE SG_ 381 StrAngSnsPolRat 1;
BA_REL_ "GenSigTimeoutMsg" BU_SG_REL_ EPS_JR_CE SG_ 381 StrAngSnsPolRat 381;
BA_REL_ "GenSigTimeoutTime" BU_SG_REL_ EPS_JR_CE SG_ 381 StrAngSnsPolRat 250;
BA_REL_ "GenSigSuprvResp" BU_SG_REL_ EPS_CE SG_ 381 StrAngSnsPolRat 1;
BA_REL_ "GenSigTimeoutMsg" BU_SG_REL_ EPS_CE SG_ 381 StrAngSnsPolRat 381;
BA_REL_ "GenSigTimeoutTime" BU_SG_REL_ EPS_CE SG_ 381 StrAngSnsPolRat 250;
BA_REL_ "GenSigSuprvResp" BU_SG_REL_ EPS_JR_CE SG_ 381 LatAccSnsPolRat 1;
BA_REL_ "GenSigTimeoutMsg" BU_SG_REL_ EPS_JR_CE SG_ 381 LatAccSnsPolRat 381;
BA_REL_ "GenSigTimeoutTime" BU_SG_REL_ EPS_JR_CE SG_ 381 LatAccSnsPolRat 250;
BA_REL_ "GenSigSuprvResp" BU_SG_REL_ EPS_CE SG_ 381 LatAccSnsPolRat 1;
BA_REL_ "GenSigTimeoutMsg" BU_SG_REL_ EPS_CE SG_ 381 LatAccSnsPolRat 381;
BA_REL_ "GenSigTimeoutTime" BU_SG_REL_ EPS_CE SG_ 381 LatAccSnsPolRat 250;
BA_REL_ "GenSigSuprvResp" BU_SG_REL_ EPS_JR_CE SG_ 386 VehDynOvrUndrStr 1;
BA_REL_ "GenSigTimeoutMsg" BU_SG_REL_ EPS_JR_CE SG_ 386 VehDynOvrUndrStr 386;
BA_REL_ "GenSigTimeoutTime" BU_SG_REL_ EPS_JR_CE SG_ 386 VehDynOvrUndrStr 250;
BA_REL_ "GenSigSuprvResp" BU_SG_REL_ EPS_CE SG_ 386 VehDynOvrUndrStr 1;
BA_REL_ "GenSigTimeoutMsg" BU_SG_REL_ EPS_CE SG_ 386 VehDynOvrUndrStr 386;
BA_REL_ "GenSigTimeoutTime" BU_SG_REL_ EPS_CE SG_ 386 VehDynOvrUndrStr 250;
BA_REL_ "GenSigSuprvResp" BU_SG_REL_ RDCM_CE SG_ 386 VSEAct 1;
BA_REL_ "GenSigTimeoutMsg" BU_SG_REL_ RDCM_CE SG_ 386 VSEAct 386;
BA_REL_ "GenSigTimeoutTime" BU_SG_REL_ RDCM_CE SG_ 386 VSEAct 250;
BA_REL_ "GenSigSuprvResp" BU_SG_REL_ MSB1_CE SG_ 386 VSEAct 1;
BA_REL_ "GenSigTimeoutMsg" BU_SG_REL_ MSB1_CE SG_ 386 VSEAct 386;
BA_REL_ "GenSigTimeoutTime" BU_SG_REL_ MSB1_CE SG_ 386 VSEAct 250;
BA_REL_ "GenSigSuprvResp" BU_SG_REL_ MSB2_CE SG_ 386 VSEAct 1;
BA_REL_ "GenSigTimeoutMsg" BU_SG_REL_ MSB2_CE SG_ 386 VSEAct 386;
BA_REL_ "GenSigTimeoutTime" BU_SG_REL_ MSB2_CE SG_ 386 VSEAct 250;
BA_REL_ "GenSigSuprvResp" BU_SG_REL_ EPS_CE SG_ 386 VSEAct 1;
BA_REL_ "GenSigTimeoutMsg" BU_SG_REL_ EPS_CE SG_ 386 VSEAct 386;
BA_REL_ "GenSigTimeoutTime" BU_SG_REL_ EPS_CE SG_ 386 VSEAct 250;
BA_REL_ "GenSigSuprvResp" BU_SG_REL_ MSB1_CE SG_ 386 VehStabEnhmntStat 1;
BA_REL_ "GenSigTimeoutMsg" BU_SG_REL_ MSB1_CE SG_ 386 VehStabEnhmntStat 386;
BA_REL_ "GenSigTimeoutTime" BU_SG_REL_ MSB1_CE SG_ 386 VehStabEnhmntStat 250;
BA_REL_ "GenSigSuprvResp" BU_SG_REL_ MSB2_CE SG_ 386 VehStabEnhmntStat 1;
BA_REL_ "GenSigTimeoutMsg" BU_SG_REL_ MSB2_CE SG_ 386 VehStabEnhmntStat 386;
BA_REL_ "GenSigTimeoutTime" BU_SG_REL_ MSB2_CE SG_ 386 VehStabEnhmntStat 250;
BA_REL_ "GenSigSuprvResp" BU_SG_REL_ MSB1_CE SG_ 386 VehStabEnhmntMd 1;
BA_REL_ "GenSigTimeoutMsg" BU_SG_REL_ MSB1_CE SG_ 386 VehStabEnhmntMd 386;
BA_REL_ "GenSigTimeoutTime" BU_SG_REL_ MSB1_CE SG_ 386 VehStabEnhmntMd 250;
BA_REL_ "GenSigSuprvResp" BU_SG_REL_ MSB2_CE SG_ 386 VehStabEnhmntMd 1;
BA_REL_ "GenSigTimeoutMsg" BU_SG_REL_ MSB2_CE SG_ 386 VehStabEnhmntMd 386;
BA_REL_ "GenSigTimeoutTime" BU_SG_REL_ MSB2_CE SG_ 386 VehStabEnhmntMd 250;
BA_REL_ "GenSigSuprvResp" BU_SG_REL_ ARS_CE SG_ 842 WhlRotDrctnlSRtNDrvn 1;
BA_REL_ "GenSigTimeoutMsg" BU_SG_REL_ ARS_CE SG_ 842 WhlRotDrctnlSRtNDrvn 842;
BA_REL_ "GenSigTimeoutTime" BU_SG_REL_ ARS_CE SG_ 842 WhlRotDrctnlSRtNDrvn 250;
BA_REL_ "GenSigSuprvResp" BU_SG_REL_ APA_CE SG_ 842 WhlRotDrctnlSRtNDrvn 1;
BA_REL_ "GenSigTimeoutMsg" BU_SG_REL_ APA_CE SG_ 842 WhlRotDrctnlSRtNDrvn 842;
BA_REL_ "GenSigTimeoutTime" BU_SG_REL_ APA_CE SG_ 842 WhlRotDrctnlSRtNDrvn 250;
BA_REL_ "GenSigSuprvResp" BU_SG_REL_ ARS_CE SG_ 842 WhlRotDrctnlStLfNDrvn 1;
BA_REL_ "GenSigTimeoutMsg" BU_SG_REL_ ARS_CE SG_ 842 WhlRotDrctnlStLfNDrvn 842;
BA_REL_ "GenSigTimeoutTime" BU_SG_REL_ ARS_CE SG_ 842 WhlRotDrctnlStLfNDrvn 250;
BA_REL_ "GenSigSuprvResp" BU_SG_REL_ APA_CE SG_ 842 WhlRotDrctnlStLfNDrvn 1;
BA_REL_ "GenSigTimeoutMsg" BU_SG_REL_ APA_CE SG_ 842 WhlRotDrctnlStLfNDrvn 842;
BA_REL_ "GenSigTimeoutTime" BU_SG_REL_ APA_CE SG_ 842 WhlRotDrctnlStLfNDrvn 250;
BA_REL_ "GenSigSuprvResp" BU_SG_REL_ ARS_CE SG_ 842 WhlPlsPerRevNonDrvn 1;
BA_REL_ "GenSigTimeoutMsg" BU_SG_REL_ ARS_CE SG_ 842 WhlPlsPerRevNonDrvn 842;
BA_REL_ "GenSigTimeoutTime" BU_SG_REL_ ARS_CE SG_ 842 WhlPlsPerRevNonDrvn 250;
BA_REL_ "GenSigSuprvResp" BU_SG_REL_ APA_CE SG_ 842 WhlPlsPerRevNonDrvn 1;
BA_REL_ "GenSigTimeoutMsg" BU_SG_REL_ APA_CE SG_ 842 WhlPlsPerRevNonDrvn 842;
BA_REL_ "GenSigTimeoutTime" BU_SG_REL_ APA_CE SG_ 842 WhlPlsPerRevNonDrvn 250;
BA_REL_ "GenSigSuprvResp" BU_SG_REL_ EPS_CE SG_ 842 WhlPlsPerRevNonDrvn 1;
BA_REL_ "GenSigTimeoutMsg" BU_SG_REL_ EPS_CE SG_ 842 WhlPlsPerRevNonDrvn 842;
BA_REL_ "GenSigTimeoutTime" BU_SG_REL_ EPS_CE SG_ 842 WhlPlsPerRevNonDrvn 250;
BA_REL_ "GenSigSuprvResp" BU_SG_REL_ ARS_CE SG_ 842 WhlGrndVlctyRtNnDrvn 1;
BA_REL_ "GenSigTimeoutMsg" BU_SG_REL_ ARS_CE SG_ 842 WhlGrndVlctyRtNnDrvn 842;
BA_REL_ "GenSigTimeoutTime" BU_SG_REL_ ARS_CE SG_ 842 WhlGrndVlctyRtNnDrvn 250;
BA_REL_ "GenSigSuprvResp" BU_SG_REL_ SDM_CE SG_ 842 WhlGrndVlctyRtNnDrvn 1;
BA_REL_ "GenSigTimeoutMsg" BU_SG_REL_ SDM_CE SG_ 842 WhlGrndVlctyRtNnDrvn 842;
BA_REL_ "GenSigTimeoutTime" BU_SG_REL_ SDM_CE SG_ 842 WhlGrndVlctyRtNnDrvn 250;
BA_REL_ "GenSigSuprvResp" BU_SG_REL_ APA_CE SG_ 842 WhlGrndVlctyRtNnDrvn 1;
BA_REL_ "GenSigTimeoutMsg" BU_SG_REL_ APA_CE SG_ 842 WhlGrndVlctyRtNnDrvn 842;
BA_REL_ "GenSigTimeoutTime" BU_SG_REL_ APA_CE SG_ 842 WhlGrndVlctyRtNnDrvn 250;
BA_REL_ "GenSigSuprvResp" BU_SG_REL_ MSB1_CE SG_ 842 WhlGrndVlctyRtNnDrvn 1;
BA_REL_ "GenSigTimeoutMsg" BU_SG_REL_ MSB1_CE SG_ 842 WhlGrndVlctyRtNnDrvn 842;
BA_REL_ "GenSigTimeoutTime" BU_SG_REL_ MSB1_CE SG_ 842 WhlGrndVlctyRtNnDrvn 250;
BA_REL_ "GenSigSuprvResp" BU_SG_REL_ MSB2_CE SG_ 842 WhlGrndVlctyRtNnDrvn 1;
BA_REL_ "GenSigTimeoutMsg" BU_SG_REL_ MSB2_CE SG_ 842 WhlGrndVlctyRtNnDrvn 842;
BA_REL_ "GenSigTimeoutTime" BU_SG_REL_ MSB2_CE SG_ 842 WhlGrndVlctyRtNnDrvn 250;
BA_REL_ "GenSigSuprvResp" BU_SG_REL_ EPS_CE SG_ 842 WhlGrndVlctyRtNnDrvn 1;
BA_REL_ "GenSigTimeoutMsg" BU_SG_REL_ EPS_CE SG_ 842 WhlGrndVlctyRtNnDrvn 842;
BA_REL_ "GenSigTimeoutTime" BU_SG_REL_ EPS_CE SG_ 842 WhlGrndVlctyRtNnDrvn 250;
BA_REL_ "GenSigSuprvResp" BU_SG_REL_ ARS_CE SG_ 842 WhlGrndVlctyLftNnDrvn 1;
BA_REL_ "GenSigTimeoutMsg" BU_SG_REL_ ARS_CE SG_ 842 WhlGrndVlctyLftNnDrvn 842;
BA_REL_ "GenSigTimeoutTime" BU_SG_REL_ ARS_CE SG_ 842 WhlGrndVlctyLftNnDrvn 250;
BA_REL_ "GenSigSuprvResp" BU_SG_REL_ SDM_CE SG_ 842 WhlGrndVlctyLftNnDrvn 1;
BA_REL_ "GenSigTimeoutMsg" BU_SG_REL_ SDM_CE SG_ 842 WhlGrndVlctyLftNnDrvn 842;
BA_REL_ "GenSigTimeoutTime" BU_SG_REL_ SDM_CE SG_ 842 WhlGrndVlctyLftNnDrvn 250;
BA_REL_ "GenSigSuprvResp" BU_SG_REL_ MSB1_CE SG_ 842 WhlGrndVlctyLftNnDrvn 1;
BA_REL_ "GenSigTimeoutMsg" BU_SG_REL_ MSB1_CE SG_ 842 WhlGrndVlctyLftNnDrvn 842;
BA_REL_ "GenSigTimeoutTime" BU_SG_REL_ MSB1_CE SG_ 842 WhlGrndVlctyLftNnDrvn 250;
BA_REL_ "GenSigSuprvResp" BU_SG_REL_ MSB2_CE SG_ 842 WhlGrndVlctyLftNnDrvn 1;
BA_REL_ "GenSigTimeoutMsg" BU_SG_REL_ MSB2_CE SG_ 842 WhlGrndVlctyLftNnDrvn 842;
BA_REL_ "GenSigTimeoutTime" BU_SG_REL_ MSB2_CE SG_ 842 WhlGrndVlctyLftNnDrvn 250;
BA_REL_ "GenSigSuprvResp" BU_SG_REL_ EPS_CE SG_ 842 WhlGrndVlctyLftNnDrvn 1;
BA_REL_ "GenSigTimeoutMsg" BU_SG_REL_ EPS_CE SG_ 842 WhlGrndVlctyLftNnDrvn 842;
BA_REL_ "GenSigTimeoutTime" BU_SG_REL_ EPS_CE SG_ 842 WhlGrndVlctyLftNnDrvn 250;
BA_REL_ "GenSigSuprvResp" BU_SG_REL_ APA_CE SG_ 842 WhlGrndVlctyLftNnDrvn 1;
BA_REL_ "GenSigTimeoutMsg" BU_SG_REL_ APA_CE SG_ 842 WhlGrndVlctyLftNnDrvn 842;
BA_REL_ "GenSigTimeoutTime" BU_SG_REL_ APA_CE SG_ 842 WhlGrndVlctyLftNnDrvn 250;
BA_REL_ "GenSigSuprvResp" BU_SG_REL_ ARS_CE SG_ 840 WhlRotDrctnlStRtDrvn 1;
BA_REL_ "GenSigTimeoutMsg" BU_SG_REL_ ARS_CE SG_ 840 WhlRotDrctnlStRtDrvn 840;
BA_REL_ "GenSigTimeoutTime" BU_SG_REL_ ARS_CE SG_ 840 WhlRotDrctnlStRtDrvn 250;
BA_REL_ "GenSigSuprvResp" BU_SG_REL_ APA_CE SG_ 840 WhlRotDrctnlStRtDrvn 1;
BA_REL_ "GenSigTimeoutMsg" BU_SG_REL_ APA_CE SG_ 840 WhlRotDrctnlStRtDrvn 840;
BA_REL_ "GenSigTimeoutTime" BU_SG_REL_ APA_CE SG_ 840 WhlRotDrctnlStRtDrvn 250;
BA_REL_ "GenSigSuprvResp" BU_SG_REL_ ARS_CE SG_ 840 WhlRotDrctnlStLftDrvn 1;
BA_REL_ "GenSigTimeoutMsg" BU_SG_REL_ ARS_CE SG_ 840 WhlRotDrctnlStLftDrvn 840;
BA_REL_ "GenSigTimeoutTime" BU_SG_REL_ ARS_CE SG_ 840 WhlRotDrctnlStLftDrvn 250;
BA_REL_ "GenSigSuprvResp" BU_SG_REL_ APA_CE SG_ 840 WhlRotDrctnlStLftDrvn 1;
BA_REL_ "GenSigTimeoutMsg" BU_SG_REL_ APA_CE SG_ 840 WhlRotDrctnlStLftDrvn 840;
BA_REL_ "GenSigTimeoutTime" BU_SG_REL_ APA_CE SG_ 840 WhlRotDrctnlStLftDrvn 250;
BA_REL_ "GenSigSuprvResp" BU_SG_REL_ ARS_CE SG_ 840 WhlPlsPerRevDrvn 1;
BA_REL_ "GenSigTimeoutMsg" BU_SG_REL_ ARS_CE SG_ 840 WhlPlsPerRevDrvn 840;
BA_REL_ "GenSigTimeoutTime" BU_SG_REL_ ARS_CE SG_ 840 WhlPlsPerRevDrvn 250;
BA_REL_ "GenSigSuprvResp" BU_SG_REL_ APA_CE SG_ 840 WhlPlsPerRevDrvn 1;
BA_REL_ "GenSigTimeoutMsg" BU_SG_REL_ APA_CE SG_ 840 WhlPlsPerRevDrvn 840;
BA_REL_ "GenSigTimeoutTime" BU_SG_REL_ APA_CE SG_ 840 WhlPlsPerRevDrvn 250;
BA_REL_ "GenSigSuprvResp" BU_SG_REL_ EPS_CE SG_ 840 WhlPlsPerRevDrvn 1;
BA_REL_ "GenSigTimeoutMsg" BU_SG_REL_ EPS_CE SG_ 840 WhlPlsPerRevDrvn 840;
BA_REL_ "GenSigTimeoutTime" BU_SG_REL_ EPS_CE SG_ 840 WhlPlsPerRevDrvn 250;
BA_REL_ "GenSigSuprvResp" BU_SG_REL_ ARS_CE SG_ 840 WhlGrndVlctyRtDrvn 1;
BA_REL_ "GenSigTimeoutMsg" BU_SG_REL_ ARS_CE SG_ 840 WhlGrndVlctyRtDrvn 840;
BA_REL_ "GenSigTimeoutTime" BU_SG_REL_ ARS_CE SG_ 840 WhlGrndVlctyRtDrvn 250;
BA_REL_ "GenSigSuprvResp" BU_SG_REL_ SDM_CE SG_ 840 WhlGrndVlctyRtDrvn 1;
BA_REL_ "GenSigTimeoutMsg" BU_SG_REL_ SDM_CE SG_ 840 WhlGrndVlctyRtDrvn 840;
BA_REL_ "GenSigTimeoutTime" BU_SG_REL_ SDM_CE SG_ 840 WhlGrndVlctyRtDrvn 250;
BA_REL_ "GenSigSuprvResp" BU_SG_REL_ FCM_CE SG_ 840 WhlGrndVlctyRtDrvn 1;
BA_REL_ "GenSigTimeoutMsg" BU_SG_REL_ FCM_CE SG_ 840 WhlGrndVlctyRtDrvn 840;
BA_REL_ "GenSigTimeoutTime" BU_SG_REL_ FCM_CE SG_ 840 WhlGrndVlctyRtDrvn 250;
BA_REL_ "GenSigSuprvResp" BU_SG_REL_ APA_CE SG_ 840 WhlGrndVlctyRtDrvn 1;
BA_REL_ "GenSigTimeoutMsg" BU_SG_REL_ APA_CE SG_ 840 WhlGrndVlctyRtDrvn 840;
BA_REL_ "GenSigTimeoutTime" BU_SG_REL_ APA_CE SG_ 840 WhlGrndVlctyRtDrvn 250;
BA_REL_ "GenSigSuprvResp" BU_SG_REL_ MSB1_CE SG_ 840 WhlGrndVlctyRtDrvn 1;
BA_REL_ "GenSigTimeoutMsg" BU_SG_REL_ MSB1_CE SG_ 840 WhlGrndVlctyRtDrvn 840;
BA_REL_ "GenSigTimeoutTime" BU_SG_REL_ MSB1_CE SG_ 840 WhlGrndVlctyRtDrvn 250;
BA_REL_ "GenSigSuprvResp" BU_SG_REL_ MSB2_CE SG_ 840 WhlGrndVlctyRtDrvn 1;
BA_REL_ "GenSigTimeoutMsg" BU_SG_REL_ MSB2_CE SG_ 840 WhlGrndVlctyRtDrvn 840;
BA_REL_ "GenSigTimeoutTime" BU_SG_REL_ MSB2_CE SG_ 840 WhlGrndVlctyRtDrvn 250;
BA_REL_ "GenSigSuprvResp" BU_SG_REL_ EPS_CE SG_ 840 WhlGrndVlctyRtDrvn 1;
BA_REL_ "GenSigTimeoutMsg" BU_SG_REL_ EPS_CE SG_ 840 WhlGrndVlctyRtDrvn 840;
BA_REL_ "GenSigTimeoutTime" BU_SG_REL_ EPS_CE SG_ 840 WhlGrndVlctyRtDrvn 250;
BA_REL_ "GenSigSuprvResp" BU_SG_REL_ ARS_CE SG_ 840 WhlGrndVlctyLftDrvn 1;
BA_REL_ "GenSigTimeoutMsg" BU_SG_REL_ ARS_CE SG_ 840 WhlGrndVlctyLftDrvn 840;
BA_REL_ "GenSigTimeoutTime" BU_SG_REL_ ARS_CE SG_ 840 WhlGrndVlctyLftDrvn 250;
BA_REL_ "GenSigSuprvResp" BU_SG_REL_ SDM_CE SG_ 840 WhlGrndVlctyLftDrvn 1;
BA_REL_ "GenSigTimeoutMsg" BU_SG_REL_ SDM_CE SG_ 840 WhlGrndVlctyLftDrvn 840;
BA_REL_ "GenSigTimeoutTime" BU_SG_REL_ SDM_CE SG_ 840 WhlGrndVlctyLftDrvn 250;
BA_REL_ "GenSigSuprvResp" BU_SG_REL_ FCM_CE SG_ 840 WhlGrndVlctyLftDrvn 1;
BA_REL_ "GenSigTimeoutMsg" BU_SG_REL_ FCM_CE SG_ 840 WhlGrndVlctyLftDrvn 840;
BA_REL_ "GenSigTimeoutTime" BU_SG_REL_ FCM_CE SG_ 840 WhlGrndVlctyLftDrvn 250;
BA_REL_ "GenSigSuprvResp" BU_SG_REL_ MSB1_CE SG_ 840 WhlGrndVlctyLftDrvn 1;
BA_REL_ "GenSigTimeoutMsg" BU_SG_REL_ MSB1_CE SG_ 840 WhlGrndVlctyLftDrvn 840;
BA_REL_ "GenSigTimeoutTime" BU_SG_REL_ MSB1_CE SG_ 840 WhlGrndVlctyLftDrvn 250;
BA_REL_ "GenSigSuprvResp" BU_SG_REL_ MSB2_CE SG_ 840 WhlGrndVlctyLftDrvn 1;
BA_REL_ "GenSigTimeoutMsg" BU_SG_REL_ MSB2_CE SG_ 840 WhlGrndVlctyLftDrvn 840;
BA_REL_ "GenSigTimeoutTime" BU_SG_REL_ MSB2_CE SG_ 840 WhlGrndVlctyLftDrvn 250;
BA_REL_ "GenSigSuprvResp" BU_SG_REL_ EPS_CE SG_ 840 WhlGrndVlctyLftDrvn 1;
BA_REL_ "GenSigTimeoutMsg" BU_SG_REL_ EPS_CE SG_ 840 WhlGrndVlctyLftDrvn 840;
BA_REL_ "GenSigTimeoutTime" BU_SG_REL_ EPS_CE SG_ 840 WhlGrndVlctyLftDrvn 250;
BA_REL_ "GenSigSuprvResp" BU_SG_REL_ APA_CE SG_ 840 WhlGrndVlctyLftDrvn 1;
BA_REL_ "GenSigTimeoutMsg" BU_SG_REL_ APA_CE SG_ 840 WhlGrndVlctyLftDrvn 840;
BA_REL_ "GenSigTimeoutTime" BU_SG_REL_ APA_CE SG_ 840 WhlGrndVlctyLftDrvn 250;
BA_REL_ "GenSigSuprvResp" BU_SG_REL_ MSB1_CE SG_ 489 VSELatAcc 1;
BA_REL_ "GenSigTimeoutMsg" BU_SG_REL_ MSB1_CE SG_ 489 VSELatAcc 489;
BA_REL_ "GenSigTimeoutTime" BU_SG_REL_ MSB1_CE SG_ 489 VSELatAcc 250;
BA_REL_ "GenSigSuprvResp" BU_SG_REL_ MSB2_CE SG_ 489 VSELatAcc 1;
BA_REL_ "GenSigTimeoutMsg" BU_SG_REL_ MSB2_CE SG_ 489 VSELatAcc 489;
BA_REL_ "GenSigTimeoutTime" BU_SG_REL_ MSB2_CE SG_ 489 VSELatAcc 250;
BA_REL_ "GenSigSuprvResp" BU_SG_REL_ EPS_JR_CE SG_ 489 VSELatAcc 1;
BA_REL_ "GenSigTimeoutMsg" BU_SG_REL_ EPS_JR_CE SG_ 489 VSELatAcc 489;
BA_REL_ "GenSigTimeoutTime" BU_SG_REL_ EPS_JR_CE SG_ 489 VSELatAcc 250;
BA_REL_ "GenSigSuprvResp" BU_SG_REL_ MSB1_CE SG_ 489 VehDynYawRate 1;
BA_REL_ "GenSigTimeoutMsg" BU_SG_REL_ MSB1_CE SG_ 489 VehDynYawRate 489;
BA_REL_ "GenSigTimeoutTime" BU_SG_REL_ MSB1_CE SG_ 489 VehDynYawRate 250;
BA_REL_ "GenSigSuprvResp" BU_SG_REL_ MSB2_CE SG_ 489 VehDynYawRate 1;
BA_REL_ "GenSigTimeoutMsg" BU_SG_REL_ MSB2_CE SG_ 489 VehDynYawRate 489;
BA_REL_ "GenSigTimeoutTime" BU_SG_REL_ MSB2_CE SG_ 489 VehDynYawRate 250;
BA_REL_ "GenSigSuprvResp" BU_SG_REL_ RDCM_CE SG_ 489 TCSysAtv 1;
BA_REL_ "GenSigTimeoutMsg" BU_SG_REL_ RDCM_CE SG_ 489 TCSysAtv 489;
BA_REL_ "GenSigTimeoutTime" BU_SG_REL_ RDCM_CE SG_ 489 TCSysAtv 250;
BA_REL_ "GenSigSuprvResp" BU_SG_REL_ EPS_JR_CE SG_ 489 SprTireSt 1;
BA_REL_ "GenSigTimeoutMsg" BU_SG_REL_ EPS_JR_CE SG_ 489 SprTireSt 489;
BA_REL_ "GenSigTimeoutTime" BU_SG_REL_ EPS_JR_CE SG_ 489 SprTireSt 250;
BA_REL_ "GenSigSuprvResp" BU_SG_REL_ EPS_JR_CE SG_ 489 BrkPdlDrvAppPrsDetcd 1;
BA_REL_ "GenSigTimeoutMsg" BU_SG_REL_ EPS_JR_CE SG_ 489 BrkPdlDrvAppPrsDetcd 489;
BA_REL_ "GenSigTimeoutTime" BU_SG_REL_ EPS_JR_CE SG_ 489 BrkPdlDrvAppPrsDetcd 250;
BA_REL_ "GenSigSuprvResp" BU_SG_REL_ APA_CE SG_ 485 StrAngSnsChksm 1;
BA_REL_ "GenSigTimeoutMsg" BU_SG_REL_ APA_CE SG_ 485 StrAngSnsChksm 485;
BA_REL_ "GenSigTimeoutTime" BU_SG_REL_ APA_CE SG_ 485 StrAngSnsChksm 250;
BA_REL_ "GenSigSuprvResp" BU_SG_REL_ FCM_CE SG_ 485 StrAngSnsChksm 1;
BA_REL_ "GenSigTimeoutMsg" BU_SG_REL_ FCM_CE SG_ 485 StrAngSnsChksm 485;
BA_REL_ "GenSigTimeoutTime" BU_SG_REL_ FCM_CE SG_ 485 StrAngSnsChksm 250;
BA_REL_ "GenSigSuprvResp" BU_SG_REL_ EPS_JR_CE SG_ 485 StrAngSnsChksm 1;
BA_REL_ "GenSigTimeoutMsg" BU_SG_REL_ EPS_JR_CE SG_ 485 StrAngSnsChksm 485;
BA_REL_ "GenSigTimeoutTime" BU_SG_REL_ EPS_JR_CE SG_ 485 StrAngSnsChksm 250;
BA_REL_ "GenSigSuprvResp" BU_SG_REL_ APA_CE SG_ 485 StrWhlAngSenTyp 1;
BA_REL_ "GenSigTimeoutMsg" BU_SG_REL_ APA_CE SG_ 485 StrWhlAngSenTyp 485;
BA_REL_ "GenSigTimeoutTime" BU_SG_REL_ APA_CE SG_ 485 StrWhlAngSenTyp 250;
BA_REL_ "GenSigSuprvResp" BU_SG_REL_ ACC_CE SG_ 485 StrWhlAngSenTyp 1;
BA_REL_ "GenSigTimeoutMsg" BU_SG_REL_ ACC_CE SG_ 485 StrWhlAngSenTyp 485;
BA_REL_ "GenSigTimeoutTime" BU_SG_REL_ ACC_CE SG_ 485 StrWhlAngSenTyp 120;
BA_REL_ "GenSigSuprvResp" BU_SG_REL_ FCM_CE SG_ 485 StrWhlAngSenTyp 1;
BA_REL_ "GenSigTimeoutMsg" BU_SG_REL_ FCM_CE SG_ 485 StrWhlAngSenTyp 485;
BA_REL_ "GenSigTimeoutTime" BU_SG_REL_ FCM_CE SG_ 485 StrWhlAngSenTyp 250;
BA_REL_ "GenSigSuprvResp" BU_SG_REL_ ICCM_CE SG_ 485 StrWhlAngSenTyp 1;
BA_REL_ "GenSigTimeoutMsg" BU_SG_REL_ ICCM_CE SG_ 485 StrWhlAngSenTyp 485;
BA_REL_ "GenSigTimeoutTime" BU_SG_REL_ ICCM_CE SG_ 485 StrWhlAngSenTyp 250;
BA_REL_ "GenSigSuprvResp" BU_SG_REL_ EBCM_OBD_CE SG_ 485 StrWhlAngSenTyp 1;
BA_REL_ "GenSigTimeoutMsg" BU_SG_REL_ EBCM_OBD_CE SG_ 485 StrWhlAngSenTyp 485;
BA_REL_ "GenSigTimeoutTime" BU_SG_REL_ EBCM_OBD_CE SG_ 485 StrWhlAngSenTyp 250;
BA_REL_ "GenSigSuprvResp" BU_SG_REL_ EBCM_CE SG_ 485 StrWhlAngSenTyp 1;
BA_REL_ "GenSigTimeoutMsg" BU_SG_REL_ EBCM_CE SG_ 485 StrWhlAngSenTyp 485;
BA_REL_ "GenSigTimeoutTime" BU_SG_REL_ EBCM_CE SG_ 485 StrWhlAngSenTyp 250;
BA_REL_ "GenSigSuprvResp" BU_SG_REL_ EPS_JR_CE SG_ 485 StrWhlAngSenTyp 1;
BA_REL_ "GenSigTimeoutMsg" BU_SG_REL_ EPS_JR_CE SG_ 485 StrWhlAngSenTyp 485;
BA_REL_ "GenSigTimeoutTime" BU_SG_REL_ EPS_JR_CE SG_ 485 StrWhlAngSenTyp 250;
BA_REL_ "GenSigSuprvResp" BU_SG_REL_ EOCM_F_CE SG_ 485 StrWhlAngSenTyp 1;
BA_REL_ "GenSigTimeoutMsg" BU_SG_REL_ EOCM_F_CE SG_ 485 StrWhlAngSenTyp 485;
BA_REL_ "GenSigTimeoutTime" BU_SG_REL_ EOCM_F_CE SG_ 485 StrWhlAngSenTyp 120;
BA_REL_ "GenSigSuprvResp" BU_SG_REL_ EOCM_F_CE SG_ 485 StrWhlAngSenTyp 1;
BA_REL_ "GenSigTimeoutMsg" BU_SG_REL_ EOCM_F_CE SG_ 485 StrWhlAngSenTyp 485;
BA_REL_ "GenSigTimeoutTime" BU_SG_REL_ EOCM_F_CE SG_ 485 StrWhlAngSenTyp 120;
BA_REL_ "GenSigSuprvResp" BU_SG_REL_ FCM_CE SG_ 485 StrWhlAngSenCalStat 1;
BA_REL_ "GenSigTimeoutMsg" BU_SG_REL_ FCM_CE SG_ 485 StrWhlAngSenCalStat 485;
BA_REL_ "GenSigTimeoutTime" BU_SG_REL_ FCM_CE SG_ 485 StrWhlAngSenCalStat 250;
BA_REL_ "GenSigSuprvResp" BU_SG_REL_ EPS_JR_CE SG_ 485 StrWhlAngSenCalStat 1;
BA_REL_ "GenSigTimeoutMsg" BU_SG_REL_ EPS_JR_CE SG_ 485 StrWhlAngSenCalStat 485;
BA_REL_ "GenSigTimeoutTime" BU_SG_REL_ EPS_JR_CE SG_ 485 StrWhlAngSenCalStat 250;
BA_REL_ "GenSigSuprvResp" BU_SG_REL_ FCM_CE SG_ 485 StrWhAngGrd 1;
BA_REL_ "GenSigTimeoutMsg" BU_SG_REL_ FCM_CE SG_ 485 StrWhAngGrd 485;
BA_REL_ "GenSigTimeoutTime" BU_SG_REL_ FCM_CE SG_ 485 StrWhAngGrd 250;
BA_REL_ "GenSigSuprvResp" BU_SG_REL_ EPS_JR_CE SG_ 485 StrWhAngGrd 1;
BA_REL_ "GenSigTimeoutMsg" BU_SG_REL_ EPS_JR_CE SG_ 485 StrWhAngGrd 485;
BA_REL_ "GenSigTimeoutTime" BU_SG_REL_ EPS_JR_CE SG_ 485 StrWhAngGrd 250;
BA_REL_ "GenSigSuprvResp" BU_SG_REL_ MSB1_CE SG_ 485 StrWhAngGrd 1;
BA_REL_ "GenSigTimeoutMsg" BU_SG_REL_ MSB1_CE SG_ 485 StrWhAngGrd 485;
BA_REL_ "GenSigTimeoutTime" BU_SG_REL_ MSB1_CE SG_ 485 StrWhAngGrd 250;
BA_REL_ "GenSigSuprvResp" BU_SG_REL_ MSB2_CE SG_ 485 StrWhAngGrd 1;
BA_REL_ "GenSigTimeoutMsg" BU_SG_REL_ MSB2_CE SG_ 485 StrWhAngGrd 485;
BA_REL_ "GenSigTimeoutTime" BU_SG_REL_ MSB2_CE SG_ 485 StrWhAngGrd 250;
BA_REL_ "GenSigSuprvResp" BU_SG_REL_ ACC_CE SG_ 485 StWhlAngAliveRollCnt 1;
BA_REL_ "GenSigTimeoutMsg" BU_SG_REL_ ACC_CE SG_ 485 StWhlAngAliveRollCnt 485;
BA_REL_ "GenSigTimeoutTime" BU_SG_REL_ ACC_CE SG_ 485 StWhlAngAliveRollCnt 120;
BA_REL_ "GenSigSuprvResp" BU_SG_REL_ APA_CE SG_ 485 StWhlAngAliveRollCnt 1;
BA_REL_ "GenSigTimeoutMsg" BU_SG_REL_ APA_CE SG_ 485 StWhlAngAliveRollCnt 485;
BA_REL_ "GenSigTimeoutTime" BU_SG_REL_ APA_CE SG_ 485 StWhlAngAliveRollCnt 250;
BA_REL_ "GenSigSuprvResp" BU_SG_REL_ FCM_CE SG_ 485 StWhlAngAliveRollCnt 1;
BA_REL_ "GenSigTimeoutMsg" BU_SG_REL_ FCM_CE SG_ 485 StWhlAngAliveRollCnt 485;
BA_REL_ "GenSigTimeoutTime" BU_SG_REL_ FCM_CE SG_ 485 StWhlAngAliveRollCnt 250;
BA_REL_ "GenSigSuprvResp" BU_SG_REL_ EPS_JR_CE SG_ 485 StWhlAngAliveRollCnt 1;
BA_REL_ "GenSigTimeoutMsg" BU_SG_REL_ EPS_JR_CE SG_ 485 StWhlAngAliveRollCnt 485;
BA_REL_ "GenSigTimeoutTime" BU_SG_REL_ EPS_JR_CE SG_ 485 StWhlAngAliveRollCnt 250;
BA_REL_ "GenSigSuprvResp" BU_SG_REL_ EOCM_F_CE SG_ 485 StWhlAngAliveRollCnt 1;
BA_REL_ "GenSigTimeoutMsg" BU_SG_REL_ EOCM_F_CE SG_ 485 StWhlAngAliveRollCnt 485;
BA_REL_ "GenSigTimeoutTime" BU_SG_REL_ EOCM_F_CE SG_ 485 StWhlAngAliveRollCnt 120;
BA_REL_ "GenSigSuprvResp" BU_SG_REL_ EOCM_F_CE SG_ 485 StWhlAngAliveRollCnt 1;
BA_REL_ "GenSigTimeoutMsg" BU_SG_REL_ EOCM_F_CE SG_ 485 StWhlAngAliveRollCnt 485;
BA_REL_ "GenSigTimeoutTime" BU_SG_REL_ EOCM_F_CE SG_ 485 StWhlAngAliveRollCnt 120;
BA_REL_ "GenSigSuprvResp" BU_SG_REL_ FCM_CE SG_ 485 StrWhAng 1;
BA_REL_ "GenSigTimeoutMsg" BU_SG_REL_ FCM_CE SG_ 485 StrWhAng 485;
BA_REL_ "GenSigTimeoutTime" BU_SG_REL_ FCM_CE SG_ 485 StrWhAng 250;
BA_REL_ "GenSigSuprvResp" BU_SG_REL_ EPS_JR_CE SG_ 485 StrWhAng 1;
BA_REL_ "GenSigTimeoutMsg" BU_SG_REL_ EPS_JR_CE SG_ 485 StrWhAng 485;
BA_REL_ "GenSigTimeoutTime" BU_SG_REL_ EPS_JR_CE SG_ 485 StrWhAng 250;
BA_REL_ "GenSigSuprvResp" BU_SG_REL_ MSB1_CE SG_ 485 StrWhAng 1;
BA_REL_ "GenSigTimeoutMsg" BU_SG_REL_ MSB1_CE SG_ 485 StrWhAng 485;
BA_REL_ "GenSigTimeoutTime" BU_SG_REL_ MSB1_CE SG_ 485 StrWhAng 250;
BA_REL_ "GenSigSuprvResp" BU_SG_REL_ MSB2_CE SG_ 485 StrWhAng 1;
BA_REL_ "GenSigTimeoutMsg" BU_SG_REL_ MSB2_CE SG_ 485 StrWhAng 485;
BA_REL_ "GenSigTimeoutTime" BU_SG_REL_ MSB2_CE SG_ 485 StrWhAng 250;
BA_REL_ "GenSigVBitResp" BU_SG_REL_ SADS_CE SG_ 485 StrWhAng 1;
BA_REL_ "GenSigSuprvResp" BU_SG_REL_ SADS_CE SG_ 485 StrWhAng 1;
BA_REL_ "GenSigTimeoutMsg" BU_SG_REL_ SADS_CE SG_ 485 StrWhAng 485;
BA_REL_ "GenSigTimeoutTime" BU_SG_REL_ SADS_CE SG_ 485 StrWhAng 250;
BA_REL_ "GenSigSuprvResp" BU_SG_REL_ EOCM_F_CE SG_ 485 StrWhAng 1;
BA_REL_ "GenSigTimeoutMsg" BU_SG_REL_ EOCM_F_CE SG_ 485 StrWhAng 485;
BA_REL_ "GenSigTimeoutTime" BU_SG_REL_ EOCM_F_CE SG_ 485 StrWhAng 125;
BA_REL_ "GenSigSuprvResp" BU_SG_REL_ EOCM_F_CE SG_ 485 StrWhAng 1;
BA_REL_ "GenSigTimeoutMsg" BU_SG_REL_ EOCM_F_CE SG_ 485 StrWhAng 485;
BA_REL_ "GenSigTimeoutTime" BU_SG_REL_ EOCM_F_CE SG_ 485 StrWhAng 125;
BA_REL_ "GenSigSuprvResp" BU_SG_REL_ ACC_CE SG_ 485 StrWhAng 1;
BA_REL_ "GenSigTimeoutMsg" BU_SG_REL_ ACC_CE SG_ 485 StrWhAng 485;
BA_REL_ "GenSigTimeoutTime" BU_SG_REL_ ACC_CE SG_ 485 StrWhAng 125;
BA_REL_ "GenSigSuprvResp" BU_SG_REL_ ACC_CE SG_ 485 StrWhAng 1;
BA_REL_ "GenSigTimeoutMsg" BU_SG_REL_ ACC_CE SG_ 485 StrWhAng 485;
BA_REL_ "GenSigTimeoutTime" BU_SG_REL_ ACC_CE SG_ 485 StrWhAng 125;
BA_REL_ "GenSigSuprvResp" BU_SG_REL_ SDM_CE SG_ 485 StrWhAng 1;
BA_REL_ "GenSigTimeoutMsg" BU_SG_REL_ SDM_CE SG_ 485 StrWhAng 485;
BA_REL_ "GenSigTimeoutTime" BU_SG_REL_ SDM_CE SG_ 485 StrWhAng 250;
BA_REL_ "GenSigVBitResp" BU_SG_REL_ EBCM_OBD_CE SG_ 485 StrWhAng 1;
BA_REL_ "GenSigSuprvResp" BU_SG_REL_ EBCM_OBD_CE SG_ 485 StrWhAng 1;
BA_REL_ "GenSigTimeoutMsg" BU_SG_REL_ EBCM_OBD_CE SG_ 485 StrWhAng 485;
BA_REL_ "GenSigTimeoutTime" BU_SG_REL_ EBCM_OBD_CE SG_ 485 StrWhAng 250;
BA_REL_ "GenSigVBitResp" BU_SG_REL_ EBCM_CE SG_ 485 StrWhAng 1;
BA_REL_ "GenSigSuprvResp" BU_SG_REL_ EBCM_CE SG_ 485 StrWhAng 1;
BA_REL_ "GenSigTimeoutMsg" BU_SG_REL_ EBCM_CE SG_ 485 StrWhAng 485;
BA_REL_ "GenSigTimeoutTime" BU_SG_REL_ EBCM_CE SG_ 485 StrWhAng 250;
BA_REL_ "GenSigSuprvResp" BU_SG_REL_ EBCM_OBD_CE SG_ 871 FCMR_RptdChlng 1;
BA_REL_ "GenSigTimeoutMsg" BU_SG_REL_ EBCM_OBD_CE SG_ 871 FCMR_RptdChlng 871;
BA_REL_ "GenSigTimeoutTime" BU_SG_REL_ EBCM_OBD_CE SG_ 871 FCMR_RptdChlng 250;
BA_REL_ "GenSigSuprvResp" BU_SG_REL_ EBCM_CE SG_ 871 FCMR_RptdChlng 1;
BA_REL_ "GenSigTimeoutMsg" BU_SG_REL_ EBCM_CE SG_ 871 FCMR_RptdChlng 871;
BA_REL_ "GenSigTimeoutTime" BU_SG_REL_ EBCM_CE SG_ 871 FCMR_RptdChlng 250;
BA_REL_ "GenSigSuprvResp" BU_SG_REL_ EBCM_OBD_CE SG_ 871 FCMR_Answr 1;
BA_REL_ "GenSigTimeoutMsg" BU_SG_REL_ EBCM_OBD_CE SG_ 871 FCMR_Answr 871;
BA_REL_ "GenSigTimeoutTime" BU_SG_REL_ EBCM_OBD_CE SG_ 871 FCMR_Answr 250;
BA_REL_ "GenSigSuprvResp" BU_SG_REL_ EBCM_CE SG_ 871 FCMR_Answr 1;
BA_REL_ "GenSigTimeoutMsg" BU_SG_REL_ EBCM_CE SG_ 871 FCMR_Answr 871;
BA_REL_ "GenSigTimeoutTime" BU_SG_REL_ EBCM_CE SG_ 871 FCMR_Answr 250;
BA_REL_ "GenSigSuprvResp" BU_SG_REL_ FCM_CE SG_ 873 ElecBrkCntlMdlChlng 1;
BA_REL_ "GenSigTimeoutMsg" BU_SG_REL_ FCM_CE SG_ 873 ElecBrkCntlMdlChlng 873;
BA_REL_ "GenSigTimeoutTime" BU_SG_REL_ FCM_CE SG_ 873 ElecBrkCntlMdlChlng 250;
BA_REL_ "GenSigSuprvResp" BU_SG_REL_ MSB1_CE SG_ 568 SeatBltPerfMdRq 1;
BA_REL_ "GenSigTimeoutMsg" BU_SG_REL_ MSB1_CE SG_ 568 SeatBltPerfMdRq 568;
BA_REL_ "GenSigTimeoutTime" BU_SG_REL_ MSB1_CE SG_ 568 SeatBltPerfMdRq 250;
BA_REL_ "GenSigSuprvResp" BU_SG_REL_ MSB2_CE SG_ 568 SeatBltPerfMdRq 1;
BA_REL_ "GenSigTimeoutMsg" BU_SG_REL_ MSB2_CE SG_ 568 SeatBltPerfMdRq 568;
BA_REL_ "GenSigTimeoutTime" BU_SG_REL_ MSB2_CE SG_ 568 SeatBltPerfMdRq 250;
BA_REL_ "GenSigSuprvResp" BU_SG_REL_ EPS_JR_CE SG_ 568 StgSysPerfMdRq 1;
BA_REL_ "GenSigTimeoutMsg" BU_SG_REL_ EPS_JR_CE SG_ 568 StgSysPerfMdRq 568;
BA_REL_ "GenSigTimeoutTime" BU_SG_REL_ EPS_JR_CE SG_ 568 StgSysPerfMdRq 250;
BA_REL_ "GenSigSuprvResp" BU_SG_REL_ EBOOST_CE SG_ 542 BrkSysToEBOOSTDiagMd 1;
BA_REL_ "GenSigTimeoutMsg" BU_SG_REL_ EBOOST_CE SG_ 542 BrkSysToEBOOSTDiagMd 542;
BA_REL_ "GenSigTimeoutTime" BU_SG_REL_ EBOOST_CE SG_ 542 BrkSysToEBOOSTDiagMd 250;
BA_REL_ "GenSigSuprvResp" BU_SG_REL_ EBOOST_CE SG_ 542 BrkSysRlrBnchSmtdSpd 1;
BA_REL_ "GenSigTimeoutMsg" BU_SG_REL_ EBOOST_CE SG_ 542 BrkSysRlrBnchSmtdSpd 542;
BA_REL_ "GenSigTimeoutTime" BU_SG_REL_ EBOOST_CE SG_ 542 BrkSysRlrBnchSmtdSpd 250;
BA_REL_ "GenSigSuprvResp" BU_SG_REL_ EBOOST_CE SG_ 542 BrkSysTgtPresReqAct 1;
BA_REL_ "GenSigTimeoutMsg" BU_SG_REL_ EBOOST_CE SG_ 542 BrkSysTgtPresReqAct 542;
BA_REL_ "GenSigTimeoutTime" BU_SG_REL_ EBOOST_CE SG_ 542 BrkSysTgtPresReqAct 100;
BA_REL_ "GenSigSuprvResp" BU_SG_REL_ EBOOST_CE SG_ 542 BrkSysTgtPresReq 1;
BA_REL_ "GenSigTimeoutMsg" BU_SG_REL_ EBOOST_CE SG_ 542 BrkSysTgtPresReq 542;
BA_REL_ "GenSigTimeoutTime" BU_SG_REL_ EBOOST_CE SG_ 542 BrkSysTgtPresReq 100;
BA_REL_ "GenSigSuprvResp" BU_SG_REL_ EBOOST_CE SG_ 542 BrkSysHgstEstWhlPsr 1;
BA_REL_ "GenSigTimeoutMsg" BU_SG_REL_ EBOOST_CE SG_ 542 BrkSysHgstEstWhlPsr 542;
BA_REL_ "GenSigTimeoutTime" BU_SG_REL_ EBOOST_CE SG_ 542 BrkSysHgstEstWhlPsr 100;
BA_REL_ "GenSigSuprvResp" BU_SG_REL_ EBOOST_CE SG_ 539 BrkSysTgtFlwRtRqAct 1;
BA_REL_ "GenSigTimeoutMsg" BU_SG_REL_ EBOOST_CE SG_ 539 BrkSysTgtFlwRtRqAct 539;
BA_REL_ "GenSigTimeoutTime" BU_SG_REL_ EBOOST_CE SG_ 539 BrkSysTgtFlwRtRqAct 250;
BA_REL_ "GenSigSuprvResp" BU_SG_REL_ EBOOST_CE SG_ 539 BrkSysTgtFlwRtRq 1;
BA_REL_ "GenSigTimeoutMsg" BU_SG_REL_ EBOOST_CE SG_ 539 BrkSysTgtFlwRtRq 539;
BA_REL_ "GenSigTimeoutTime" BU_SG_REL_ EBOOST_CE SG_ 539 BrkSysTgtFlwRtRq 250;
BA_REL_ "GenSigSuprvResp" BU_SG_REL_ EBOOST_CE SG_ 539 BrkSysPresTrgtDrvr 1;
BA_REL_ "GenSigTimeoutMsg" BU_SG_REL_ EBOOST_CE SG_ 539 BrkSysPresTrgtDrvr 539;
BA_REL_ "GenSigTimeoutTime" BU_SG_REL_ EBOOST_CE SG_ 539 BrkSysPresTrgtDrvr 100;
BA_REL_ "GenSigSuprvResp" BU_SG_REL_ EBOOST_CE SG_ 539 BrkSyFrcBdgTgtRqActSt 1;
BA_REL_ "GenSigTimeoutMsg" BU_SG_REL_ EBOOST_CE SG_ 539 BrkSyFrcBdgTgtRqActSt 539;
BA_REL_ "GenSigTimeoutTime" BU_SG_REL_ EBOOST_CE SG_ 539 BrkSyFrcBdgTgtRqActSt 100;
BA_REL_ "GenSigSuprvResp" BU_SG_REL_ EBOOST_CE SG_ 539 BrkSysPrsBdgTgtReq 1;
BA_REL_ "GenSigTimeoutMsg" BU_SG_REL_ EBOOST_CE SG_ 539 BrkSysPrsBdgTgtReq 539;
BA_REL_ "GenSigTimeoutTime" BU_SG_REL_ EBOOST_CE SG_ 539 BrkSysPrsBdgTgtReq 100;
BA_REL_ "GenSigSuprvResp" BU_SG_REL_ EBOOST_CE SG_ 539 BrkSysABSFldRetnAct 1;
BA_REL_ "GenSigTimeoutMsg" BU_SG_REL_ EBOOST_CE SG_ 539 BrkSysABSFldRetnAct 539;
BA_REL_ "GenSigTimeoutTime" BU_SG_REL_ EBOOST_CE SG_ 539 BrkSysABSFldRetnAct 100;
BA_REL_ "GenSigSuprvResp" BU_SG_REL_ EBOOST_CE SG_ 539 BrkSysUncmpMsCylPres 1;
BA_REL_ "GenSigTimeoutMsg" BU_SG_REL_ EBOOST_CE SG_ 539 BrkSysUncmpMsCylPres 539;
BA_REL_ "GenSigTimeoutTime" BU_SG_REL_ EBOOST_CE SG_ 539 BrkSysUncmpMsCylPres 100;
BA_REL_ "GenSigSuprvResp" BU_SG_REL_ EBCM_OBD_CE SG_ 537 EBrkAstToBrkSysDiagMd 1;
BA_REL_ "GenSigTimeoutMsg" BU_SG_REL_ EBCM_OBD_CE SG_ 537 EBrkAstToBrkSysDiagMd 537;
BA_REL_ "GenSigTimeoutTime" BU_SG_REL_ EBCM_OBD_CE SG_ 537 EBrkAstToBrkSysDiagMd 250;
BA_REL_ "GenSigSuprvResp" BU_SG_REL_ EBCM_CE SG_ 537 EBrkAstToBrkSysDiagMd 1;
BA_REL_ "GenSigTimeoutMsg" BU_SG_REL_ EBCM_CE SG_ 537 EBrkAstToBrkSysDiagMd 537;
BA_REL_ "GenSigTimeoutTime" BU_SG_REL_ EBCM_CE SG_ 537 EBrkAstToBrkSysDiagMd 250;
BA_REL_ "GenSigSuprvResp" BU_SG_REL_ EBCM_OBD_CE SG_ 537 EBrkAstHydBrkCmpnRq 1;
BA_REL_ "GenSigTimeoutMsg" BU_SG_REL_ EBCM_OBD_CE SG_ 537 EBrkAstHydBrkCmpnRq 537;
BA_REL_ "GenSigTimeoutTime" BU_SG_REL_ EBCM_OBD_CE SG_ 537 EBrkAstHydBrkCmpnRq 100;
BA_REL_ "GenSigSuprvResp" BU_SG_REL_ EBCM_CE SG_ 537 EBrkAstHydBrkCmpnRq 1;
BA_REL_ "GenSigTimeoutMsg" BU_SG_REL_ EBCM_CE SG_ 537 EBrkAstHydBrkCmpnRq 537;
BA_REL_ "GenSigTimeoutTime" BU_SG_REL_ EBCM_CE SG_ 537 EBrkAstHydBrkCmpnRq 100;
BA_REL_ "GenSigSuprvResp" BU_SG_REL_ EBCM_OBD_CE SG_ 537 EBrkAstStat 1;
BA_REL_ "GenSigTimeoutMsg" BU_SG_REL_ EBCM_OBD_CE SG_ 537 EBrkAstStat 537;
BA_REL_ "GenSigTimeoutTime" BU_SG_REL_ EBCM_OBD_CE SG_ 537 EBrkAstStat 100;
BA_REL_ "GenSigSuprvResp" BU_SG_REL_ EBCM_CE SG_ 537 EBrkAstStat 1;
BA_REL_ "GenSigTimeoutMsg" BU_SG_REL_ EBCM_CE SG_ 537 EBrkAstStat 537;
BA_REL_ "GenSigTimeoutTime" BU_SG_REL_ EBCM_CE SG_ 537 EBrkAstStat 100;
BA_REL_ "GenSigSuprvResp" BU_SG_REL_ EBCM_OBD_CE SG_ 537 EBrkAstRnotPresCap 1;
BA_REL_ "GenSigTimeoutMsg" BU_SG_REL_ EBCM_OBD_CE SG_ 537 EBrkAstRnotPresCap 537;
BA_REL_ "GenSigTimeoutTime" BU_SG_REL_ EBCM_OBD_CE SG_ 537 EBrkAstRnotPresCap 100;
BA_REL_ "GenSigSuprvResp" BU_SG_REL_ EBCM_CE SG_ 537 EBrkAstRnotPresCap 1;
BA_REL_ "GenSigTimeoutMsg" BU_SG_REL_ EBCM_CE SG_ 537 EBrkAstRnotPresCap 537;
BA_REL_ "GenSigTimeoutTime" BU_SG_REL_ EBCM_CE SG_ 537 EBrkAstRnotPresCap 100;
BA_REL_ "GenSigSuprvResp" BU_SG_REL_ EBCM_OBD_CE SG_ 537 EBrkAstDrvrApldBrkPdl 1;
BA_REL_ "GenSigTimeoutMsg" BU_SG_REL_ EBCM_OBD_CE SG_ 537 EBrkAstDrvrApldBrkPdl 537;
BA_REL_ "GenSigTimeoutTime" BU_SG_REL_ EBCM_OBD_CE SG_ 537 EBrkAstDrvrApldBrkPdl 100;
BA_REL_ "GenSigSuprvResp" BU_SG_REL_ EBCM_CE SG_ 537 EBrkAstDrvrApldBrkPdl 1;
BA_REL_ "GenSigTimeoutMsg" BU_SG_REL_ EBCM_CE SG_ 537 EBrkAstDrvrApldBrkPdl 537;
BA_REL_ "GenSigTimeoutTime" BU_SG_REL_ EBCM_CE SG_ 537 EBrkAstDrvrApldBrkPdl 100;
VAL_ 516 RCMCII_DataIndx 31 "Unused and Reserved12" 30 "Unused and Reserved11" 29 "Unused and Reserved10" 28 "Unused and Reserved9" 27 "Unused and Reserved8" 26 "Unused and Reserved7" 25 "Unused and Reserved6" 24 "Unused and Reserved5" 23 "Unused and Reserved4" 22 "Unused and Reserved3" 21 "Unused and Reserved2" 20 "Unused and Reserved1" 19 "CVN Digit 4" 18 "CVN Digit 3" 17 "CVN Digit 2" 16 "CVN Digit 1" 15 "Calibration Identification Digit 16" 14 "Calibration Identification Digit 15" 13 "Calibration Identification Digit 14" 12 "Calibration Identification Digit 13" 11 "Calibration Identification Digit 12" 10 "Calibration Identification Digit 11" 9 "Calibration Identification Digit 10" 8 "Calibration Identification Digit 9" 7 "Calibration Identification Digit 8" 6 "Calibration Identification Digit 7" 5 "Calibration Identification Digit 6" 4 "Calibration Identification Digit 5" 3 "Calibration Identification Digit 4" 2 "Calibration Identification Digit 3" 1 "Calibration Identification Digit 2" 0 "Calibration Identification Digit 1" ;
VAL_ 516 RCMCII_DataStat 1 "Data Available" 0 "Data Not Available" ;
VAL_ 514 RCMDSB_DTCStat 7 "Unused and Reserved3" 6 "Unused and Reserved2" 5 "Unused and Reserved1" 4 "Diagnostic Failed" 3 "Diagnostic Passed" 2 "No Status to Report" 1 "Critically Disabled" 0 "Not Supported " ;
VAL_ 514 RCMDSA_DTCStat 7 "Unused and Reserved3" 6 "Unused and Reserved2" 5 "Unused and Reserved1" 4 "Diagnostic Failed" 3 "Diagnostic Passed" 2 "No Status to Report" 1 "Critically Disabled" 0 "Not Supported " ;
VAL_ 521 RMS_RngMtrDfltStat 3 "Default Functionality" 2 "Degraded Functionality" 1 "Full Functionality" 0 "Status Unknown " ;
VAL_ 521 RMS_RngMtrPstnV 1 "Invalid" 0 "Valid" ;
VAL_ 521 RMS_RngMtrPstnM 1 "Use data" 0 "Do not use data" ;
VAL_ 521 RMS_RngMtrPstn 15 "Unused and Reserved4" 14 "Unused and Reserved3" 13 "Unused and Reserved2" 12 "Unused and Reserved1" 11 "Beyond Drive Reset" 10 "Drive Reset" 9 "Between Drive and Drive Reset" 8 "Drive" 7 "Between Neutral and Drive" 6 "Neutral" 5 "Between Reverse and Neutral" 4 "Reverse" 3 "Between Park and Reverse" 2 "Park" 1 "Beyond Park" 0 "Motor Position Unavailable " ;
VAL_ 519 ClrRngCntMdlLgsDgInf 1 "true" 0 "false" ;
VAL_ 519 ElcShftActnRngCmd 7 "Unused and Reserved2" 6 "Unused and Reserved1" 5 "Drive Reset" 4 "Drive " 3 "Neutral" 2 "Reverse" 1 "Park" 0 "No Action " ;
VAL_ 1931 DTCI_CodeSupported_78B 1 "true" 0 "false" ;
VAL_ 1931 DTCI_CurrentStatus_78B 1 "true" 0 "false" ;
VAL_ 1931 DTCI_DTCFaultType_78B 3 "Type C" 2 "Type B" 1 "Type A" 0 "Not Supported" ;
VAL_ 1931 DTCI_DTCTriggered_78B 1 "true" 0 "false" ;
VAL_ 1931 DTCI_HistStat_78B 1 "true" 0 "false" ;
VAL_ 1931 DTCI_TstFldCdClrdStat_78B 1 "true" 0 "false" ;
VAL_ 1931 DTCI_TstFldPwrUpSt_78B 1 "true" 0 "false" ;
VAL_ 1931 DTCI_TstNPsdCdClrdSt_78B 1 "true" 0 "false" ;
VAL_ 1931 DTCI_TstNPsdPwrUpSt_78B 1 "true" 0 "false" ;
VAL_ 1931 DTCIUnused1_78B 1 "true" 0 "false" ;
VAL_ 1931 DTCIUnused2_78B 1 "true" 0 "false" ;
VAL_ 1931 DTCIUnused3_78B 1 "true" 0 "false" ;
VAL_ 1931 DTCIUnused4_78B 1 "true" 0 "false" ;
VAL_ 1931 DTCIUnused5_78B 1 "true" 0 "false" ;
VAL_ 1931 DTCIUnused6_78B 1 "true" 0 "false" ;
VAL_ 1931 DTCIUnused7_78B 1 "true" 0 "false" ;
VAL_ 1931 DTCI_WrnIndRqdSt_78B 1 "true" 0 "false" ;
VAL_ 1923 DTCI_WrnIndRqdSt_783 1 "true" 0 "false" ;
VAL_ 1923 DTCI_TstNPsdPwrUpSt_783 1 "true" 0 "false" ;
VAL_ 1923 DTCI_TstNPsdCdClrdSt_783 1 "true" 0 "false" ;
VAL_ 1923 DTCI_TstFldPwrUpSt_783 1 "true" 0 "false" ;
VAL_ 1923 DTCI_TstFldCdClrdStat_783 1 "true" 0 "false" ;
VAL_ 1923 DTCI_HistStat_783 1 "true" 0 "false" ;
VAL_ 1923 DTCI_DTCTriggered_783 1 "true" 0 "false" ;
VAL_ 1923 DTCI_DTCFaultType_783 3 "Type C" 2 "Type B" 1 "Type A" 0 "Not Supported" ;
VAL_ 1923 DTCI_CurrentStatus_783 1 "true" 0 "false" ;
VAL_ 1923 DTCI_CodeSupported_783 1 "true" 0 "false" ;
VAL_ 1923 DTCIUnused7_783 1 "true" 0 "false" ;
VAL_ 1923 DTCIUnused6_783 1 "true" 0 "false" ;
VAL_ 1923 DTCIUnused5_783 1 "true" 0 "false" ;
VAL_ 1923 DTCIUnused4_783 1 "true" 0 "false" ;
VAL_ 1923 DTCIUnused3_783 1 "true" 0 "false" ;
VAL_ 1923 DTCIUnused2_783 1 "true" 0 "false" ;
VAL_ 1923 DTCIUnused1_783 1 "true" 0 "false" ;
VAL_ 1922 DTCI_WrnIndRqdSt_782 1 "true" 0 "false" ;
VAL_ 1922 DTCIUnused7_782 1 "true" 0 "false" ;
VAL_ 1922 DTCIUnused6_782 1 "true" 0 "false" ;
VAL_ 1922 DTCIUnused5_782 1 "true" 0 "false" ;
VAL_ 1922 DTCIUnused4_782 1 "true" 0 "false" ;
VAL_ 1922 DTCIUnused3_782 1 "true" 0 "false" ;
VAL_ 1922 DTCIUnused2_782 1 "true" 0 "false" ;
VAL_ 1922 DTCIUnused1_782 1 "true" 0 "false" ;
VAL_ 1922 DTCI_TstNPsdPwrUpSt_782 1 "true" 0 "false" ;
VAL_ 1922 DTCI_TstNPsdCdClrdSt_782 1 "true" 0 "false" ;
VAL_ 1922 DTCI_TstFldPwrUpSt_782 1 "true" 0 "false" ;
VAL_ 1922 DTCI_TstFldCdClrdStat_782 1 "true" 0 "false" ;
VAL_ 1922 DTCI_HistStat_782 1 "true" 0 "false" ;
VAL_ 1922 DTCI_DTCTriggered_782 1 "true" 0 "false" ;
VAL_ 1922 DTCI_DTCFaultType_782 3 "Type C" 2 "Type B" 1 "Type A" 0 "Not Supported" ;
VAL_ 1922 DTCI_CurrentStatus_782 1 "true" 0 "false" ;
VAL_ 1922 DTCI_CodeSupported_782 1 "true" 0 "false" ;
VAL_ 1921 DTCI_CurrentStatus_781 1 "true" 0 "false" ;
VAL_ 1921 DTCI_WrnIndRqdSt_781 1 "true" 0 "false" ;
VAL_ 1921 DTCIUnused7_781 1 "true" 0 "false" ;
VAL_ 1921 DTCIUnused6_781 1 "true" 0 "false" ;
VAL_ 1921 DTCIUnused5_781 1 "true" 0 "false" ;
VAL_ 1921 DTCIUnused4_781 1 "true" 0 "false" ;
VAL_ 1921 DTCIUnused3_781 1 "true" 0 "false" ;
VAL_ 1921 DTCIUnused2_781 1 "true" 0 "false" ;
VAL_ 1921 DTCIUnused1_781 1 "true" 0 "false" ;
VAL_ 1921 DTCI_TstNPsdPwrUpSt_781 1 "true" 0 "false" ;
VAL_ 1921 DTCI_TstNPsdCdClrdSt_781 1 "true" 0 "false" ;
VAL_ 1921 DTCI_TstFldPwrUpSt_781 1 "true" 0 "false" ;
VAL_ 1921 DTCI_TstFldCdClrdStat_781 1 "true" 0 "false" ;
VAL_ 1921 DTCI_HistStat_781 1 "true" 0 "false" ;
VAL_ 1921 DTCI_DTCTriggered_781 1 "true" 0 "false" ;
VAL_ 1921 DTCI_DTCFaultType_781 3 "Type C" 2 "Type B" 1 "Type A" 0 "Not Supported" ;
VAL_ 1921 DTCI_CodeSupported_781 1 "true" 0 "false" ;
VAL_ 201 EngTrqActExtRngV 1 "Invalid" 0 "Valid" ;
VAL_ 201 EngRunAtv 1 "true" 0 "false" ;
VAL_ 201 EngOffTmExtRngV 1 "Invalid" 0 "Valid" ;
VAL_ 201 EngVDA 1 "VirtualDeviceAvailable" 0 "VirtualDeviceUnavailable" ;
VAL_ 201 PT_CrnkAct 1 "true" 0 "false" ;
VAL_ 201 Eng12vStrtrMtrCmmdOn 1 "true" 0 "false" ;
VAL_ 201 EngSpdStat 3 "Invalid" 1 "Degraded Operation" 0 "Normal Operation" ;
VAL_ 201 EngRunng 1 "true" 0 "false" ;
VAL_ 201 EngOffTmVDA 1 "VirtualDeviceAvailable" 0 "VirtualDeviceUnavailable" ;
VAL_ 300 MotStBlt2UnblIO 1 "true" 0 "false" ;
VAL_ 300 MotStBlt2FldIO 1 "true" 0 "false" ;
VAL_ 501 TrnsShftLvrPosV 1 "Invalid" 0 "Valid" ;
VAL_ 501 TrnsShftLvrPos 15 "Lever Position Unknown" 11 "Forward Range H" 10 "Forward Range G" 9 "Forward Range F" 8 "Forward Range E" 7 "Forward Range D" 6 "Forward Range C" 5 "Forward Range B" 4 "Forward Range A" 3 "Neutral Range" 2 "Reverse Range" 1 "Park Range" 0 "Between Ranges" ;
VAL_ 501 TrnShftPtrnActStat 6 "PT Protection Pattern Active" 5 "PT Non-Protection Pattern Active" 4 "Shift Pattern 4 Active" 3 "Shift Pattern 3 Active" 2 "Shift Pattern 2 Active" 1 "Shift Pattern 1 Active" 0 "Default Shift Pattern Active" ;
VAL_ 501 TransEstGearV 1 "Invalid" 0 "Valid" ;
VAL_ 501 TransEstGear 15 "Park Gear" 14 "Reverse Gear" 13 "Neutral Gear" 12 "CVT Forward Gear" 11 "EVT Mode 2" 10 "EVT Mode 1" 8 "Eighth Gear" 7 "Seventh Gear" 6 "Sixth Gear" 5 "Fifth Gear" 4 "Fourth Gear" 3 "Third Gear" 2 "Second Gear" 1 "First Gear" 0 "Not Supported" ;
VAL_ 501 TransTUDMdStat 2 "Electronic Range Select Active" 1 "Driver Shift Control Active" 0 "No Activation" ;
VAL_ 501 TrnsSftMdStat 3 "Automatic Grade Braking Mode" 2 "Lift-Foot Cornering Mode" 1 "Performance Mode" 0 "No Override Mode" ;
VAL_ 1920 DTCI_CurrentStatus_780 1 "true" 0 "false" ;
VAL_ 1920 DTCI_WrnIndRqdSt_780 1 "true" 0 "false" ;
VAL_ 1920 DTCIUnused7_780 1 "true" 0 "false" ;
VAL_ 1920 DTCIUnused6_780 1 "true" 0 "false" ;
VAL_ 1920 DTCIUnused5_780 1 "true" 0 "false" ;
VAL_ 1920 DTCIUnused4_780 1 "true" 0 "false" ;
VAL_ 1920 DTCIUnused3_780 1 "true" 0 "false" ;
VAL_ 1920 DTCIUnused2_780 1 "true" 0 "false" ;
VAL_ 1920 DTCIUnused1_780 1 "true" 0 "false" ;
VAL_ 1920 DTCI_TstNPsdPwrUpSt_780 1 "true" 0 "false" ;
VAL_ 1920 DTCI_TstNPsdCdClrdSt_780 1 "true" 0 "false" ;
VAL_ 1920 DTCI_TstFldPwrUpSt_780 1 "true" 0 "false" ;
VAL_ 1920 DTCI_TstFldCdClrdStat_780 1 "true" 0 "false" ;
VAL_ 1920 DTCI_HistStat_780 1 "true" 0 "false" ;
VAL_ 1920 DTCI_DTCTriggered_780 1 "true" 0 "false" ;
VAL_ 1920 DTCI_DTCFaultType_780 3 "Type C" 2 "Type B" 1 "Type A" 0 "Not Supported" ;
VAL_ 1920 DTCI_CodeSupported_780 1 "true" 0 "false" ;
VAL_ 381 StrAngSnsPolRat 0 "Not Passed" 1 "Passed" ;
VAL_ 381 ActVehAccelV 1 "Invalid" 0 "Valid" ;
VAL_ 381 LatAccSnsPolRat 0 "Not Passed" 1 "Passed" ;
VAL_ 386 VehDynOvrUndrStrV 1 "Invalid" 0 "Valid" ;
VAL_ 386 VSELongAccLoResV 1 "Invalid" 0 "Valid" ;
VAL_ 386 VSEAct 1 "true" 0 "false" ;
VAL_ 386 VehStabEnhmntStat 4 "Not Ready" 3 "Warming Up" 2 "Fault" 1 "Active" 0 "Inactive" ;
VAL_ 386 VehStabEnhmntMd 2 "Competitive" 1 "Normal" 0 "Off" ;
VAL_ 842 WhlRotDrctnlSRtNDrvn 0 "Unknown" 1 "Forward" 2 "Reverse" 3 "Not Supported" 4 "Failed" 5 "Reserved 1" 6 "Reserved 2" 7 "Reserved 3" ;
VAL_ 842 WhlRotDrctnlStLfNDrvn 0 "Unknown" 1 "Forward" 2 "Reverse" 3 "Not Supported" 4 "Failed" 5 "Reserved 1" 6 "Reserved 2" 7 "Reserved 3" ;
VAL_ 842 WhlGrndVlctyRtNnDrvnV 1 "Invalid" 0 "Valid" ;
VAL_ 842 WhlGrndVlctyLftNnDrvnV 1 "Invalid" 0 "Valid" ;
VAL_ 840 WhlRotDrctnlStRtDrvn 0 "Unknown" 1 "Forward" 2 "Reverse" 3 "Not Supported" 4 "Failed" 5 "Reserved 1" 6 "Reserved 2" 7 "Reserved 3" ;
VAL_ 840 WhlRotDrctnlStLftDrvn 0 "Unknown" 1 "Forward" 2 "Reverse" 3 "Not Supported" 4 "Failed" 5 "Reserved 1" 6 "Reserved 2" 7 "Reserved 3" ;
VAL_ 840 WhlGrndVlctyRtDrvnV 1 "Invalid" 0 "Valid" ;
VAL_ 840 WhlGrndVlctyLftDrvnV 1 "Invalid" 0 "Valid" ;
VAL_ 489 VSELatAccV 1 "Invalid" 0 "Valid" ;
VAL_ 489 VhDynCntlSysSt 7 "Driver Disabled" 6 "Enhanced Operation" 5 "Calibrating" 4 "Warming Up" 3 "Permanently Failed" 2 "Temporarily Inhibited" 1 "Reduced Function" 0 "Normal Operation" ;
VAL_ 489 VehDynYawRateV 1 "Invalid" 0 "Valid" ;
VAL_ 489 TCSysEnbld 1 "true" 0 "false" ;
VAL_ 489 TCSysAtv 1 "true" 0 "false" ;
VAL_ 489 SprTireSt 2 "Spare Detected" 1 "No Spare Detected" 0 "Undetermined" ;
VAL_ 489 BrkPdlDrvAppPrsDetcdV 1 "Invalid" 0 "Valid" ;
VAL_ 489 BrkPdlDrvAppPrsDetcd 1 "true" 0 "false" ;
VAL_ 485 StrWhAngGrdV 1 "Invalid" 0 "Valid" ;
VAL_ 485 StrWhAngGrdMsk 0 "Don't Use Data" 1 "Use Data" ;
VAL_ 485 StrWhAngMsk 0 "Don't Use Data" 1 "Use Data" ;
VAL_ 485 StrWhlAngSenTyp 0 "Type 1" 1 "Type 2" 2 "Type 3" 3 "Type 4" ;
VAL_ 485 StrWhlAngSenCalStat 2 "Calibrated" 1 "Estimated" 0 "Unknown" ;
VAL_ 485 StrWhAngV 1 "Invalid" 0 "Valid" ;
VAL_ 803 WhlBdySnsHmPosLrnd 1 "true" 0 "false" ;
VAL_ 803 WBRP_RtFrtV 1 "Invalid" 0 "Valid" ;
VAL_ 803 WBRP_RtRrV 1 "Invalid" 0 "Valid" ;
VAL_ 803 WBRP_LftRrV 1 "Invalid" 0 "Valid" ;
VAL_ 803 WBRP_LftFrtV 1 "Invalid" 0 "Valid" ;
VAL_ 568 SeatBltPerfMdRq 7 "Performance Mode 7" 6 "Performance Mode 6" 5 "Performance Mode 5" 4 "Performance Mode 4" 3 "Performance Mode 3" 2 "Performance Mode 2" 1 "Performance Mode 1" 0 "No Action" ;
VAL_ 568 StgSysPerfMdRq 7 "Performance Mode 7" 6 "Performance Mode 6" 5 "Performance Mode 5" 4 "Performance Mode 4" 3 "Performance Mode 3" 2 "Performance Mode 2" 1 "Performance Mode 1" 0 "No Action" ;
VAL_ 542 BrkSysToEBOOSTDiagMd 3 "Diagnostic Mode 3" 2 "Diagnostic Mode 2" 1 "Diagnostic Mode 1" 0 "No Diagnostic Mode" ;
VAL_ 542 BrkSysRlrBnchSmtdSpdV 1 "Invalid" 0 "Valid" ;
VAL_ 542 BrkSysTgtPresReqAct 1 "true" 0 "false" ;
VAL_ 542 BrkSysHgstEstWhlPsrV 1 "Invalid" 0 "Valid" ;
VAL_ 539 BrkSysTgtFlwRtRqAct 1 "true" 0 "false" ;
VAL_ 539 BrkSysPrsBdgTgtReqV 1 "Invalid" 0 "Valid" ;
VAL_ 539 BrkSysPresTrgtDrvrV 1 "Invalid" 0 "Valid" ;
VAL_ 539 BrkSyFrcBdgTgtRqActSt 2 "Active" 1 "Hold" 0 "Inactive" ;
VAL_ 539 BrkSysABSFldRetnAct 1 "true" 0 "false" ;
VAL_ 539 BrkSysUncmpMsCylPresV 1 "Invalid" 0 "Valid" ;
VAL_ 537 EBrkAstRnotPresCapV 1 "Invalid" 0 "Valid" ;
VAL_ 537 EBrkAstToBrkSysDiagMd 3 "Diagnostic Mode 3" 2 "Diagnostic Mode 2" 1 "Diagnostic Mode 1" 0 "No Diagnostic Mode" ;
VAL_ 537 EBrkAstHydBrkCmpnRq 1 "true" 0 "false" ;
VAL_ 537 EBrkAstStat 7 "Faulted" 6 "Temporarily Failed" 5 "Not Used" 4 "Not Used" 3 "Not Used" 2 "Normal" 1 "Initializing" 0 "Not Initialized" ;
VAL_ 537 EBrkAstDrvrApldBrkPdlV 1 "Invalid" 0 "Valid" ;
VAL_ 537 EBrkAstDrvrApldBrkPdl 1 "true" 0 "false" ;
SIG_GROUP_ 516 RngCntModCalIdInfo 1 : RCMCII_DataVal RCMCII_DataIndx RCMCII_DataStat;
SIG_GROUP_ 514 RngCtlModDiagStatB 1 : RCMDSB_DTCStat RCMDSB_DTCIndx;
SIG_GROUP_ 514 RngCtlModDiagStatA 1 : RCMDSA_DTCStat RCMDSA_DTCIndx;
SIG_GROUP_ 521 RngMtrStat 1 : RMS_RngMtrDfltStat RMS_RngMtrPstnV RMS_RngMtrPstnM RMS_RngMtrPstn;
SIG_GROUP_ 1931 DTCInfo_78B 1 : DTCI_CodeSupported_78B DTCI_CurrentStatus_78B DTCI_DTCFailType_78B DTCI_DTCFaultType_78B DTCI_DTCNumber_78B DTCI_DTCSource_78B DTCI_DTCTriggered_78B DTCI_HistStat_78B DTCI_TstFldCdClrdStat_78B DTCI_TstFldPwrUpSt_78B DTCI_TstNPsdCdClrdSt_78B DTCI_TstNPsdPwrUpSt_78B DTCIUnused1_78B DTCIUnused2_78B DTCIUnused3_78B DTCIUnused4_78B DTCIUnused5_78B DTCIUnused6_78B DTCIUnused7_78B DTCI_WrnIndRqdSt_78B;
SIG_GROUP_ 1923 DTCInfo_783 1 : DTCI_WrnIndRqdSt_783 DTCI_TstNPsdPwrUpSt_783 DTCI_TstNPsdCdClrdSt_783 DTCI_TstFldPwrUpSt_783 DTCI_TstFldCdClrdStat_783 DTCI_HistStat_783 DTCI_DTCTriggered_783 DTCI_DTCSource_783 DTCI_DTCNumber_783 DTCI_DTCFaultType_783 DTCI_DTCFailType_783 DTCI_CurrentStatus_783 DTCI_CodeSupported_783 DTCIUnused7_783 DTCIUnused6_783 DTCIUnused5_783 DTCIUnused4_783 DTCIUnused3_783 DTCIUnused2_783 DTCIUnused1_783;
SIG_GROUP_ 1922 DTCInfo_782 1 : DTCI_WrnIndRqdSt_782 DTCIUnused7_782 DTCIUnused6_782 DTCIUnused5_782 DTCIUnused4_782 DTCIUnused3_782 DTCIUnused2_782 DTCIUnused1_782 DTCI_TstNPsdPwrUpSt_782 DTCI_TstNPsdCdClrdSt_782 DTCI_TstFldPwrUpSt_782 DTCI_TstFldCdClrdStat_782 DTCI_HistStat_782 DTCI_DTCTriggered_782 DTCI_DTCSource_782 DTCI_DTCNumber_782 DTCI_DTCFaultType_782 DTCI_DTCFailType_782 DTCI_CurrentStatus_782 DTCI_CodeSupported_782;
SIG_GROUP_ 1921 DTCInfo_781 1 : DTCI_CurrentStatus_781 DTCI_WrnIndRqdSt_781 DTCIUnused7_781 DTCIUnused6_781 DTCIUnused5_781 DTCIUnused4_781 DTCIUnused3_781 DTCIUnused2_781 DTCIUnused1_781 DTCI_TstNPsdPwrUpSt_781 DTCI_TstNPsdCdClrdSt_781 DTCI_TstFldPwrUpSt_781 DTCI_TstFldCdClrdStat_781 DTCI_HistStat_781 DTCI_DTCTriggered_781 DTCI_DTCSource_781 DTCI_DTCNumber_781 DTCI_DTCFaultType_781 DTCI_DTCFailType_781 DTCI_CodeSupported_781;
SIG_GROUP_ 1920 DTCInfo_780 1 : DTCI_CurrentStatus_780 DTCI_WrnIndRqdSt_780 DTCIUnused7_780 DTCIUnused6_780 DTCIUnused5_780 DTCIUnused4_780 DTCIUnused3_780 DTCIUnused2_780 DTCIUnused1_780 DTCI_TstNPsdPwrUpSt_780 DTCI_TstNPsdCdClrdSt_780 DTCI_TstFldPwrUpSt_780 DTCI_TstFldCdClrdStat_780 DTCI_HistStat_780 DTCI_DTCTriggered_780 DTCI_DTCSource_780 DTCI_DTCNumber_780 DTCI_DTCFaultType_780 DTCI_DTCFailType_780 DTCI_CodeSupported_780;
SIG_GROUP_ 803 WhlBdyRelPos 1 : WBRP_ARC WBRP_Tmestmp WBRP_RtFrtV WBRP_RtFrt WBRP_RtRrV WBRP_RtRr WBRP_LftRrV WBRP_LftRr WBRP_LftFrtV WBRP_LftFrt;
SIG_GROUP_ 871 FrtCmModRsp 1 : FCMR_RptdChlng FCMR_Answr;
